VERSION ""

NS_ :

BS_:

BU_: AGSM BCM BSM CDCM DASM DCSM DCTM DIAG_TEST DTCM ECM ECM2 IPC ORC RFHM TBM TCM

BO_ 599 AIRBAG1: 8 ORC
 SG_ AirBagFailSts : 7|2@0+ (1,0) [0|3] "-" IPC,TBM
 SG_ PsngrBagChargeSts : 5|2@0+ (1,0) [0|2] "-" IPC
 SG_ SBR1RowCentralSeatBuckleFailSts : 0|2@0+ (1,0) [0|2] "" BSM,DASM,IPC,TBM
 SG_ SBR1RowCentralSeatConfigSts : 1|1@0+ (1,0) [0|1] "-" BSM,DASM,IPC,TBM
 SG_ SBR1RowCentralSeatPPDFailSts : 14|2@0+ (1,0) [0|2] "" BSM,DASM,IPC,TBM
 SG_ SBR1RowCentralSeatSts : 12|3@0+ (1,0) [0|6] "-" BSM,DASM,IPC,TBM
 SG_ SBR1RowDriverSeatConfigSts : 9|1@0+ (1,0) [0|1] "-" BSM,DASM,IPC,TBM
 SG_ SBR1RowDriverSeatFailSts : 8|2@0+ (1,0) [0|2] "" BSM,DASM,IPC,TBM
 SG_ SBR1RowDriverSeatSts : 22|2@0+ (1,0) [0|2] "-" BSM,DASM,DCTM,IPC,TBM,TCM
 SG_ SBR1RowPsngrSeatBuckleFailSts : 19|2@0+ (1,0) [0|2] "" BSM,DASM,IPC,TBM
 SG_ SBR1RowPsngrSeatConfigSts : 20|1@0+ (1,0) [0|1] "-" BSM,DASM,IPC,TBM
 SG_ SBR1RowPsngrSeatPPDFailSts : 17|2@0+ (1,0) [0|2] "" BSM,DASM,IPC,TBM
 SG_ SBR1RowPsngrSeatSts : 31|3@0+ (1,0) [0|6] "-" BSM,DASM,IPC,TBM
 SG_ SBR2RowCentralSeatConfigSts : 28|1@0+ (1,0) [0|1] "-" IPC,TBM
 SG_ SBR2RowCentralSeatSts : 25|2@0+ (1,0) [0|2] "-" IPC,TBM
 SG_ SBR2RowLeftSeatConfigSts : 39|1@0+ (1,0) [0|1] "-" IPC,TBM
 SG_ SBR2RowLeftSeatSts : 36|2@0+ (1,0) [0|2] "-" IPC,TBM
 SG_ SBR2RowRightSeatConfigSts : 34|1@0+ (1,0) [0|1] "-" IPC,TBM
 SG_ SBR2RowRightSeatSts : 47|2@0+ (1,0) [0|2] "-" IPC,TBM

BO_ 1447 AIRBAG2: 8 ORC
 SG_ CRC_A2 : 63|8@0+ (1,0) [0|255] "" BSM,ECM
 SG_ DrvSbltUnFltr : 7|3@0+ (1,0) [0|6] "" BSM,ECM
 SG_ MessageCounter_A2 : 51|4@0+ (1,0) [0|15] "" BSM,ECM

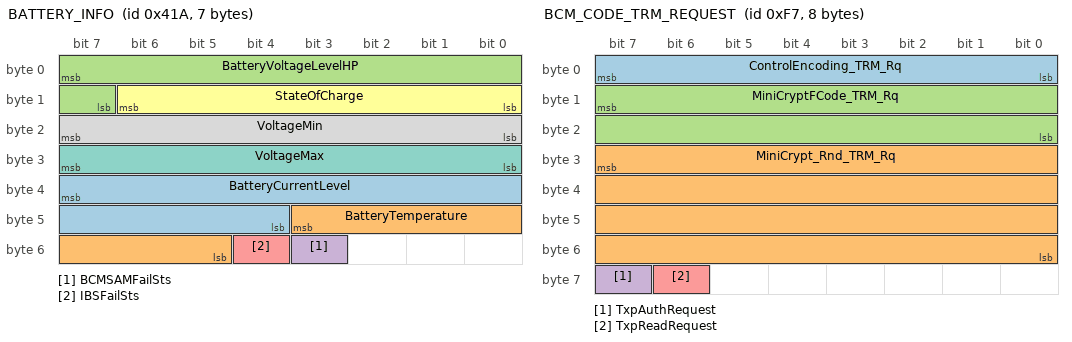
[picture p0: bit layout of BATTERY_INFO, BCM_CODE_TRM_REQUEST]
BO_ 1050 BATTERY_INFO: 7 BCM
 SG_ BatteryCurrentLevel : 39|12@0+ (0.1,-250) [-250|159.5] "A" ECM
 SG_ BatteryTemperature : 43|7@0+ (1,-30) [-30|97] "°C" BCM,ECM
 SG_ BatteryVoltageLevelHP : 7|9@0+ (0.025,4) [4|16.775] "Volt" DTCM,ECM,ORC,RFHM
 SG_ BCMSAMFailSts : 51|1@0+ (1,0) [0|1] "-" ECM
 SG_ IBSFailSts : 52|1@0+ (1,0) [0|1] "-" ECM
 SG_ StateOfCharge : 14|7@0+ (1,0) [0|127] "%" DCTM,ECM,TCM
 SG_ VoltageMax : 31|8@0+ (0.025,10.6) [10.6|16.975] "Volt" ECM
 SG_ VoltageMin : 23|8@0+ (0.025,10.6) [10.6|16.975] "Volt" ECM

BO_ 247 BCM_CODE_TRM_REQUEST: 8 BCM
 SG_ ControlEncoding_TRM_Rq : 7|8@0+ (1,0) [0|255] "-" RFHM
 SG_ MiniCrypt_Rnd_TRM_Rq : 31|32@0+ (1,0) [0|4294967295] "-" RFHM
 SG_ MiniCryptFCode_TRM_Rq : 15|16@0+ (1,0) [0|65535] "-" RFHM
 SG_ TxpAuthRequest : 63|1@0+ (1,0) [0|1] "-" RFHM
 SG_ TxpReadRequest : 62|1@0+ (1,0) [0|1] "-" RFHM

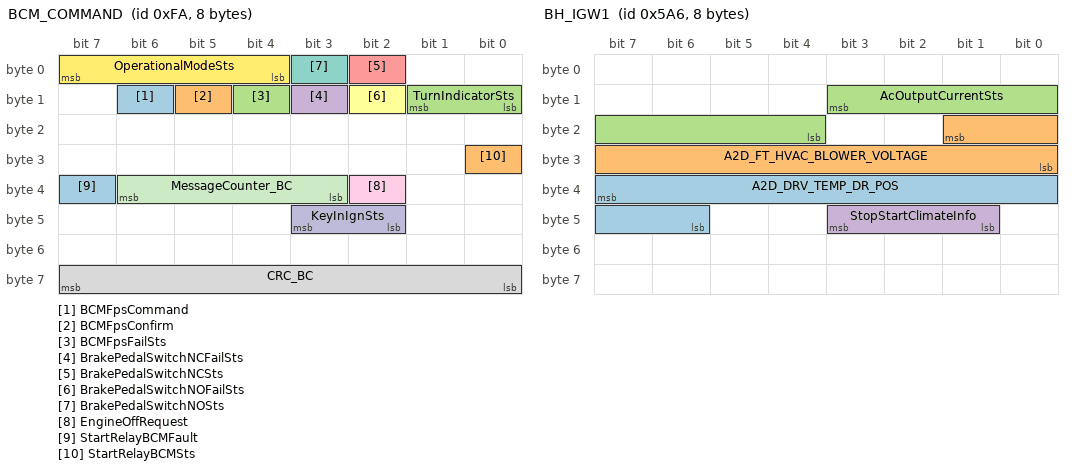
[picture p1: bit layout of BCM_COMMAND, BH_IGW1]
BO_ 250 BCM_COMMAND: 8 BCM
 SG_ BCMFpsCommand : 14|1@0+ (1,0) [0|1] "-" ECM
 SG_ BCMFpsConfirm : 13|1@0+ (1,0) [0|1] "-" ECM
 SG_ BCMFpsFailSts : 12|1@0+ (1,0) [0|1] "-" ECM
 SG_ BrakePedalSwitchNCFailSts : 11|1@0+ (1,0) [0|1] "-" DASM
 SG_ BrakePedalSwitchNCSts : 2|1@0+ (1,0) [0|1] "-" DASM
 SG_ BrakePedalSwitchNOFailSts : 10|1@0+ (1,0) [0|1] "-" DASM
 SG_ BrakePedalSwitchNOSts : 3|1@0+ (1,0) [0|1] "-" DASM
 SG_ CRC_BC : 63|8@0+ (1,0) [0|255] "" AGSM,DASM,DCSM,DCTM,DTCM,ECM,RFHM,TCM
 SG_ EngineOffRequest : 34|1@0+ (1,0) [0|1] "-" ECM
 SG_ KeyInIgnSts : 43|2@0+ (1,0) [0|2] "" RFHM
 SG_ MessageCounter_BC : 38|4@0+ (1,0) [0|15] "-" AGSM,DASM,DCSM,DCTM,DTCM,ECM,RFHM,TCM
 SG_ OperationalModeSts : 7|4@0+ (1,0) [0|15] "" AGSM,CDCM,DASM,DCSM,DCTM,DTCM,ECM,ECM2,IPC,RFHM,TCM
 SG_ StartRelayBCMFault : 39|1@0+ (1,0) [0|1] "" ECM
 SG_ StartRelayBCMSts : 24|1@0+ (1,0) [0|1] "" ECM
 SG_ TurnIndicatorSts : 9|2@0+ (1,0) [0|3] "-" DASM

BO_ 1994 BCM_IGNITION_ON_COUNTER: 2 BCM
 SG_ IgnitionOnCounter : 7|16@0+ (1,0) [0|65535] "-" AGSM,DASM,DCSM,DCTM,DTCM,ECM,IPC,RFHM,TCM

BO_ 245 BCM_MINICRYPT_ACK: 1 BCM
 SG_ MinicryptReceptionSts : 7|1@0+ (1,0) [0|1] "-" RFHM

BO_ 1446 BH_IGW1: 8 BCM
 SG_ A2D_DRV_TEMP_DR_POS : 39|10@0+ (0.0048828125,0) [0|4.9951171875] "Volt" ECM
 SG_ A2D_FT_HVAC_BLOWER_VOLTAGE : 17|10@0+ (0.0048828125,0) [0|4.9951171875] "Volt" ECM
 SG_ AcOutputCurrentSts : 11|8@0+ (0.008,0) [0|2.04] "A" ECM
 SG_ StopStartClimateInfo : 43|3@0+ (1,0) [0|5] "-" ECM

BO_ 748 BODY1: 8 BCM
 SG_ FrontWiperMoveSts : 21|1@0+ (1,0) [0|1] "" ECM
 SG_ RemStartActiveEPB : 20|1@0+ (1,0) [0|1] "" BSM

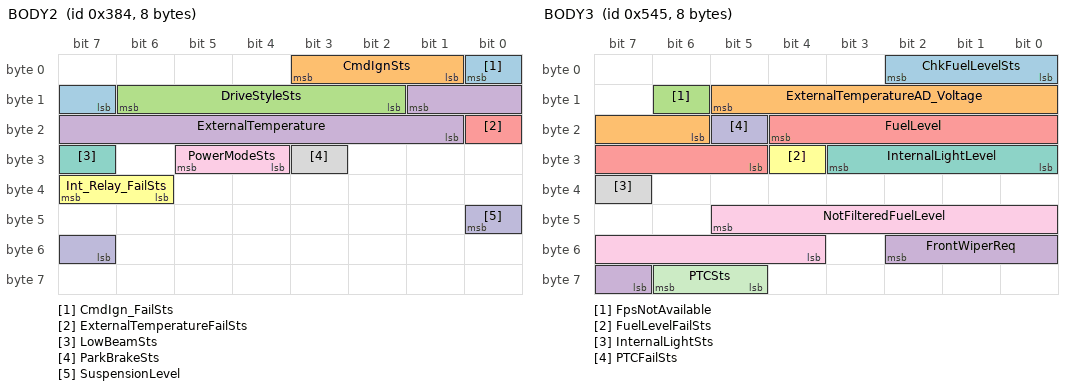
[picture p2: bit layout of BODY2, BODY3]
BO_ 900 BODY2: 8 BCM
 SG_ CmdIgn_FailSts : 0|2@0+ (1,0) [0|3] "" AGSM,CDCM,DASM,DCSM,DCTM,DTCM,ECM,ECM2,IPC,RFHM,TCM
 SG_ CmdIgnSts : 3|3@0+ (1,0) [0|7] "" AGSM,CDCM,DASM,DCSM,DCTM,DTCM,ECM,ECM2,IPC,RFHM,TCM
 SG_ DriveStyleSts : 14|5@0+ (1,0) [0|31] "-" CDCM,DASM,DCTM,DTCM,ECM,IPC,TCM
 SG_ ExternalTemperature : 9|9@0+ (0.5,-85) [-85|170] "°C" CDCM,DCTM,DTCM,ECM,RFHM,TCM
 SG_ ExternalTemperatureFailSts : 16|1@0+ (1,0) [0|1] "" CDCM,DCTM,DTCM,ECM,RFHM,TCM
 SG_ Int_Relay_FailSts : 39|2@0+ (1,0) [0|2] "" Vector__XXX
 SG_ LowBeamSts : 31|1@0+ (1,0) [0|1] "" RFHM
 SG_ ParkBrakeSts : 27|1@0+ (1,0) [0|1] "-" ECM,TCM
 SG_ PowerModeSts : 29|2@0+ (1,0) [0|3] "-" ECM,IPC,RFHM
 SG_ SuspensionLevel : 40|2@0+ (1,0) [0|1] "-" CDCM

BO_ 1349 BODY3: 8 BCM
 SG_ ChkFuelLevelSts : 2|3@0+ (1,0) [0|7] "-" ECM
 SG_ ExternalTemperatureAD_Voltage : 13|8@0+ (0.019607843,0) [0|4.9999992] "Volt" ECM
 SG_ FpsNotAvailable : 14|1@0+ (1,0) [0|1] "" IPC
 SG_ FrontWiperReq : 50|4@0+ (1,0) [0|3] "" BSM,CDCM
 SG_ FuelLevel : 20|8@0+ (1,0) [0|255] "%" ECM,IPC,ORC
 SG_ FuelLevelFailSts : 28|1@0+ (1,0) [0|1] "" ECM,IPC
 SG_ InternalLightLevel : 27|4@0+ (1,0) [0|15] "-" AGSM,DCSM,IPC,RFHM
 SG_ InternalLightSts : 39|1@0+ (1,0) [0|1] "-" AGSM,DCSM,IPC,ORC,RFHM,TBM
 SG_ NotFilteredFuelLevel : 45|10@0+ (2,0) [0|835.7] "Ohm" ECM
 SG_ PTCFailSts : 21|1@0+ (1,0) [0|1] "-" ECM
 SG_ PTCSts : 62|2@0+ (1,0) [0|3] "-" ECM

BO_ 1201 BODY4: 8 BCM
 SG_ BatteryStateOfFunction : 28|6@0+ (0.09375,6) [6|11.90625] "V" ECM
 SG_ BonnetSts : 4|1@0+ (1,0) [0|1] "" Vector__XXX
 SG_ CompressorACReqSts : 37|1@0+ (1,0) [0|1] "-" ECM
 SG_ DriverDoorFailSts : 3|1@0+ (1,0) [0|1] "-" Vector__XXX
 SG_ DriverDoorSts : 0|1@0+ (1,0) [0|1] "" BSM,DCTM,IPC,RFHM,TCM
 SG_ ExteriorRearReleaseSwitchSts : 33|1@0+ (1,0) [0|1] "" RFHM
 SG_ FHeatedWindowSts : 10|1@0+ (1,0) [0|1] "" ECM
 SG_ FOBSearchRequest : 2|2@0+ (1,0) [0|3] "" RFHM
 SG_ LHRDoorSts : 14|1@0+ (1,0) [0|1] "-" RFHM
 SG_ PsngrDoorSts : 15|1@0+ (1,0) [0|1] "-" RFHM
 SG_ Recalibration : 35|1@0+ (1,0) [0|1] "" BCM,ECM,IPC
 SG_ RemSt_InhibitSts : 19|6@0+ (1,0) [0|62] "" IPC
 SG_ RemStActvSts : 29|1@0+ (1,0) [0|1] "" DCTM,ECM,IPC,ORC,RFHM,TCM
 SG_ RHatchSts : 12|1@0+ (1,0) [0|1] "-" RFHM
 SG_ RHeatedWindowSts : 11|1@0+ (1,0) [0|1] "" ECM
 SG_ RHRDoorSts : 13|1@0+ (1,0) [0|1] "-" RFHM
 SG_ SpSt_Pad1 : 45|3@0+ (1,0) [0|7] "" ECM,TCM
 SG_ TheftAlarmStatus : 22|3@0+ (1,0) [0|6] "" RFHM

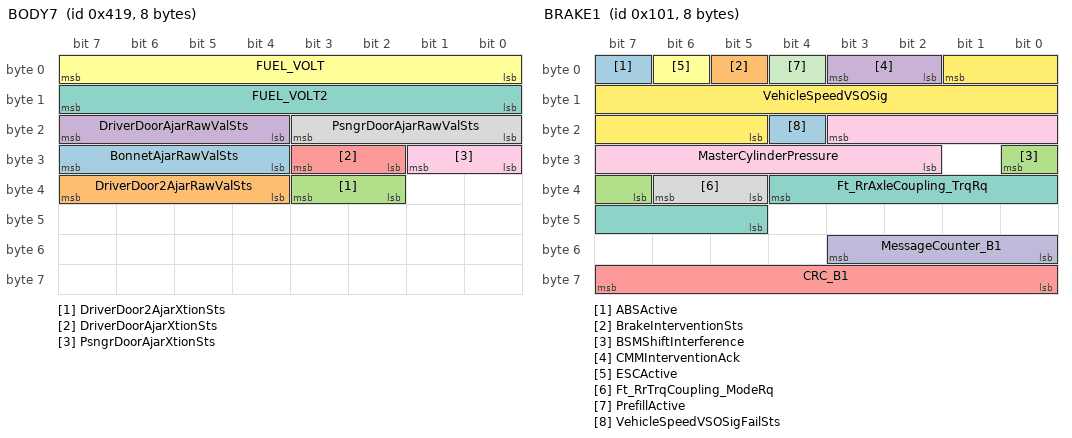
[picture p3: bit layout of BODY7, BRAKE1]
BO_ 1049 BODY7: 8 BCM
 SG_ BonnetAjarRawValSts : 31|4@0+ (1,0) [0|15] "" ECM
 SG_ DriverDoor2AjarRawValSts : 39|4@0+ (1,0) [0|14] "-" ECM
 SG_ DriverDoor2AjarXtionSts : 35|2@0+ (1,0) [0|1] "-" ECM
 SG_ DriverDoorAjarRawValSts : 23|4@0+ (1,0) [0|15] "" ECM
 SG_ DriverDoorAjarXtionSts : 27|2@0+ (1,0) [0|1] "-" ECM
 SG_ FUEL_VOLT : 7|8@0+ (0.019607843,0) [0|4.98] "Volt" ECM
 SG_ FUEL_VOLT2 : 15|8@0+ (0.019607843,0) [0|4.98] "Volt" Vector__XXX
 SG_ PsngrDoorAjarRawValSts : 19|4@0+ (1,0) [0|15] "" ECM
 SG_ PsngrDoorAjarXtionSts : 25|2@0+ (1,0) [0|1] "-" ECM

BO_ 497 BRAKE_TRANSM1: 8 BSM
 SG_ BrkBstrVac : 7|8@0+ (0.55,-119.7) [0|20] "kPa" ORC

BO_ 257 BRAKE1: 8 BSM
 SG_ ABSActive : 7|1@0+ (1,0) [0|1] "" CDCM,DASM,DCTM,DTCM,ECM,ORC,TCM
 SG_ BrakeInterventionSts : 5|1@0+ (1,0) [0|1] "" DASM,DCTM,DTCM,ECM,ORC,TCM
 SG_ BSMShiftInterference : 24|2@0+ (1,0) [0|2] "" DCTM,TCM
 SG_ CMMInterventionAck : 3|2@0+ (1,0) [0|3] "" DASM
 SG_ CRC_B1 : 63|8@0+ (1,0) [0|255] "" BCM,CDCM,DASM,DCTM,DTCM,ECM,RFHM,TCM
 SG_ ESCActive : 6|1@0+ (1,0) [0|1] "" CDCM,DASM,DCTM,DTCM,ECM,ORC,TCM
 SG_ Ft_RrAxleCoupling_TrqRq : 36|8@0+ (12,0) [0|3060] "Nm" CDCM,DTCM
 SG_ Ft_RrTrqCoupling_ModeRq : 38|2@0+ (1,0) [0|3] "" CDCM,DTCM
 SG_ MasterCylinderPressure : 19|10@0+ (0.25,0) [0|255.5] "bar" CDCM,DASM,DCTM,DTCM,ECM,ORC,TCM
 SG_ MessageCounter_B1 : 51|4@0+ (1,0) [0|15] "" BCM,CDCM,DASM,DCTM,DTCM,ECM,RFHM,TCM
 SG_ PrefillActive : 4|1@0+ (1,0) [0|1] "" DASM,ORC
 SG_ VehicleSpeedVSOSig : 1|13@0+ (0.0625,0) [0|511.875] "Km/h" BCM,DASM,DCTM,ECM,IPC,ORC,RFHM,TBM,TCM
 SG_ VehicleSpeedVSOSigFailSts : 20|1@0+ (1,0) [0|1] "" BCM,DASM,DCTM,ECM,IPC,ORC,RFHM,TBM,TCM

BO_ 506 BRAKE10: 8 BSM
 SG_ BrkPrss_One : 7|10@0+ (0.00488,0) [0|4.995] "V" ECM

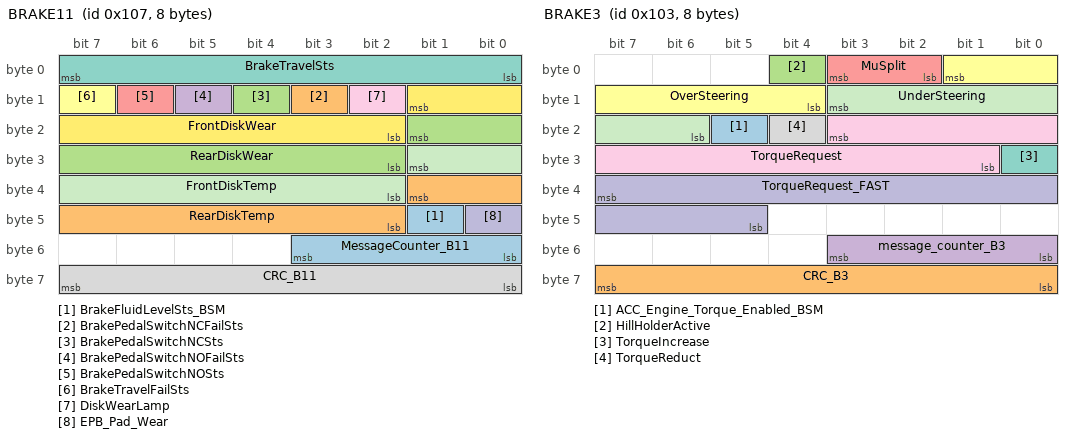
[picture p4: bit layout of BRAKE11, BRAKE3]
BO_ 263 BRAKE11: 8 BSM
 SG_ BrakeFluidLevelSts_BSM : 41|1@0+ (1,0) [0|1] "" BCM,IPC
 SG_ BrakePedalSwitchNCFailSts : 11|1@0+ (1,0) [0|1] "" BCM,CDCM,DASM,DCTM,DTCM,ECM,RFHM,TCM
 SG_ BrakePedalSwitchNCSts : 12|1@0+ (1,0) [0|1] "" BCM,CDCM,DASM,DCTM,DTCM,ECM,RFHM,TCM
 SG_ BrakePedalSwitchNOFailSts : 13|1@0+ (1,0) [0|1] "" BCM,CDCM,DASM,DCTM,DTCM,ECM,RFHM,TCM
 SG_ BrakePedalSwitchNOSts : 14|1@0+ (1,0) [0|1] "" BCM,CDCM,DASM,DCTM,DTCM,ECM,RFHM,TCM
 SG_ BrakeTravelFailSts : 15|1@0+ (1,0) [0|1] "" BCM,DCTM,ECM,TCM
 SG_ BrakeTravelSts : 7|8@0+ (0.4,0) [0|100] "%" BCM,DCTM,ECM,TCM
 SG_ CRC_B11 : 63|8@0+ (1,0) [0|255] "" BCM,CDCM,DASM,DCTM,DTCM,ECM,RFHM,TCM
 SG_ DiskWearLamp : 10|1@0+ (1,0) [0|1] "" IPC
 SG_ EPB_Pad_Wear : 40|1@0+ (1,0) [0|1] "" IPC
 SG_ FrontDiskTemp : 25|8@0+ (3.13,0) [0|800] "°C" BCM
 SG_ FrontDiskWear : 9|8@0+ (0.25,0) [0|63.75] "%" Vector__XXX
 SG_ MessageCounter_B11 : 51|4@0+ (1,0) [0|15] "" BCM,CDCM,DASM,DCTM,DTCM,ECM,RFHM,TCM
 SG_ RearDiskTemp : 33|8@0+ (3.13,0) [0|800] "°C" BCM
 SG_ RearDiskWear : 17|8@0+ (0.25,0) [0|63.75] "%" Vector__XXX

BO_ 259 BRAKE3: 8 BSM
 SG_ ACC_Engine_Torque_Enabled_BSM : 21|1@0+ (1,0) [0|1] "-" ECM
 SG_ CRC_B3 : 63|8@0+ (1,0) [0|255] "" CDCM,DASM,DCTM,ECM,TCM
 SG_ HillHolderActive : 4|1@0+ (1,0) [0|1] "" DCTM,ECM,ORC,TCM
 SG_ message_counter_B3 : 51|4@0+ (1,0) [0|15] "" CDCM,DASM,DCTM,ECM,TCM
 SG_ MuSplit : 3|2@0+ (1,0) [0|2] "" CDCM
 SG_ OverSteering : 1|6@0+ (2,0) [0|124] "%" Vector__XXX
 SG_ TorqueIncrease : 24|1@0+ (1,0) [0|1] "" DCTM,ECM,ORC,TCM
 SG_ TorqueReduct : 20|1@0+ (1,0) [0|1] "" DCTM,ECM,ORC,TCM
 SG_ TorqueRequest : 19|11@0+ (1,-500) [-500|1546] "" DCTM,ECM,ORC,TCM
 SG_ TorqueRequest_FAST : 39|11@0+ (1,-500) [-500|1546] "" ECM
 SG_ UnderSteering : 11|6@0+ (2,0) [0|124] "%" Vector__XXX

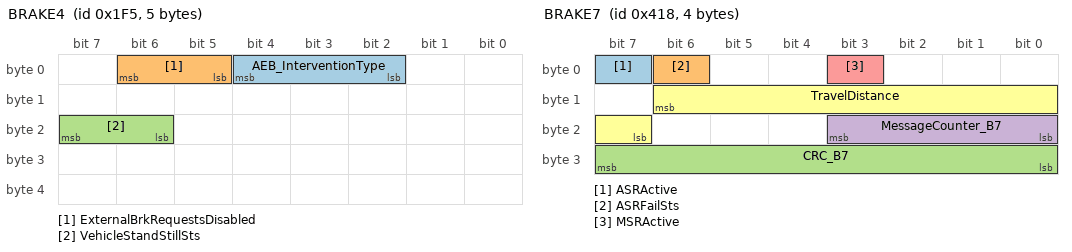
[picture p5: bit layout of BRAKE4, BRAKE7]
BO_ 501 BRAKE4: 5 BSM
 SG_ AEB_InterventionType : 4|3@0+ (1,0) [0|7] "" DASM,ORC
 SG_ ExternalBrkRequestsDisabled : 6|2@0+ (1,0) [0|2] "" DASM
 SG_ VehicleStandStillSts : 23|2@0+ (1,0) [0|2] "" CDCM,DASM,ECM

BO_ 498 BRAKE6: 8 BSM
 SG_ ACCFSafe : 7|8@0+ (1,0) [0|255] "" DASM
 SG_ Brk_Jrk_Resp : 13|1@0+ (1,0) [0|1] "-" DASM,ORC
 SG_ Brk_Thermdl : 12|1@0+ (1,0) [0|1] "" DASM

BO_ 1048 BRAKE7: 4 BSM
 SG_ ASRActive : 7|1@0+ (1,0) [0|1] "-" CDCM,DASM,DCTM,ECM,ORC,TCM
 SG_ ASRFailSts : 6|1@0+ (1,0) [0|1] "" CDCM
 SG_ CRC_B7 : 31|8@0+ (1,0) [0|255] "" CDCM,DASM,DCTM,ECM,TCM
 SG_ MessageCounter_B7 : 19|4@0+ (1,0) [0|15] "" CDCM,DASM,DCTM,ECM,TCM
 SG_ MSRActive : 3|1@0+ (1,0) [0|1] "-" DASM,DCTM,ECM,ORC,TCM
 SG_ TravelDistance : 14|8@0+ (1,0) [0|255] "m" BCM,ECM,IPC,ORC

BO_ 1199 BRAKE8: 8 BSM
 SG_ ABSFailSts : 7|1@0+ (1,0) [0|1] "-" CDCM,DCTM,DTCM,IPC,ORC,TCM
 SG_ ACCEngaged : 11|1@0+ (1,0) [0|1] "" ECM,TCM
 SG_ BSM_BLC_Active : 26|1@0+ (1,0) [0|1] "" BCM
 SG_ BSMSysSts : 47|2@0+ (1,0) [0|3] "" DASM,DCTM,ECM,TCM
 SG_ CMMIntervention : 6|1@0+ (1,0) [0|1] "-" ECM
 SG_ DSTFailSts : 5|1@0+ (1,0) [0|1] "-" BCM,IPC,ORC
 SG_ EBDFailSts : 4|1@0+ (1,0) [0|1] "-" IPC,ORC
 SG_ ERMActive : 33|1@0+ (1,0) [0|1] "" DASM,ORC
 SG_ ESCFailSts : 2|1@0+ (1,0) [0|1] "-" BCM,CDCM,DASM,DCTM,DTCM,IPC,ORC,TCM
 SG_ ESCIntervention : 3|1@0+ (1,0) [0|1] "-" DCTM,IPC,ORC,TCM
 SG_ Function2Sts : 10|1@0+ (1,0) [0|1] "-" CDCM,DASM,IPC
 SG_ FunctionFailSts : 15|1@0+ (1,0) [0|1] "-" IPC
 SG_ FunctionIntervention : 1|1@0+ (1,0) [0|1] "-" IPC,ORC
 SG_ FunctionSts : 0|1@0+ (1,0) [0|1] "-" DASM,DCTM,DTCM,IPC,ORC,TCM
 SG_ HillHolderFailSts : 14|1@0+ (1,0) [0|1] "-" IPC,ORC
 SG_ RollsModeAct : 12|1@0+ (1,0) [0|1] "" BCM,DASM,ECM
 SG_ TSCActive : 32|1@0+ (1,0) [0|1] "" DASM,ORC

BO_ 1453 BRAKE9: 8 BSM
 SG_ DsblFuelShutOff_ACC_BSM : 15|1@0+ (1,0) [0|1] "-" ECM

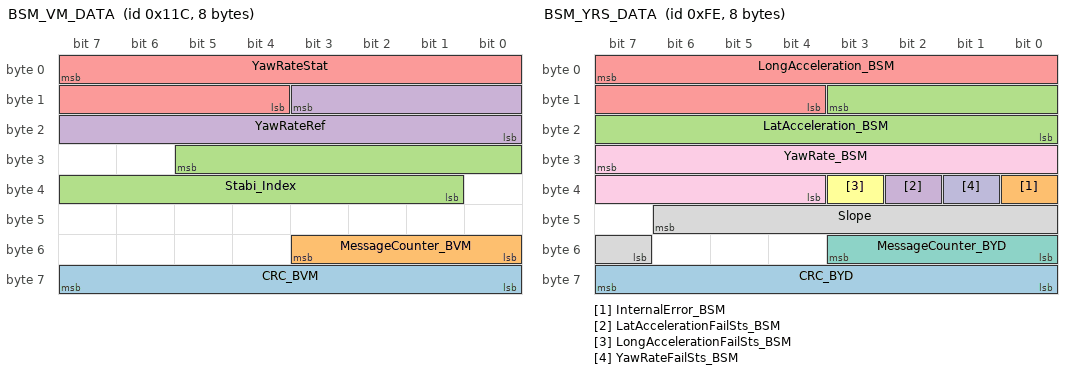
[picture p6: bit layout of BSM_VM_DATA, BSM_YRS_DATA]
BO_ 284 BSM_VM_DATA: 8 BSM
 SG_ CRC_BVM : 63|8@0+ (1,0) [0|255] "-" Vector__XXX
 SG_ MessageCounter_BVM : 51|4@0+ (1,0) [0|15] "-" Vector__XXX
 SG_ Stabi_Index : 29|13@0+ (0.08,-100) [-100|555.28] "%" Vector__XXX
 SG_ YawRateRef : 11|12@0+ (0.08,-93) [-93|234.52] "deg/s" Vector__XXX
 SG_ YawRateStat : 7|12@0+ (0.08,-93) [-93|234.52] "deg/s" Vector__XXX

BO_ 254 BSM_YRS_DATA: 8 BSM
 SG_ CRC_BYD : 63|8@0+ (1,0) [0|255] "-" BCM,DASM,DCTM,DTCM,ECM,TCM
 SG_ InternalError_BSM : 32|1@0+ (1,0) [0|1] "-" Vector__XXX
 SG_ LatAcceleration_BSM : 11|12@0+ (0.02,-40.96) [-40.96|40.92] "m/s^2" BCM,DCTM,DTCM,ECM,IPC,TCM
 SG_ LatAccelerationFailSts_BSM : 34|1@0+ (1,0) [0|1] "-" BCM,DCTM,DTCM,IPC,TCM
 SG_ LongAcceleration_BSM : 7|12@0+ (0.02,-40.96) [-40.96|40.92] "m/s^2" BCM,DASM,DCTM,ECM,IPC,TCM
 SG_ LongAccelerationFailSts_BSM : 35|1@0+ (1,0) [0|1] "-" BCM,DASM,DCTM,ECM,IPC,TCM
 SG_ MessageCounter_BYD : 51|4@0+ (1,0) [0|15] "-" BCM,DASM,DCTM,DTCM,ECM,TCM
 SG_ Slope : 46|8@0+ (1,-100) [-100|154] "%" BCM,DCTM,ECM,TCM
 SG_ YawRate_BSM : 31|12@0+ (0.08,-163.84) [-163.84|163.68] "deg/s" BCM,DASM,DTCM,ORC
 SG_ YawRateFailSts_BSM : 33|1@0+ (1,0) [0|1] "-" BCM,DASM,DTCM

BO_ 1451 C2_IGW1: 8 BCM
 SG_ TorqueOverlayIntActivation_SPM : 0|1@0+ (1,0) [0|1] "" DASM

BO_ 288 CDCM3: 6 CDCM
 SG_ CRC_EC : 31|8@0+ (1,0) [0|255] "" DTCM,ECM
 SG_ CutAdvice : 5|2@0+ (1,0) [0|3] "-" ECM
 SG_ MessageCounter_EC : 19|4@0+ (1,0) [0|15] "-" DTCM,ECM

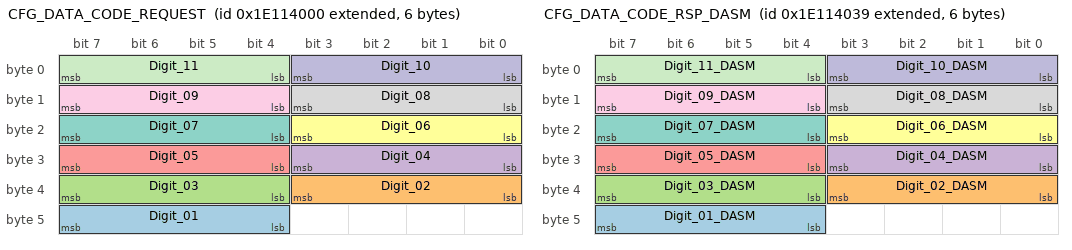
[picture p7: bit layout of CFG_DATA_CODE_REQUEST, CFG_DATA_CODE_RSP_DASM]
BO_ 2651930624 CFG_DATA_CODE_REQUEST: 6 BCM
 SG_ Digit_01 : 47|4@0+ (1,0) [0|15] "" AGSM,DASM,DCSM,DTCM,ECM,ECM2,IPC,RFHM,TCM
 SG_ Digit_02 : 35|4@0+ (1,0) [0|15] "" AGSM,DASM,DCSM,DTCM,ECM,ECM2,IPC,RFHM,TCM
 SG_ Digit_03 : 39|4@0+ (1,0) [0|15] "" AGSM,DASM,DCSM,DTCM,ECM,ECM2,IPC,RFHM,TCM
 SG_ Digit_04 : 27|4@0+ (1,0) [0|15] "" AGSM,DASM,DCSM,DTCM,ECM,ECM2,IPC,RFHM,TCM
 SG_ Digit_05 : 31|4@0+ (1,0) [0|15] "" AGSM,DASM,DCSM,DTCM,ECM,ECM2,IPC,RFHM,TCM
 SG_ Digit_06 : 19|4@0+ (1,0) [0|15] "" AGSM,DASM,DCSM,DTCM,ECM,ECM2,IPC,RFHM,TCM
 SG_ Digit_07 : 23|4@0+ (1,0) [0|15] "" AGSM,DASM,DCSM,DTCM,ECM,ECM2,IPC,RFHM,TCM
 SG_ Digit_08 : 11|4@0+ (1,0) [0|15] "" AGSM,DASM,DCSM,DTCM,ECM,ECM2,IPC,RFHM,TCM
 SG_ Digit_09 : 15|4@0+ (1,0) [0|15] "" AGSM,DASM,DCSM,DTCM,ECM,ECM2,IPC,RFHM,TCM
 SG_ Digit_10 : 3|4@0+ (1,0) [0|15] "" AGSM,DASM,DCSM,DTCM,ECM,ECM2,IPC,RFHM,TCM
 SG_ Digit_11 : 7|4@0+ (1,0) [0|15] "" AGSM,DASM,DCSM,DTCM,ECM,ECM2,IPC,RFHM,TCM

BO_ 2651930681 CFG_DATA_CODE_RSP_DASM: 6 DASM
 SG_ Digit_01_DASM : 47|4@0+ (1,0) [0|15] "-" BCM
 SG_ Digit_02_DASM : 35|4@0+ (1,0) [0|15] "-" BCM
 SG_ Digit_03_DASM : 39|4@0+ (1,0) [0|15] "-" BCM
 SG_ Digit_04_DASM : 27|4@0+ (1,0) [0|15] "-" BCM
 SG_ Digit_05_DASM : 31|4@0+ (1,0) [0|15] "-" BCM
 SG_ Digit_06_DASM : 19|4@0+ (1,0) [0|15] "-" BCM
 SG_ Digit_07_DASM : 23|4@0+ (1,0) [0|15] "-" BCM
 SG_ Digit_08_DASM : 11|4@0+ (1,0) [0|15] "-" BCM
 SG_ Digit_09_DASM : 15|4@0+ (1,0) [0|15] "-" BCM
 SG_ Digit_10_DASM : 3|4@0+ (1,0) [0|15] "-" BCM
 SG_ Digit_11_DASM : 7|4@0+ (1,0) [0|15] "-" BCM

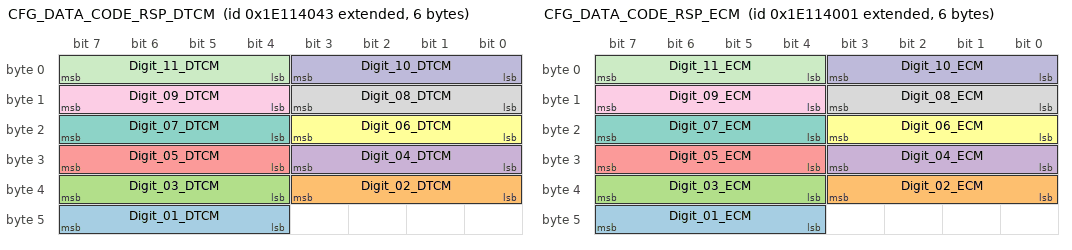
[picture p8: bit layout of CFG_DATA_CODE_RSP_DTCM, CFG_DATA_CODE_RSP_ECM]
BO_ 2651930691 CFG_DATA_CODE_RSP_DTCM: 6 DTCM
 SG_ Digit_01_DTCM : 47|4@0+ (1,0) [0|15] "-" BCM
 SG_ Digit_02_DTCM : 35|4@0+ (1,0) [0|15] "-" BCM
 SG_ Digit_03_DTCM : 39|4@0+ (1,0) [0|15] "-" BCM
 SG_ Digit_04_DTCM : 27|4@0+ (1,0) [0|15] "-" BCM
 SG_ Digit_05_DTCM : 31|4@0+ (1,0) [0|15] "-" BCM
 SG_ Digit_06_DTCM : 19|4@0+ (1,0) [0|15] "-" BCM
 SG_ Digit_07_DTCM : 23|4@0+ (1,0) [0|15] "-" BCM
 SG_ Digit_08_DTCM : 11|4@0+ (1,0) [0|15] "-" BCM
 SG_ Digit_09_DTCM : 15|4@0+ (1,0) [0|15] "-" BCM
 SG_ Digit_10_DTCM : 3|4@0+ (1,0) [0|15] "-" BCM
 SG_ Digit_11_DTCM : 7|4@0+ (1,0) [0|15] "-" BCM

BO_ 2651930625 CFG_DATA_CODE_RSP_ECM: 6 ECM
 SG_ Digit_01_ECM : 47|4@0+ (1,0) [0|15] "-" BCM
 SG_ Digit_02_ECM : 35|4@0+ (1,0) [0|15] "-" BCM
 SG_ Digit_03_ECM : 39|4@0+ (1,0) [0|15] "-" BCM
 SG_ Digit_04_ECM : 27|4@0+ (1,0) [0|15] "-" BCM
 SG_ Digit_05_ECM : 31|4@0+ (1,0) [0|15] "-" BCM
 SG_ Digit_06_ECM : 19|4@0+ (1,0) [0|15] "-" BCM
 SG_ Digit_07_ECM : 23|4@0+ (1,0) [0|15] "-" BCM
 SG_ Digit_08_ECM : 11|4@0+ (1,0) [0|15] "-" BCM
 SG_ Digit_09_ECM : 15|4@0+ (1,0) [0|15] "-" BCM
 SG_ Digit_10_ECM : 3|4@0+ (1,0) [0|15] "-" BCM
 SG_ Digit_11_ECM : 7|4@0+ (1,0) [0|15] "-" BCM

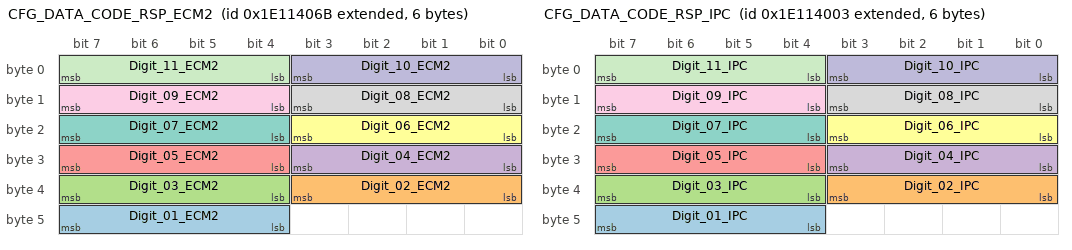
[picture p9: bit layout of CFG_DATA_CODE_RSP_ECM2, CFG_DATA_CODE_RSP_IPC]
BO_ 2651930731 CFG_DATA_CODE_RSP_ECM2: 6 ECM2
 SG_ Digit_01_ECM2 : 47|4@0+ (1,0) [0|15] "-" BCM
 SG_ Digit_02_ECM2 : 35|4@0+ (1,0) [0|15] "-" BCM
 SG_ Digit_03_ECM2 : 39|4@0+ (1,0) [0|15] "-" BCM
 SG_ Digit_04_ECM2 : 27|4@0+ (1,0) [0|15] "-" BCM
 SG_ Digit_05_ECM2 : 31|4@0+ (1,0) [0|15] "-" BCM
 SG_ Digit_06_ECM2 : 19|4@0+ (1,0) [0|15] "-" BCM
 SG_ Digit_07_ECM2 : 23|4@0+ (1,0) [0|15] "-" BCM
 SG_ Digit_08_ECM2 : 11|4@0+ (1,0) [0|15] "-" BCM
 SG_ Digit_09_ECM2 : 15|4@0+ (1,0) [0|15] "-" BCM
 SG_ Digit_10_ECM2 : 3|4@0+ (1,0) [0|15] "-" BCM
 SG_ Digit_11_ECM2 : 7|4@0+ (1,0) [0|15] "-" BCM

BO_ 2651930627 CFG_DATA_CODE_RSP_IPC: 6 IPC
 SG_ Digit_01_IPC : 47|4@0+ (1,0) [0|15] "-" BCM
 SG_ Digit_02_IPC : 35|4@0+ (1,0) [0|15] "-" BCM
 SG_ Digit_03_IPC : 39|4@0+ (1,0) [0|15] "-" BCM
 SG_ Digit_04_IPC : 27|4@0+ (1,0) [0|15] "-" BCM
 SG_ Digit_05_IPC : 31|4@0+ (1,0) [0|15] "-" BCM
 SG_ Digit_06_IPC : 19|4@0+ (1,0) [0|15] "-" BCM
 SG_ Digit_07_IPC : 23|4@0+ (1,0) [0|15] "-" BCM
 SG_ Digit_08_IPC : 11|4@0+ (1,0) [0|15] "-" BCM
 SG_ Digit_09_IPC : 15|4@0+ (1,0) [0|15] "-" BCM
 SG_ Digit_10_IPC : 3|4@0+ (1,0) [0|15] "-" BCM
 SG_ Digit_11_IPC : 7|4@0+ (1,0) [0|15] "-" BCM

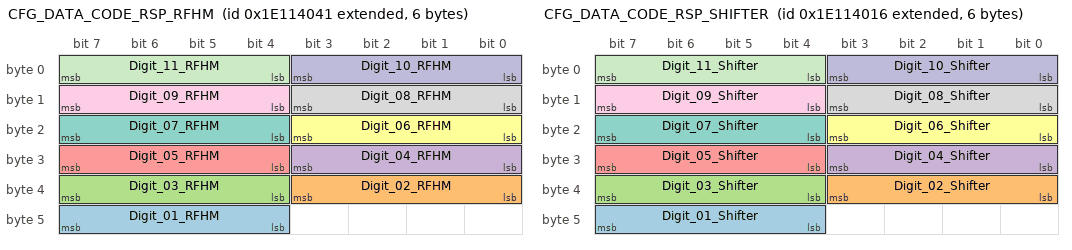
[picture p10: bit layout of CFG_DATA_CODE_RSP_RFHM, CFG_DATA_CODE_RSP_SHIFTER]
BO_ 2651930689 CFG_DATA_CODE_RSP_RFHM: 6 RFHM
 SG_ Digit_01_RFHM : 47|4@0+ (1,0) [0|15] "-" BCM
 SG_ Digit_02_RFHM : 35|4@0+ (1,0) [0|15] "-" BCM
 SG_ Digit_03_RFHM : 39|4@0+ (1,0) [0|15] "-" BCM
 SG_ Digit_04_RFHM : 27|4@0+ (1,0) [0|15] "-" BCM
 SG_ Digit_05_RFHM : 31|4@0+ (1,0) [0|15] "-" BCM
 SG_ Digit_06_RFHM : 19|4@0+ (1,0) [0|15] "-" BCM
 SG_ Digit_07_RFHM : 23|4@0+ (1,0) [0|15] "-" BCM
 SG_ Digit_08_RFHM : 11|4@0+ (1,0) [0|15] "-" BCM
 SG_ Digit_09_RFHM : 15|4@0+ (1,0) [0|15] "-" BCM
 SG_ Digit_10_RFHM : 3|4@0+ (1,0) [0|15] "-" BCM
 SG_ Digit_11_RFHM : 7|4@0+ (1,0) [0|15] "-" BCM

BO_ 2651930646 CFG_DATA_CODE_RSP_SHIFTER: 6 AGSM
 SG_ Digit_01_Shifter : 47|4@0+ (1,0) [0|15] "-" BCM
 SG_ Digit_02_Shifter : 35|4@0+ (1,0) [0|15] "-" BCM
 SG_ Digit_03_Shifter : 39|4@0+ (1,0) [0|15] "-" BCM
 SG_ Digit_04_Shifter : 27|4@0+ (1,0) [0|15] "-" BCM
 SG_ Digit_05_Shifter : 31|4@0+ (1,0) [0|15] "-" BCM
 SG_ Digit_06_Shifter : 19|4@0+ (1,0) [0|15] "-" BCM
 SG_ Digit_07_Shifter : 23|4@0+ (1,0) [0|15] "-" BCM
 SG_ Digit_08_Shifter : 11|4@0+ (1,0) [0|15] "-" BCM
 SG_ Digit_09_Shifter : 15|4@0+ (1,0) [0|15] "-" BCM
 SG_ Digit_10_Shifter : 3|4@0+ (1,0) [0|15] "-" BCM
 SG_ Digit_11_Shifter : 7|4@0+ (1,0) [0|15] "-" BCM

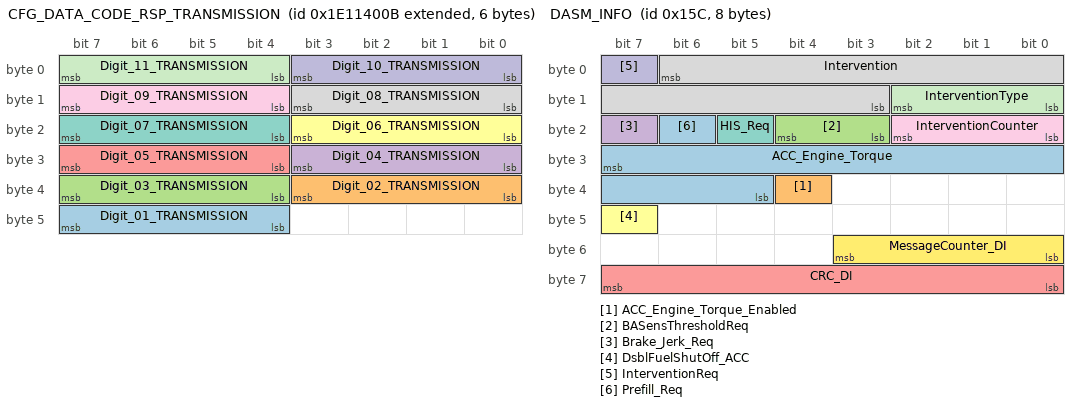
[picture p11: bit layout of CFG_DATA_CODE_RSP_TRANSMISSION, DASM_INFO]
BO_ 2651930635 CFG_DATA_CODE_RSP_TRANSMISSION: 6 TCM
 SG_ Digit_01_TRANSMISSION : 47|4@0+ (1,0) [0|15] "-" BCM
 SG_ Digit_02_TRANSMISSION : 35|4@0+ (1,0) [0|15] "-" BCM
 SG_ Digit_03_TRANSMISSION : 39|4@0+ (1,0) [0|15] "-" BCM
 SG_ Digit_04_TRANSMISSION : 27|4@0+ (1,0) [0|15] "-" BCM
 SG_ Digit_05_TRANSMISSION : 31|4@0+ (1,0) [0|15] "-" BCM
 SG_ Digit_06_TRANSMISSION : 19|4@0+ (1,0) [0|15] "-" BCM
 SG_ Digit_07_TRANSMISSION : 23|4@0+ (1,0) [0|15] "-" BCM
 SG_ Digit_08_TRANSMISSION : 11|4@0+ (1,0) [0|15] "-" BCM
 SG_ Digit_09_TRANSMISSION : 15|4@0+ (1,0) [0|15] "-" BCM
 SG_ Digit_10_TRANSMISSION : 3|4@0+ (1,0) [0|15] "-" BCM
 SG_ Digit_11_TRANSMISSION : 7|4@0+ (1,0) [0|15] "-" BCM

BO_ 601 CLUSTER1: 8 BCM
 SG_ ElectricSteeringLamp_FailSts : 47|2@0+ (1,0) [0|3] "-" BCM,ORC
 SG_ TotalOdometer : 23|20@0+ (1,0) [0|1048575] "km" AGSM,BCM,BSM,CDCM,DASM,DCSM,DCTM,DTCM,ECM,ORC,RFHM,TCM

BO_ 598 CLUSTER2: 8 IPC
 SG_ ABSLamp_FailSts : 7|2@0+ (1,0) [0|3] "-" BSM
 SG_ AirBagLamp_FailSts : 5|2@0+ (1,0) [0|3] "-" ORC
 SG_ DistanceUnit : 16|1@0+ (1,0) [0|1] "" DASM,ECM
 SG_ EBDLamp_FailSts : 3|2@0+ (1,0) [0|3] "-" BSM
 SG_ EPBAutoAppReqSts : 21|2@0+ (1,0) [0|3] "" BSM
 SG_ EPBLamp_FailSts : 9|2@0+ (1,0) [0|3] "" BSM
 SG_ EPBMaintenanceReqSts : 43|2@0+ (1,0) [0|3] "-" BSM
 SG_ ESCLamp_FailSts : 15|2@0+ (1,0) [0|3] "-" BSM
 SG_ FSFCWPlusActivationMode : 41|2@0+ (1,0) [0|1] "" DASM
 SG_ FSFCWPlusSetting : 46|3@0+ (1,0) [0|7] "" DASM
 SG_ HHDisablingCommandSts : 47|1@0+ (1,0) [0|1] "" Vector__XXX
 SG_ PassiveEntry : 35|1@0+ (1,0) [0|1] "" RFHM
 SG_ PowerModeSts_IPC : 37|2@0+ (1,0) [0|3] "" BCM
 SG_ PsngrBagRequestSts : 23|2@0+ (1,0) [0|3] "-" ORC
 SG_ RemoteDoorUnlock : 34|1@0+ (1,0) [0|1] "" RFHM
 SG_ SpeedLimitActivationIPC : 31|1@0+ (1,0) [0|1] "-" DASM,ECM
 SG_ VehicleSpeedSetIPC : 30|9@0+ (0.5,0) [0|255] "km/h" DASM,ECM

BO_ 348 DASM_INFO: 8 DASM
 SG_ ACC_Engine_Torque : 31|11@0+ (1,-500) [-500|1547] "Nm" BSM
 SG_ ACC_Engine_Torque_Enabled : 36|1@0+ (1,0) [0|1] "-" BSM
 SG_ BASensThresholdReq : 20|2@0+ (1,0) [0|3] "-" BSM
 SG_ Brake_Jerk_Req : 23|1@0+ (1,0) [0|1] "-" BSM
 SG_ CRC_DI : 63|8@0+ (1,0) [0|255] "" BSM
 SG_ DsblFuelShutOff_ACC : 47|1@0+ (1,0) [0|1] "-" BSM
 SG_ HIS_Req : 21|1@0+ (1,0) [0|1] "-" BSM,ORC
 SG_ Intervention : 6|12@0+ (0.01,-16) [-16|4.46] "m/s2" BSM,ORC
 SG_ InterventionCounter : 18|3@0+ (1,0) [0|7] "-" BSM
 SG_ InterventionReq : 7|1@0+ (1,0) [0|1] "-" BSM
 SG_ InterventionType : 10|3@0+ (1,0) [0|7] "-" BSM
 SG_ MessageCounter_DI : 51|4@0+ (1,0) [0|15] "" BSM
 SG_ Prefill_Req : 22|1@0+ (1,0) [0|1] "-" BSM,ORC

BO_ 2564554481 DIAGNOSTIC_REQ_FUNC_C1: 8 DIAG_TEST
 SG_ N_PDU : 7|64@0+ (1,0) [0|0] "" AGSM,BCM,DASM,DCSM,DTCM,ECM,ECM2,IPC,RFHM,TCM

BO_ 2564440305 DIAGNOSTIC_REQUEST_BCM: 8 DIAG_TEST
 SG_ N_PDU : 7|64@0+ (1,0) [0|0] "" BCM

BO_ 2564434673 DIAGNOSTIC_REQUEST_DASM: 8 DIAG_TEST
 SG_ N_PDU : 7|64@0+ (1,0) [0|0] "" DASM

BO_ 2564430577 DIAGNOSTIC_REQUEST_DTCM: 8 DIAG_TEST
 SG_ N_PDU : 7|64@0+ (1,0) [0|0] "" DTCM

BO_ 2564428017 DIAGNOSTIC_REQUEST_ECM: 8 DIAG_TEST
 SG_ N_PDU : 7|64@0+ (1,0) [0|0] "" ECM

BO_ 2564429809 DIAGNOSTIC_REQUEST_ECM2: 8 DIAG_TEST
 SG_ N_PDU : 7|64@0+ (1,0) [0|0] "" ECM2

BO_ 2564502513 DIAGNOSTIC_REQUEST_FUNC_OBD: 8 DIAG_TEST
 SG_ N_PDU : 7|64@0+ (1,0) [0|0] "" DCTM,ECM,TCM

BO_ 2564448497 DIAGNOSTIC_REQUEST_IPC: 8 DIAG_TEST
 SG_ N_PDU : 7|64@0+ (1,0) [0|0] "-" IPC

BO_ 2564474865 DIAGNOSTIC_REQUEST_RFHM: 8 DIAG_TEST
 SG_ N_PDU : 7|64@0+ (1,0) [0|0] "" RFHM

BO_ 2564431857 DIAGNOSTIC_REQUEST_SHIFTER: 8 DIAG_TEST
 SG_ N_PDU : 7|64@0+ (1,0) [0|0] "" AGSM,DCSM

BO_ 2564430065 DIAGNOSTIC_REQUEST_TRANSMISSION: 8 DIAG_TEST
 SG_ N_PDU : 7|64@0+ (1,0) [0|0] "" DCTM,TCM

BO_ 2564485440 DIAGNOSTIC_RESPONSE_BCM: 8 BCM
 SG_ N_PDU : 7|64@0+ (1,0) [0|0] "" DIAG_TEST

BO_ 2564485418 DIAGNOSTIC_RESPONSE_DASM: 8 DASM
 SG_ N_PDU : 7|64@0+ (1,0) [0|0] "" DIAG_TEST

BO_ 2564485402 DIAGNOSTIC_RESPONSE_DTCM: 8 DTCM
 SG_ N_PDU : 7|64@0+ (1,0) [0|0] "" DIAG_TEST

BO_ 2564485392 DIAGNOSTIC_RESPONSE_ECM: 8 ECM
 SG_ N_PDU : 7|64@0+ (1,0) [0|0] "" DIAG_TEST

BO_ 2564485399 DIAGNOSTIC_RESPONSE_ECM2: 8 ECM2
 SG_ N_PDU : 7|64@0+ (1,0) [0|0] "" DIAG_TEST

BO_ 2564485472 DIAGNOSTIC_RESPONSE_IPC: 8 IPC
 SG_ N_PDU : 7|64@0+ (1,0) [0|0] "-" DIAG_TEST

BO_ 2564485575 DIAGNOSTIC_RESPONSE_RFHM: 8 RFHM
 SG_ N_PDU : 7|64@0+ (1,0) [0|0] "" DIAG_TEST

BO_ 2564485407 DIAGNOSTIC_RESPONSE_SHIFTER: 8 AGSM
 SG_ N_PDU : 7|64@0+ (1,0) [0|0] "" DIAG_TEST

BO_ 2564485400 DIAGNOSTIC_RESPONSE_TRANSMISSION: 8 DCTM
 SG_ N_PDU : 7|64@0+ (1,0) [0|0] "" DIAG_TEST

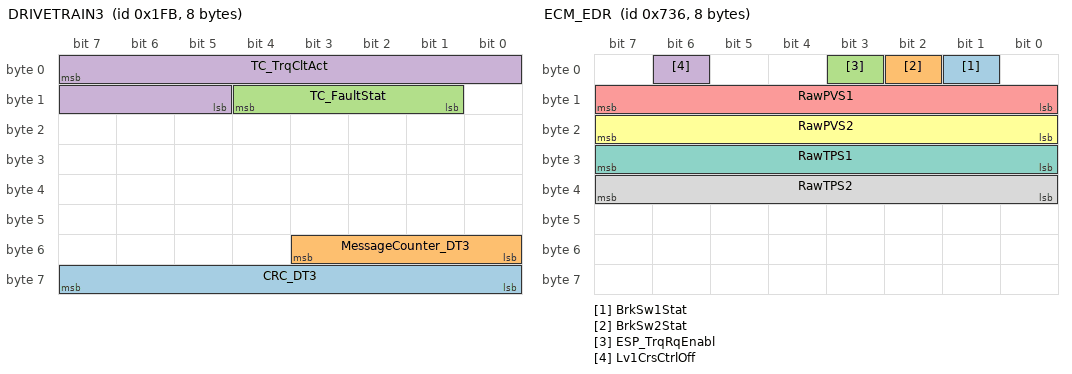
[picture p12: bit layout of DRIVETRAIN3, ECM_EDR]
BO_ 507 DRIVETRAIN3: 8 DTCM
 SG_ CRC_DT3 : 63|8@0+ (1,0) [0|0] "" BSM,CDCM
 SG_ MessageCounter_DT3 : 51|4@0+ (1,0) [0|15] "" BSM,CDCM
 SG_ TC_FaultStat : 12|4@0+ (1,0) [0|15] "Nm" BSM,CDCM,IPC,ORC
 SG_ TC_TrqCltAct : 7|11@0+ (1,0) [1|2047] "Nm" BSM,CDCM,ORC

BO_ 752 ECM_BCM: 4 ECM
 SG_ BatteryVoltageHP : 7|9@0+ (0.025,4) [4|16775] "Volt" BCM
 SG_ IBS_SOC_ECM : 14|7@0+ (1,0) [0|126] "%" BCM

BO_ 1846 ECM_EDR: 8 ECM
 SG_ BrkSw1Stat : 1|1@0+ (1,0) [0|1] "" ORC
 SG_ BrkSw2Stat : 2|1@0+ (1,0) [0|1] "" ORC
 SG_ ESP_TrqRqEnabl : 3|1@0+ (1,0) [0|1] "" ORC
 SG_ Lv1CrsCtrlOff : 6|1@0+ (1,0) [0|1] "" ORC
 SG_ RawPVS1 : 15|8@0+ (0.019607843,0) [0|4.98] "V" ORC
 SG_ RawPVS2 : 23|8@0+ (0.019607843,0) [0|4.98] "V" ORC
 SG_ RawTPS1 : 31|8@0+ (0.019607843,0) [0|4.98] "V" ORC
 SG_ RawTPS2 : 39|8@0+ (0.019607843,0) [0|4.98] "V" ORC

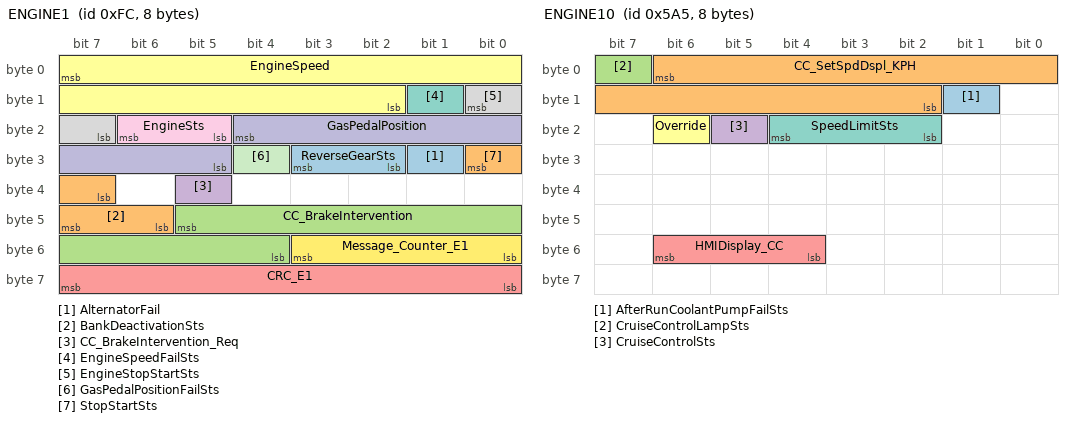
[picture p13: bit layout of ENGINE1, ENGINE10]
BO_ 252 ENGINE1: 8 ECM
 SG_ AlternatorFail : 25|1@0+ (1,0) [0|1] "-" BCM,IPC
 SG_ BankDeactivationSts : 47|2@0+ (1,0) [0|3] "-" CDCM
 SG_ CC_BrakeIntervention : 45|10@0+ (0.01,-10) [-10|0.22] "m/s^2" BSM
 SG_ CC_BrakeIntervention_Req : 37|1@0+ (1,0) [0|1] "" BSM
 SG_ CRC_E1 : 63|8@0+ (1,0) [0|255] "" AGSM,BCM,BSM,CDCM,DASM,DCSM,DCTM,DTCM,RFHM,TCM
 SG_ EngineSpeed : 7|14@0+ (1,0) [0|16382] "1/min" BCM,BSM,CDCM,DASM,DCTM,DTCM,IPC,ORC,TCM
 SG_ EngineSpeedFailSts : 9|1@0+ (1,0) [0|1] "" BCM,BSM,CDCM,DASM,DCTM,DTCM,IPC,ORC,TCM
 SG_ EngineStopStartSts : 8|2@0+ (1,0) [0|3] "-" AGSM,BCM,BSM,CDCM,DASM,DCSM,DTCM
 SG_ EngineSts : 22|2@0+ (1,0) [0|3] "-" AGSM,BCM,BSM,CDCM,DASM,DCSM,DCTM,DTCM,ECM2,IPC,ORC,RFHM,TCM
 SG_ GasPedalPosition : 20|8@0+ (0.392,0) [0|99.568] "%" BCM,BSM,CDCM,DASM,DCTM,DTCM,TCM
 SG_ GasPedalPositionFailSts : 28|1@0+ (1,0) [0|1] "-" BCM,BSM,CDCM,DASM,DCTM,DTCM,ORC,TCM
 SG_ Message_Counter_E1 : 51|4@0+ (1,0) [0|15] "" AGSM,BCM,BSM,CDCM,DASM,DCSM,DCTM,DTCM,RFHM,TCM
 SG_ ReverseGearSts : 27|2@0+ (1,0) [0|3] "-" BCM,BSM,CDCM,DASM,IPC,ORC,RFHM
 SG_ StopStartSts : 24|2@0+ (1,0) [0|3] "-" AGSM,BCM,BSM,DASM,DCSM,IPC

BO_ 1445 ENGINE10: 8 ECM
 SG_ AfterRunCoolantPumpFailSts : 9|1@0+ (1,0) [0|1] "-" IPC
 SG_ CC_SetSpdDspl_KPH : 6|13@0+ (0.0625,0) [0|511.875] "kph" IPC
 SG_ CruiseControlLampSts : 7|1@0+ (1,0) [0|1] "-" IPC,ORC
 SG_ CruiseControlSts : 21|1@0+ (1,0) [0|1] "-" DCTM,IPC,ORC,TCM
 SG_ HMIDisplay_CC : 54|3@0+ (1,0) [0|7] "-" IPC
 SG_ Override : 22|1@0+ (1,0) [0|1] "-" BSM,DASM,ORC,TCM
 SG_ SpeedLimitSts : 20|3@0+ (1,0) [0|7] "-" IPC,ORC

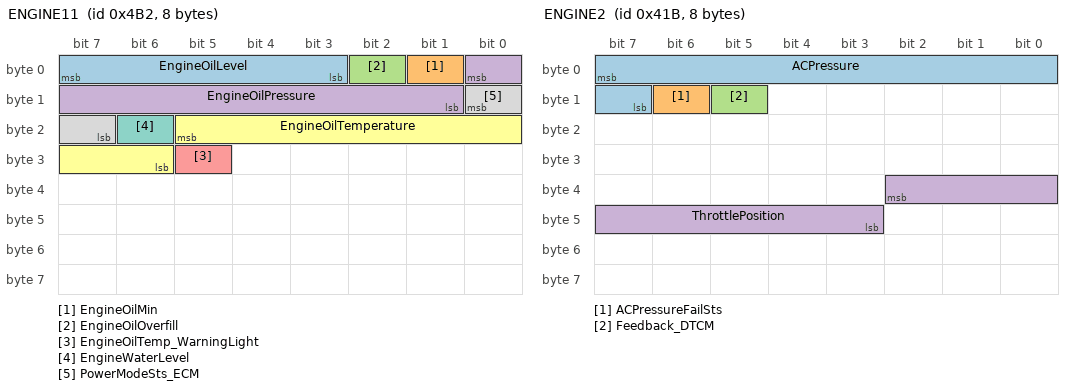
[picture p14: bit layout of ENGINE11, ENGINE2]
BO_ 1202 ENGINE11: 8 ECM
 SG_ EngineOilLevel : 7|5@0+ (1,0) [0|31] "-" BCM
 SG_ EngineOilMin : 1|1@0+ (1,0) [0|1] "-" Vector__XXX
 SG_ EngineOilOverfill : 2|1@0+ (1,0) [0|1] "-" Vector__XXX
 SG_ EngineOilPressure : 0|8@0+ (0.1,0) [0|25.4] "bar" Vector__XXX
 SG_ EngineOilTemp_WarningLight : 29|1@0+ (1,0) [0|1] "-" IPC
 SG_ EngineOilTemperature : 21|8@0+ (1,-40) [-40|215] "°C" IPC
 SG_ EngineWaterLevel : 22|1@0+ (1,0) [0|1] "-" IPC
 SG_ PowerModeSts_ECM : 8|2@0+ (1,0) [0|3] "-" BCM

BO_ 1051 ENGINE2: 8 ECM
 SG_ ACPressure : 7|9@0+ (0.1,0) [0|40] "bar" BCM
 SG_ ACPressureFailSts : 14|1@0+ (1,0) [0|1] "-" BCM
 SG_ Feedback_DTCM : 13|1@0+ (1,0) [0|1] "-" Vector__XXX
 SG_ ThrottlePosition : 34|8@0+ (0.392,0) [0|99.96] "%" ORC

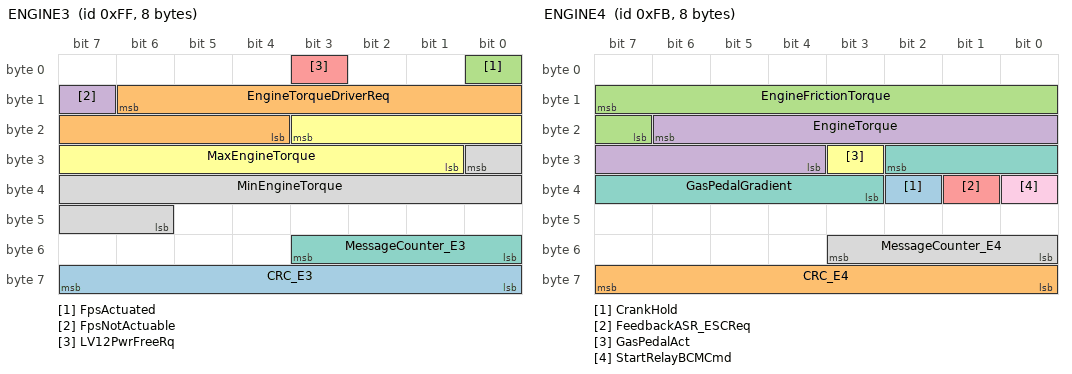
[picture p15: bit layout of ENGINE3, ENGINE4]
BO_ 255 ENGINE3: 8 ECM
 SG_ CRC_E3 : 63|8@0+ (1,0) [0|255] "" BCM,BSM,CDCM,DASM,DCTM,DTCM,TCM
 SG_ EngineTorqueDriverReq : 14|11@0+ (1,-500) [-500|1546] "Nm" BSM,CDCM,DASM,DCTM,DTCM,ORC,TCM
 SG_ FpsActuated : 0|1@0+ (1,0) [0|1] "" BCM,IPC
 SG_ FpsNotActuable : 15|1@0+ (1,0) [0|1] "-" BCM
 SG_ LV12PwrFreeRq : 3|1@0+ (1,0) [0|1] "" DCTM,TCM
 SG_ MaxEngineTorque : 19|11@0+ (1,-500) [-500|1546] "Nm" CDCM,DASM,DCTM,DTCM,TCM
 SG_ MessageCounter_E3 : 51|4@0+ (1,0) [0|15] "" BCM,BSM,CDCM,DASM,DCTM,DTCM,TCM
 SG_ MinEngineTorque : 24|11@0+ (1,-500) [-500|1546] "Nm" DASM,DCTM,TCM

BO_ 251 ENGINE4: 8 ECM
 SG_ CrankHold : 34|1@0+ (1,0) [0|1] "-" BCM,BSM
 SG_ CRC_E4 : 63|8@0+ (1,0) [0|255] "" BCM,BSM,CDCM,DCTM,DTCM,TCM
 SG_ EngineFrictionTorque : 15|9@0+ (1,0) [0|510] "Nm" BSM,CDCM,DASM
 SG_ EngineTorque : 22|11@0+ (1,-500) [-500|1546] "Nm" BSM,CDCM,DASM,DCTM,DTCM,ORC,TCM
 SG_ FeedbackASR_ESCReq : 33|1@0+ (1,0) [0|1] "-" BSM
 SG_ GasPedalAct : 27|1@0+ (1,0) [0|1] "-" BSM
 SG_ GasPedalGradient : 26|8@0+ (0.195,-25) [-25|24.53] "% /10ms" CDCM
 SG_ MessageCounter_E4 : 51|4@0+ (1,0) [0|15] "" BCM,BSM,CDCM,DCTM,DTCM,TCM
 SG_ StartRelayBCMCmd : 32|1@0+ (1,0) [0|1] "-" BCM

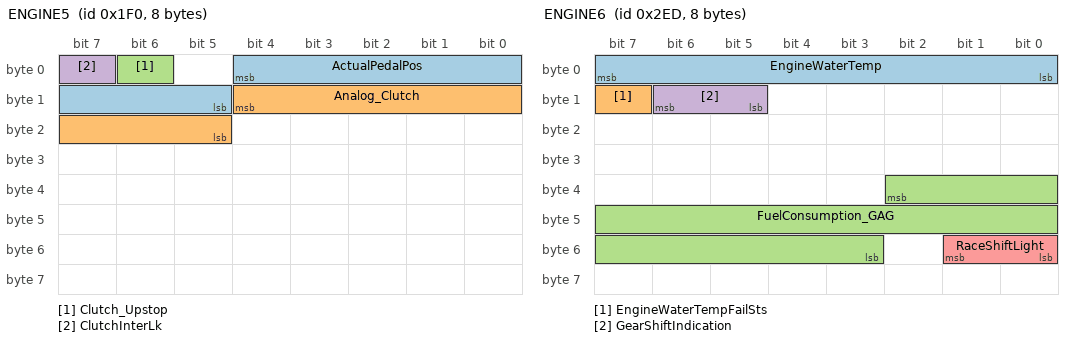
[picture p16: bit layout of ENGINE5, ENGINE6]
BO_ 496 ENGINE5: 8 ECM
 SG_ ActualPedalPos : 4|8@0+ (0.4,0) [0|100] "%" DASM,ORC
 SG_ Analog_Clutch : 12|8@0+ (0.4,0) [0|102] "%" BSM,CDCM
 SG_ Clutch_Upstop : 6|1@0+ (1,0) [0|1] "-" BSM,ORC
 SG_ ClutchInterLk : 7|1@0+ (1,0) [0|1] "-" BCM,BSM,ORC

BO_ 749 ENGINE6: 8 ECM
 SG_ EngineWaterTemp : 7|8@0+ (1,-40) [-40|215] "°C" BCM,DCTM,TCM
 SG_ EngineWaterTempFailSts : 15|1@0+ (1,0) [0|1] "-" BCM,DCTM,TCM
 SG_ FuelConsumption_GAG : 34|16@0+ (0.0022,0) [0|144.1748] "litres/hour" BCM,CDCM,IPC
 SG_ GearShiftIndication : 14|2@0+ (1,0) [0|3] "-" BCM,CDCM,IPC
 SG_ RaceShiftLight : 49|2@0+ (1,0) [0|3] "-" IPC

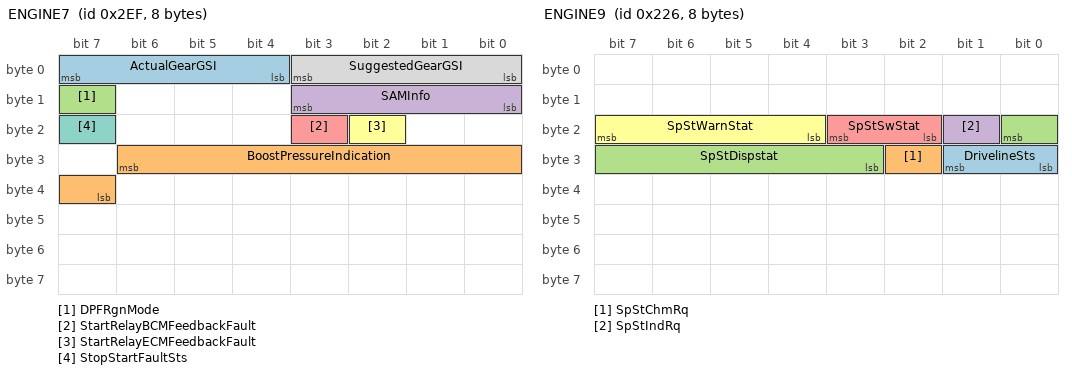
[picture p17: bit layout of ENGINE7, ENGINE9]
BO_ 751 ENGINE7: 8 ECM
 SG_ ActualGearGSI : 7|4@0+ (1,0) [0|15] "-" CDCM,DASM,IPC,ORC
 SG_ BoostPressureIndication : 30|8@0+ (15,0) [0|3825] "mbar" Vector__XXX
 SG_ DPFRgnMode : 15|1@0+ (1,0) [0|1] "-" DCTM,TCM
 SG_ SAMInfo : 11|4@0+ (1,0) [0|14] "-" BCM
 SG_ StartRelayBCMFeedbackFault : 19|1@0+ (1,0) [0|1] "-" BCM
 SG_ StartRelayECMFeedbackFault : 18|1@0+ (1,0) [0|1] "-" BCM,ORC
 SG_ StopStartFaultSts : 23|1@0+ (1,0) [0|1] "-" BCM
 SG_ SuggestedGearGSI : 3|4@0+ (1,0) [0|15] "-" CDCM,IPC

BO_ 550 ENGINE9: 8 ECM
 SG_ DrivelineSts : 25|2@0+ (1,0) [0|3] "-" IPC
 SG_ SpStChmRq : 26|1@0+ (1,0) [0|1] "-" IPC
 SG_ SpStDispstat : 16|6@0+ (1,0) [0|63] "-" BCM,IPC
 SG_ SpStIndRq : 17|1@0+ (1,0) [0|1] "-" Vector__XXX
 SG_ SpStSwStat : 19|2@0+ (1,0) [0|3] "-" BCM
 SG_ SpStWarnStat : 23|4@0+ (1,0) [0|15] "-" BCM,IPC

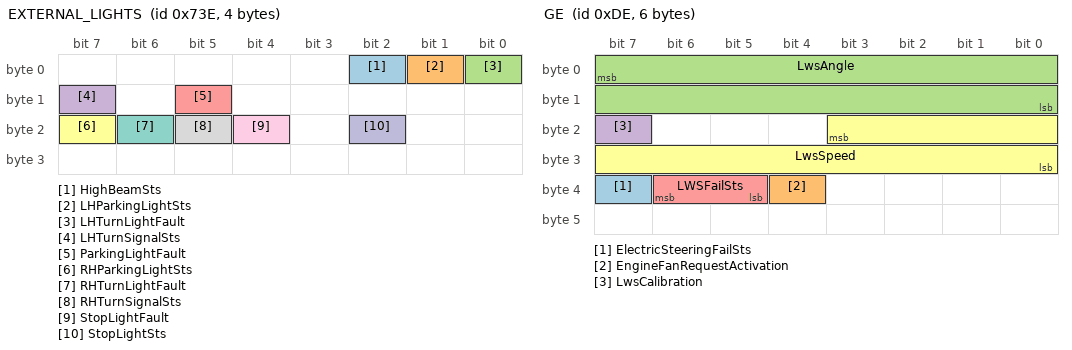
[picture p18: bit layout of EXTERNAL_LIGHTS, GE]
BO_ 1854 EXTERNAL_LIGHTS: 4 BCM
 SG_ HighBeamSts : 2|1@0+ (1,0) [0|1] "-" ORC
 SG_ LHParkingLightSts : 1|1@0+ (1,0) [0|1] "-" ORC
 SG_ LHTurnLightFault : 0|1@0+ (1,0) [0|1] "-" ORC
 SG_ LHTurnSignalSts : 15|1@0+ (1,0) [0|1] "-" ORC
 SG_ ParkingLightFault : 13|1@0+ (1,0) [0|1] "-" ORC
 SG_ RHParkingLightSts : 23|1@0+ (1,0) [0|1] "-" ORC
 SG_ RHTurnLightFault : 22|1@0+ (1,0) [0|1] "-" ORC
 SG_ RHTurnSignalSts : 21|1@0+ (1,0) [0|1] "-" ORC
 SG_ StopLightFault : 20|1@0+ (1,0) [0|1] "-" DASM,ORC
 SG_ StopLightSts : 18|1@0+ (1,0) [0|1] "-" BSM,ORC

BO_ 222 GE: 6 BCM
 SG_ ElectricSteeringFailSts : 39|1@0+ (1,0) [0|1] "" IPC
 SG_ EngineFanRequestActivation : 36|1@0+ (1,0) [0|1] "" ECM
 SG_ LwsAngle : 7|16@0+ (0.1,-720) [-720|720] "°" DASM,DCTM,DTCM,ECM,TCM
 SG_ LwsCalibration : 23|1@0+ (1,0) [0|1] "-" DTCM
 SG_ LWSFailSts : 38|2@0+ (1,0) [0|3] "-" DASM,DCTM,DTCM,TCM
 SG_ LwsSpeed : 19|12@0+ (1,-2000) [-2000|2094] "°/s" DASM,DTCM,ECM

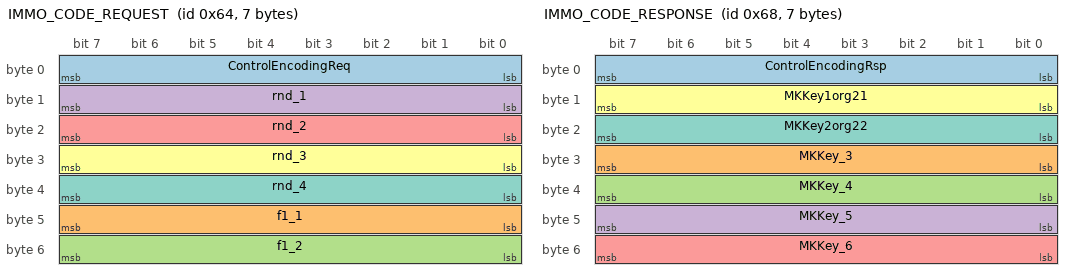
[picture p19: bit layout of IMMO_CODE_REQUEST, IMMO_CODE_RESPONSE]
BO_ 100 IMMO_CODE_REQUEST: 7 ECM
 SG_ ControlEncodingReq : 7|8@0+ (1,0) [0|255] "-" BCM
 SG_ f1_1 : 47|8@0+ (1,0) [0|255] "-" BCM
 SG_ f1_2 : 55|8@0+ (1,0) [0|255] "-" BCM
 SG_ rnd_1 : 15|8@0+ (1,0) [0|255] "-" BCM
 SG_ rnd_2 : 23|8@0+ (1,0) [0|255] "-" BCM
 SG_ rnd_3 : 31|8@0+ (1,0) [0|255] "-" BCM
 SG_ rnd_4 : 39|8@0+ (1,0) [0|255] "-" BCM

BO_ 104 IMMO_CODE_RESPONSE: 7 BCM
 SG_ ControlEncodingRsp : 7|8@0+ (1,0) [0|255] "-" ECM
 SG_ MKKey_3 : 31|8@0+ (1,0) [0|255] "-" ECM
 SG_ MKKey_4 : 39|8@0+ (1,0) [0|255] "-" ECM
 SG_ MKKey_5 : 47|8@0+ (1,0) [0|255] "-" ECM
 SG_ MKKey_6 : 55|8@0+ (1,0) [0|255] "-" ECM
 SG_ MKKey1org21 : 15|8@0+ (1,0) [0|255] "-" ECM
 SG_ MKKey2org22 : 23|8@0+ (1,0) [0|255] "-" ECM

BO_TX_BU_ 2651930646 : AGSM,DCSM;
BO_TX_BU_ 601 : BCM,IPC;
BO_TX_BU_ 2564485407 : AGSM,DCSM;
BO_TX_BU_ 2564485400 : DCTM,TCM;

CM_ "Project_952_ProjectStandard_C-CAN1 [07340_Alfa]";
CM_ SG_ 599 AirBagFailSts "This signal is used to require the activation/deactivation of airbag warning light";
CM_ SG_ 599 PsngrBagChargeSts "This signal is used to communicate the status of Front Passenger Protection Pyrotechnical charges";
CM_ SG_ 599 SBR1RowCentralSeatBuckleFailSts "First row central seatbelt buckle switch fail status";
CM_ SG_ 599 SBR1RowCentralSeatConfigSts "Signal used to show if the first row central seatbelt is under check";
CM_ SG_ 599 SBR1RowCentralSeatPPDFailSts "PPD fail status of first row central seat";
CM_ SG_ 599 SBR1RowCentralSeatSts "First row central seat status";
CM_ SG_ 599 SBR1RowDriverSeatConfigSts "Signal used to show if the first row driver seatbelt is under check";
CM_ SG_ 599 SBR1RowDriverSeatFailSts "First row driver seatbelt switch fail status";
CM_ SG_ 599 SBR1RowDriverSeatSts "First row driver seatbelt switch status";
CM_ SG_ 599 SBR1RowPsngrSeatBuckleFailSts "First row passenger seatbelt buckle switch fail status";
CM_ SG_ 599 SBR1RowPsngrSeatConfigSts "Signal used to show if the first row passenger seatbelt is under check";
CM_ SG_ 599 SBR1RowPsngrSeatPPDFailSts "PPD fail status of first row passenger seat";
CM_ SG_ 599 SBR1RowPsngrSeatSts "First row passenger seat status";
CM_ SG_ 599 SBR2RowCentralSeatConfigSts "Signal used to show if the second row central seatbelt is under check";
CM_ SG_ 599 SBR2RowCentralSeatSts "Second row central seatbelt switch status";
CM_ SG_ 599 SBR2RowLeftSeatConfigSts "Signal used to show if the second row central seatbelt is under check";
CM_ SG_ 599 SBR2RowLeftSeatSts "Second row left seatbelt switch status";
CM_ SG_ 599 SBR2RowRightSeatConfigSts "Signal used to show if the second row central seatbelt is under check";
CM_ SG_ 599 SBR2RowRightSeatSts "Second row right seatbelt switch status";
CM_ SG_ 1447 CRC_A2 "CRC according to SAE J1850 standard that has to be calculated at each frame transmission";
CM_ SG_ 1447 DrvSbltUnFltr "Driver seatbelt fault status - unfiltered";
CM_ SG_ 1447 MessageCounter_A2 "This signal is a counter used for safety checks strategies. This counter is incremented of 1 (one) unit at each frame transmission";
CM_ SG_ 1050 BatteryCurrentLevel "This signal indicates the battery current.";
CM_ SG_ 1050 BatteryTemperature "This signal indicates the battery temperature.";
CM_ SG_ 1050 BatteryVoltageLevelHP "This signal indicates the battery voltage.";
CM_ SG_ 1050 BCMSAMFailSts "This signal indicates a fault present in BCM related to the SAM strategy.";
CM_ SG_ 1050 IBSFailSts "This signal indicates a fault present in the IBS sensor.";
CM_ SG_ 1050 StateOfCharge "This signal indicates the battery state of charge.";
CM_ SG_ 1050 VoltageMax "This signal indicates the maximum regulation voltage permitted by BCM in the SAM strategy.";
CM_ SG_ 1050 VoltageMin "This signal indicates the minimum regulation voltage permitted by BCM in the SAM strategy.";
CM_ SG_ 247 TxpAuthRequest "This signal is used to request a transponder authentication";
CM_ SG_ 247 TxpReadRequest "This signal is used to request a transponder reading";
CM_ SG_ 250 BCMFpsCommand "The signal is used to command the FPS strategy actuation";
CM_ SG_ 250 BCMFpsConfirm "The signal is used to confirm the FPS strategy command";
CM_ SG_ 250 BCMFpsFailSts "This signal is used to give information of a fault present on the FPS sensing device.";
CM_ SG_ 250 BrakePedalSwitchNCFailSts "Brake pedal switch CAN signals cannot be used by receiver";
CM_ SG_ 250 BrakePedalSwitchNCSts "It is the Redundant Brake Switch (Normally Closed) position status, acquired by BCM and transmitted on CAN.";
CM_ SG_ 250 BrakePedalSwitchNOFailSts "Brake pedal switch CAN signals cannot be used by receiver";
CM_ SG_ 250 BrakePedalSwitchNOSts "It is the Brake Light Switch (Normally Open) position status, acquired by BCM and transmitted on CAN.";
CM_ SG_ 250 EngineOffRequest "The signal is used to require an  engine shut off";
CM_ SG_ 250 KeyInIgnSts "Key in ignition status";
CM_ SG_ 250 MessageCounter_BC "This signal is a counter used for safety checks strategies. This counter is incremented of 1 (one) unit at each frame transmission.";
CM_ SG_ 250 StartRelayBCMFault "BCM starter relay fault detected";
CM_ SG_ 250 StartRelayBCMSts "BCM starter relay status; [1] = ON";
CM_ SG_ 250 TurnIndicatorSts "The signal is used to indicate the turn indicator position.";
CM_ SG_ 245 MinicryptReceptionSts "This signal is used to give an acknowledge on specific message reception.";
CM_ SG_ 1446 A2D_DRV_TEMP_DR_POS "Transmit raw A/D driver temp door position to ECM, the information is used to make OBD model more robust";
CM_ SG_ 1446 A2D_FT_HVAC_BLOWER_VOLTAGE "Transmit raw A/D blower voltage to ECM, the information is used to make OBD model more robust";
CM_ SG_ 1446 AcOutputCurrentSts "It is the ECVD electrovalve current";
CM_ SG_ 1446 StopStartClimateInfo "HVAC conditions effecting stop start enable";
CM_ SG_ 748 FrontWiperMoveSts "This signal indicates the position of the front wiper (contact cam open or close)";
CM_ SG_ 748 RemStartActiveEPB "This signal is used for EPB activation request for remote start functionality";
CM_ SG_ 900 DriveStyleSts "This signal gives indications about drive style status required.";
CM_ SG_ 900 Int_Relay_FailSts "Used to indicate an anomaly on the INT.Relay device";
CM_ SG_ 900 SuspensionLevel "This signal gives indications about Suspension status required";
CM_ SG_ 1349 ChkFuelLevelSts "Used to give information about the diagnostic of CILC.";
CM_ SG_ 1349 ExternalTemperatureAD_Voltage "Indicates the raw voltage of the ambient temp sensor";
CM_ SG_ 1349 FuelLevel "Used to give information about the percentage of the fuel level present in the tank.";
CM_ SG_ 1349 FuelLevelFailSts "Used to give information about the fail status of the FuelLevel signal.";
CM_ SG_ 1349 InternalLightLevel "Used to give information about the backlight dimming level selected.";
CM_ SG_ 1349 InternalLightSts "Used to give information about backlight mode selected (Day or Night).";
CM_ SG_ 1349 NotFilteredFuelLevel "Used to give information about the not filtered fuell level value in ohm.";
CM_ SG_ 1201 BatteryStateOfFunction "This signal indicates the lowest battery voltage value at the next automatic restart";
CM_ SG_ 1201 BonnetSts "Used to give information about the bonnet status";
CM_ SG_ 1201 CompressorACReqSts "This signal is sent from BCM to ECM to inform of Compressor AC activation request";
CM_ SG_ 1201 DriverDoorFailSts "Signal used to inform other systems about an electric fault on driver ajar switch.";
CM_ SG_ 1201 DriverDoorSts "This signal indicates the driver door status";
CM_ SG_ 1201 ExteriorRearReleaseSwitchSts "Used to give rear access button press info to the body controller to allow releasing the rear access point";
CM_ SG_ 1201 FHeatedWindowSts "The signal indicates the effective activation of heated front window.";
CM_ SG_ 1201 FOBSearchRequest "Signal used to request the FOB searching.";
CM_ SG_ 1201 PsngrDoorSts "This signal indicates the passenger door status";
CM_ SG_ 1201 RemSt_InhibitSts "Remote start inhibit";
CM_ SG_ 1201 RemStActvSts "Type of start being requested";
CM_ SG_ 1201 RHeatedWindowSts "The signal indicates the effective activation of heated rear window.";
CM_ SG_ 1201 SpSt_Pad1 "Stop Start Button Press 1";
CM_ SG_ 1201 TheftAlarmStatus "VTA status";
CM_ SG_ 1049 BonnetAjarRawValSts "The signal gives info on Bonnet ajar input to engine controller to use for stop-start and do diagnosis in the engine controller.";
CM_ SG_ 1049 DriverDoor2AjarRawValSts "Driver door status value";
CM_ SG_ 1049 DriverDoor2AjarXtionSts "Driver door status change";
CM_ SG_ 1049 DriverDoorAjarRawValSts "The signal gives info on Driver Door ajar input to engine controller to use for stop-start and do diagnosis in the engine controller.";
CM_ SG_ 1049 DriverDoorAjarXtionSts "Driver door status change";
CM_ SG_ 1049 FUEL_VOLT "Used to give information about the not filtered fuell level value in volt.";
CM_ SG_ 1049 FUEL_VOLT2 "Sub Side Fuel level sensor A/D Voltage (saddle/Dual tank)";
CM_ SG_ 1049 PsngrDoorAjarRawValSts "The signal gives info on psngr Door ajar input to engine controller to use for stop-start and do diagnosis in the engine controller.";
CM_ SG_ 1049 PsngrDoorAjarXtionSts "Passenger door status change";
CM_ SG_ 257 ABSActive "This signal is set to Active when the ABS functionality is active.";
CM_ SG_ 257 BrakeInterventionSts "This signal is ?active? when the brake intervention is due to ESC, ASR, ACC systems and ?not active? when the brake intervention is due to the driver.";
CM_ SG_ 257 BSMShiftInterference "With this signal the BSMcan ask to Automatic/Robotic gearbox to prohibits the gear change during ASR/ESC manoeuvre.This signal is only available on ESC variant";
CM_ SG_ 257 CMMInterventionAck "It indicates if the brake system has fullfilled the Autonomous Emergency Braking request.";
CM_ SG_ 257 CRC_B1 "CRC according to SAE J1850 standard that has to be calculated from bit 63 to bit 8 at each frame transmission.";
CM_ SG_ 257 ESCActive "This signal is set to Active when the brake intervention by ESC is active.";
CM_ SG_ 257 Ft_RrAxleCoupling_TrqRq "Desired Torque for Center Diff";
CM_ SG_ 257 Ft_RrTrqCoupling_ModeRq "ESP Requested Front Differential State";
CM_ SG_ 257 MasterCylinderPressure "This signal indicates the unfiltered sensor signal of the Master Cylinder Pressure. This signal is only available on ESC variant";
CM_ SG_ 257 MessageCounter_B1 "This signal is a counter used for safety checks strategies. This counter is incremented of 1 (one) unit at each frame transmission.";
CM_ SG_ 257 PrefillActive "This signal indicates the prefill function status.";
CM_ SG_ 257 VehicleSpeedVSOSig "It is the average vehicle speed calculated.";
CM_ SG_ 257 VehicleSpeedVSOSigFailSts "It is the average vehicle speed fail status.";
CM_ SG_ 506 BrkPrss_One "Brake Pressure One (P1) / Raw Unfiltered Primary Pressure";
CM_ SG_ 263 BrakeFluidLevelSts_BSM "This signal indicates when the brake fluid level is low or normal";
CM_ SG_ 263 BrakeTravelFailSts "This signal indicate the Fail Status of brake pedal travel information";
CM_ SG_ 263 BrakeTravelSts "This signal indicate the brake pedal travel .";
CM_ SG_ 263 CRC_B11 "CRC according to SAE J1850 standard that has to be calculated from bit 63 to bit 8 at each frame transmission.";
CM_ SG_ 263 DiskWearLamp "The signal indicates the Brake Disk Wear Lamp request";
CM_ SG_ 263 EPB_Pad_Wear "This signal indicate the status of EPB Pad Wear";
CM_ SG_ 263 FrontDiskTemp "The signal indicates the Front disk temperature";
CM_ SG_ 263 FrontDiskWear "This signal indicates when the brake wear percentage relative to the initial  disck weight";
CM_ SG_ 263 MessageCounter_B11 "This signal is a counter used for safety checks strategies. This counter is incremented of 1 (one) unit at each frame transmission.";
CM_ SG_ 263 RearDiskTemp "The signal indicates the Rear disk temperature";
CM_ SG_ 263 RearDiskWear "This signal indicates when the brake wear percentage relative to the initial  disck weight";
CM_ SG_ 259 ACC_Engine_Torque_Enabled_BSM "An enable bit that Torque commands should be followed";
CM_ SG_ 259 TorqueRequest_FAST "This signal indicate the FAST engine torque request, used at high µ when the traction control intervention is short";
CM_ SG_ 501 AEB_InterventionType "DAS Req Active";
CM_ SG_ 501 VehicleStandStillSts "This signal indicates if the car is in stand still condition";
CM_ SG_ 498 Brk_Thermdl "This signal indicate when the estimated brake temperature is over a predefined threshold.";
CM_ SG_ 1048 TravelDistance "This signal indicates the travel distance value.";
CM_ SG_ 1199 ACCEngaged "ACC is engaged";
CM_ SG_ 1199 BSMSysSts "This signal is used by BSM to indicate its mode";
CM_ SG_ 1199 ERMActive "This signal is set to \"active\" when Electronic Roll Mitigation functionality is acting.";
CM_ SG_ 1199 RollsModeAct "This signal indicates when the brake system module is in the Rolls Test mode.";
CM_ SG_ 1199 TSCActive "This signal is set to \"active\" when Trailer Sway Control functionality is acting";
CM_ SG_ 1453 DsblFuelShutOff_ACC_BSM "Used to deactivate the ECM fuel cut off (functional GW from DASM, sended by BSM).";
CM_ SG_ 284 CRC_BVM "CRC according to SAE J1850 standard that has to be calculated from bit 63 to bit 8 at each frame transmission";
CM_ SG_ 284 MessageCounter_BVM "This signal is a counter used for safety checks strategies. This counter is incremented of 1 (one) unit at each frame transmission.";
CM_ SG_ 284 Stabi_Index "Vehicle Stability Index";
CM_ SG_ 284 YawRateRef "reference yaw rate";
CM_ SG_ 284 YawRateStat "stationary yaw rate";
CM_ SG_ 254 CRC_BYD "CRC according to SAE J1850 standard that has to be calculated from bit 63 to bit 8 at each frame transmission.";
CM_ SG_ 254 InternalError_BSM "This signal indicates if an internal error has been processed";
CM_ SG_ 254 LatAcceleration_BSM "This signal indicates the Lateral Acceleration Value";
CM_ SG_ 254 LatAccelerationFailSts_BSM "This signal indicates the status of Lateral Acceleration Signal";
CM_ SG_ 254 LongAcceleration_BSM "This signal indicates the Longitudinal Acceleration Value";
CM_ SG_ 254 LongAccelerationFailSts_BSM "This signal indicates the status of Longitudinal acceleration signal";
CM_ SG_ 254 MessageCounter_BYD "This signal is a counter used for safety checks strategies. This counter is incremented of 1 (one) unit at each frame transmission.";
CM_ SG_ 254 Slope "Slope value detected by BSM";
CM_ SG_ 254 YawRate_BSM "This signal indicates the Yaw Rate Value";
CM_ SG_ 254 YawRateFailSts_BSM "This signal indicates the Status of Yaw Rate Signal";
CM_ SG_ 1451 TorqueOverlayIntActivation_SPM "This signal is sent by the SPM with the aim of activate the torque overlay interface with the Electric Power Steering Module.";
CM_ SG_ 288 CRC_EC "CRC according to SAE J1850 standard that has to be calculated from bit 63 to bit 8 at each frame transmission";
CM_ SG_ 288 CutAdvice "This signal describes the consensus of the CDCM algorithm to cut the fuel injection in half engine";
CM_ SG_ 288 MessageCounter_EC "This signal is a counter used for safety checks strategies. This counter is incremented of 1 (one) unit at each frame transmission.";
CM_ SG_ 601 TotalOdometer "Used to give information about the total odometer value in km.";
CM_ SG_ 598 ABSLamp_FailSts "This signal communicates the status of the related lamp.";
CM_ SG_ 598 AirBagLamp_FailSts "This signal is used to inform about the airbag warning light status";
CM_ SG_ 598 DistanceUnit "Used to give information about the distance unit selected.";
CM_ SG_ 598 EBDLamp_FailSts "This signal communicates the status of the related lamp.";
CM_ SG_ 598 EPBAutoAppReqSts "This signal communicates the status of the activation of the functionality AutoApply of the EPB";
CM_ SG_ 598 EPBLamp_FailSts "This signal communicates the status of the related lamp.";
CM_ SG_ 598 EPBMaintenanceReqSts "Request of Activation Maintenance Mode";
CM_ SG_ 598 ESCLamp_FailSts "This signal communicates the status of the related lamp.";
CM_ SG_ 598 FSFCWPlusActivationMode "This signal is used to give information about the FSFCW Activation Mode setting";
CM_ SG_ 598 FSFCWPlusSetting "This signal is used to give information about the FSFCW setting";
CM_ SG_ 598 HHDisablingCommandSts "This signal requires the disabling of Hill Holder functionality.";
CM_ SG_ 598 PassiveEntry "This signal is used to give information about the Passive Entry selected.";
CM_ SG_ 598 PsngrBagRequestSts "This signal is used by IPC to send the request of the customer to change the current status of Front Passenger Protection";
CM_ SG_ 598 RemoteDoorUnlock "This signal is used to give information about the Remote Door Unlock selected.";
CM_ SG_ 348 ACC_Engine_Torque "Engine Torque Request by DASM for ACC events";
CM_ SG_ 348 ACC_Engine_Torque_Enabled "An enable bit that Torque commands should be followed";
CM_ SG_ 348 BASensThresholdReq "Request to brake system for performing TA function.";
CM_ SG_ 348 Brake_Jerk_Req "Request from DASM to perform Jerk Warning";
CM_ SG_ 348 CRC_DI "CRC according to SAE J1850 standard that has to be calculated from bit 63 to bit 8 at each frame transmission.";
CM_ SG_ 348 DsblFuelShutOff_ACC "Used to deactivate the ECM fuel cut off";
CM_ SG_ 348 HIS_Req "Used to command Stop during Stop and Go ACC and FSFCW+";
CM_ SG_ 348 Intervention "Request to set target acceleration/deceleration for any feature";
CM_ SG_ 348 InterventionCounter "This signal is a counter used for safety checks strategies. This counter is incremented of 1 (one) unit at each frame transmission.";
CM_ SG_ 348 InterventionReq "Acceleration request made by DASM";
CM_ SG_ 348 InterventionType "Type of intervention";
CM_ SG_ 348 MessageCounter_DI "This signal is a counter used for safety checks strategies. This counter is incremented of 1 (one) unit at each frame transmission.";
CM_ SG_ 348 Prefill_Req "Prefill command of Brake System by DASM";
CM_ SG_ 2564554481 N_PDU "This signal is used for diagnostic purposes";
CM_ SG_ 2564440305 N_PDU "This signal is used for diagnostic purposes";
CM_ SG_ 2564434673 N_PDU "This signal is used for diagnostic purposes";
CM_ SG_ 2564430577 N_PDU "This signal is used for diagnostic purposes";
CM_ SG_ 2564428017 N_PDU "This signal is used for diagnostic purposes";
CM_ SG_ 2564429809 N_PDU "This signal is used for diagnostic purposes";
CM_ SG_ 2564502513 N_PDU "This signal is used for diagnostic purposes";
CM_ SG_ 2564448497 N_PDU "-";
CM_ SG_ 2564474865 N_PDU "This signal is used for diagnostic purposes";
CM_ SG_ 2564431857 N_PDU "This signal is used for diagnostic purposes.";
CM_ SG_ 2564430065 N_PDU "This signal is used for diagnostic purposes";
CM_ SG_ 2564485440 N_PDU "This signal is used for diagnostic purposes";
CM_ SG_ 2564485418 N_PDU "This signal is used for diagnostic purposes";
CM_ SG_ 2564485402 N_PDU "This signal is used for diagnostic purposes";
CM_ SG_ 2564485392 N_PDU "This signal is used for diagnostic purposes";
CM_ SG_ 2564485399 N_PDU "This signal is used for diagnostic purposes";
CM_ SG_ 2564485472 N_PDU "-";
CM_ SG_ 2564485575 N_PDU "This signal is used for diagnostic purposes";
CM_ SG_ 2564485407 N_PDU "This is a signal used for diagnostic purposes.";
CM_ SG_ 2564485400 N_PDU "This signal is used for diagnostic purposes";
CM_ SG_ 752 BatteryVoltageHP "This signal indicates the battery voltage.";
CM_ SG_ 752 IBS_SOC_ECM "This signal indicates the SOC from IBS.";
CM_ SG_ 1846 BrkSw1Stat "EDR ONLY - Brake switch1 status, off = [0]";
CM_ SG_ 1846 BrkSw2Stat "EDR ONLY - Brake switch2 status, off = [0]";
CM_ SG_ 1846 ESP_TrqRqEnabl "EDR ONLY - ESP torque requests are allowed = [1]";
CM_ SG_ 1846 Lv1CrsCtrlOff "EDR ONLY - Level is requested cruise off";
CM_ SG_ 1846 RawPVS1 "EDR ONLY - Raw pedal value sensor #1";
CM_ SG_ 1846 RawPVS2 "EDR ONLY - Raw pedal value sensor #2";
CM_ SG_ 1846 RawTPS1 "EDR ONLY - Raw throttle position sensor #1";
CM_ SG_ 1846 RawTPS2 "EDR ONLY - Raw throttle position sensor #2";
CM_ SG_ 252 AlternatorFail "Indicates if the alternator is in fail condition";
CM_ SG_ 252 BankDeactivationSts "Engine Bank Deactivation Status";
CM_ SG_ 252 CC_BrakeIntervention "This Signal indicated the deceleration target required by ECM for CC and SL function";
CM_ SG_ 252 CC_BrakeIntervention_Req "This Signal indicated the request for Brake Interventio  by ECM for CC and SL function";
CM_ SG_ 252 EngineSpeed "It gives inforrmation on C-CAN network about  engine speed";
CM_ SG_ 252 EngineSpeedFailSts "Used to indicate if a Fail is present for the engine speed";
CM_ SG_ 252 ReverseGearSts "Used to give information about Reverse Gear status";
CM_ SG_ 1445 AfterRunCoolantPumpFailSts "The signal indicates a fault on AfterRunCoolant Pump";
CM_ SG_ 1445 CC_SetSpdDspl_KPH "Cruise Control Vehicle Set Speed in Kilometer Per Hour";
CM_ SG_ 1445 CruiseControlLampSts "It is the cruise control light command";
CM_ SG_ 1445 CruiseControlSts "It gives information  on C-CAN network about the actual status of cruise control function.";
CM_ SG_ 1445 HMIDisplay_CC "HMI Code for CC functionality";
CM_ SG_ 1445 SpeedLimitSts "It represents on C-CAN the actual status of speed limiter control function.";
CM_ SG_ 1202 EngineOilLevel "Engine Oil Level";
CM_ SG_ 1202 EngineOilMin "Oil Minimum indicator";
CM_ SG_ 1202 EngineOilOverfill "Oil Overfill indicator";
CM_ SG_ 1202 EngineOilPressure "Engine Oil Pressure";
CM_ SG_ 1202 EngineOilTemp_WarningLight "Engine Oil Temperature Warning Light";
CM_ SG_ 1202 EngineOilTemperature "Engine Oil Temperature";
CM_ SG_ 1202 EngineWaterLevel "Engine Water Level warning";
CM_ SG_ 1202 PowerModeSts_ECM "Logistic Mode Status";
CM_ SG_ 1051 ACPressure "It indicates air conditioning pressure read from the AC linear pressure sensor.";
CM_ SG_ 1051 ACPressureFailSts "This signal indicates if the ACpressure sensor is in fail.";
CM_ SG_ 1051 Feedback_DTCM "It is set to Not Valid, when the plausibility conditions about DTCM torque request are not fulfilled";
CM_ SG_ 1051 ThrottlePosition "GASOLINE APPLICATION ONLY This signal represents throttle position evaluated on the basis of throttle position sensor.";
CM_ SG_ 251 CrankHold "Used by ECM to command an action to the BCM cranking relay during cranking phase";
CM_ SG_ 251 FeedbackASR_ESCReq "It is set to Not Valid, when the plausibility conditions about ASR / ESC torque request are not fulfilled . Nevertheless, it shall not be set to Not Valid, due to ValidData bits Not Valid transmitted from BSM.";
CM_ SG_ 251 StartRelayBCMCmd "Used by ECM to command an action to the BCM cranking relay.";
CM_ SG_ 496 ActualPedalPos "Actual pedal position.";
CM_ SG_ 496 Analog_Clutch "Analog Clutch Pedal Signal";
CM_ SG_ 496 Clutch_Upstop "Partial Travel Clutch Switch";
CM_ SG_ 496 ClutchInterLk "Full Travel Clutch Switch";
CM_ SG_ 749 FuelConsumption_GAG "It represents istantaneous consumption information sent on network";
CM_ SG_ 749 GearShiftIndication "It gives indication of gear shifting";
CM_ SG_ 749 RaceShiftLight "This signal is use to indicate the Shift light urgency to IPC.";
CM_ SG_ 751 ActualGearGSI "It gives indication of Actual gear";
CM_ SG_ 751 BoostPressureIndication "1) This signal represents the boost pressure indication measured by boost pressure sensor";
CM_ SG_ 751 SuggestedGearGSI "It gives indication of Suggested gear";
CM_ SG_ 550 DrivelineSts "Gives the status of the driveline, based on clutch and/or neutral sensors";
CM_ SG_ 550 SpStChmRq "Stop start chime request";
CM_ SG_ 550 SpStDispstat "Stop start display status";
CM_ SG_ 550 SpStIndRq "Stop start indicator request";
CM_ SG_ 550 SpStSwStat "Stop start switch status";
CM_ SG_ 550 SpStWarnStat "Stop start warning status";
CM_ SG_ 1854 StopLightSts "Request of Stop Lights activation";
CM_ SG_ 222 ElectricSteeringFailSts "It indicates if system EPS has an internal fault.";
CM_ SG_ 222 EngineFanRequestActivation "This signal is used to activate the cooling fun by the electric power steering.";
CM_ SG_ 222 LwsAngle "This signal indicates the steering angle value, counterclockwise positive.";
CM_ SG_ 222 LwsCalibration "This signal indicates if the sensor has been calibrated and therefore the steering angle value is exported over Can.";
CM_ SG_ 222 LWSFailSts "This signal indicates steering angle export function failure status.";
CM_ SG_ 222 LwsSpeed "This signal indicates the steering speed value, counterclockwise positive.";
CM_ SG_ 100 ControlEncodingReq "This signal is used for IMMO communication";
CM_ SG_ 100 f1_1 "This signal is used for IMMO communication";
CM_ SG_ 100 f1_2 "This signal is used for IMMO communication";
CM_ SG_ 100 rnd_1 "This signal is used for IMMO communication";
CM_ SG_ 100 rnd_2 "This signal is used for IMMO communication";
CM_ SG_ 100 rnd_3 "This signal is used for IMMO communication";
CM_ SG_ 100 rnd_4 "This signal is used for IMMO communication";
CM_ SG_ 104 ControlEncodingRsp "This signal is used for IMMO communication";
CM_ SG_ 104 MKKey_3 "This signal is used for IMMO communication";
CM_ SG_ 104 MKKey_4 "This signal is used for IMMO communication";
CM_ SG_ 104 MKKey_5 "This signal is used for IMMO communication";
CM_ SG_ 104 MKKey_6 "This signal is used for IMMO communication";
CM_ SG_ 104 MKKey1org21 "This signal is used for IMMO communication";
CM_ SG_ 104 MKKey2org22 "This signal is used for IMMO communication";

BA_DEF_ SG_ "Accuracy" STRING ;
BA_DEF_ SG_ "Event trans." ENUM "Yes","No";
BA_DEF_ SG_ "GenSigStartValue" INT 0 2147483647;
BA_DEF_ SG_ "GenSigInactiveValue" INT 0 2147483647;
BA_DEF_ SG_ "GenSigSendType" ENUM "NotUsed","OnWrite","OnWriteWithRepetition","OnChange","OnChangeWithRepetition","IfActive","IfActiveWithRepetition","NoSigSendType";
BA_DEF_ BO_ "DiagRequest" ENUM "No","Yes";
BA_DEF_ BO_ "Period [ms]" INT 0 65535;
BA_DEF_ BO_ "Type" ENUM "P","C","PE","COC","PE_Cntrl","E","E_Cntrl","OC","S","BAF","DC","EM","MM","-";
BA_DEF_ BO_ "DiagResponse" ENUM "No","Yes";
BA_DEF_ BO_ "NmMessage" ENUM "No","Yes";
BA_DEF_ BO_ "GenMsgSendType" ENUM "Cyclic","NotUsed","NotUsed","NotUsed","NotUsed","NotUsed","NotUsed","NotUsed","NoMsgSendType";
BA_DEF_ BO_ "GenMsgTimeoutTime" INT 0 10000;
BA_DEF_ BO_ "GenMsgNrOfRepetition" INT 0 255;
BA_DEF_ BO_ "GenMsgILSupport" ENUM "No","Yes";
BA_DEF_ BO_ "GenMsgStartDelayTime" INT 0 65535;
BA_DEF_ BO_ "GenMsgCycleTimeFast" INT 0 65535;
BA_DEF_ BO_ "GenMsgCycleTime" INT 0 65535;
BA_DEF_ BO_ "GenMsgDelayTime" INT 0 65535;
BA_DEF_ BO_ "DiagState" ENUM "No","Yes";
BA_DEF_ BU_ "NodeLayerModules" STRING ;
BA_DEF_ BU_ "Description" STRING ;
BA_DEF_ BU_ "NmStationAddress" HEX 0 255;
BA_DEF_ BU_ "NmNode" ENUM "No","Yes";
BA_DEF_ BU_ "ILUsed" ENUM "No","Yes";
BA_DEF_ BU_ "NmNodeType" ENUM "kMaster","kSlave15","kSlave30","none";
BA_DEF_ BU_ "NwmNodeType" ENUM "kMaster","kSlave15","kSlave30","none";
BA_DEF_ BU_ "TpOwnSystemEcuNumber" HEX 0 255;
BA_DEF_ "Manufacturer" STRING ;
BA_DEF_ "NmType" STRING ;
BA_DEF_ "BusType" STRING ;
BA_DEF_ "Baudrate" INT 0 1000000;
BA_DEF_ "DBName" STRING ;
BA_DEF_ "Version" HEX 0 255;
BA_DEF_ "VersionWeek" INT 0 53;
BA_DEF_ "VersionYear" INT 0 99;
BA_DEF_DEF_ "Accuracy" "";
BA_DEF_DEF_ "Event trans." "No";
BA_DEF_DEF_ "GenSigStartValue" 0;
BA_DEF_DEF_ "GenSigInactiveValue" 0;
BA_DEF_DEF_ "GenSigSendType" "NoSigSendType";
BA_DEF_DEF_ "DiagRequest" "No";
BA_DEF_DEF_ "Period [ms]" 0;
BA_DEF_DEF_ "Type" "-";
BA_DEF_DEF_ "DiagResponse" "No";
BA_DEF_DEF_ "NmMessage" "No";
BA_DEF_DEF_ "GenMsgSendType" "NoMsgSendType";
BA_DEF_DEF_ "GenMsgTimeoutTime" 0;
BA_DEF_DEF_ "GenMsgNrOfRepetition" 0;
BA_DEF_DEF_ "GenMsgILSupport" "No";
BA_DEF_DEF_ "GenMsgStartDelayTime" 0;
BA_DEF_DEF_ "GenMsgCycleTimeFast" 0;
BA_DEF_DEF_ "GenMsgCycleTime" 0;
BA_DEF_DEF_ "GenMsgDelayTime" 0;
BA_DEF_DEF_ "DiagState" "No";
BA_DEF_DEF_ "NodeLayerModules" "Osek_TP.dll";
BA_DEF_DEF_ "Description" "";
BA_DEF_DEF_ "NmStationAddress" 0;
BA_DEF_DEF_ "NmNode" "Yes";
BA_DEF_DEF_ "ILUsed" "Yes";
BA_DEF_DEF_ "NmNodeType" "none";
BA_DEF_DEF_ "NwmNodeType" "none";
BA_DEF_DEF_ "TpOwnSystemEcuNumber" 0;
BA_DEF_DEF_ "Manufacturer" "Fiat";
BA_DEF_DEF_ "NmType" "";
BA_DEF_DEF_ "BusType" "CAN";
BA_DEF_DEF_ "Baudrate" 500000;
BA_DEF_DEF_ "DBName" "CAN";
BA_DEF_DEF_ "Version" 160;
BA_DEF_DEF_ "VersionWeek" 28;
BA_DEF_DEF_ "VersionYear" 15;
BA_ "NmType" "Fiat_Class_C";
BA_ "DBName" "CAN-C1";
BA_ "Description" BU_ AGSM "Automatic Gearbox Shifter Module";
BA_ "NmStationAddress" BU_ AGSM 22;
BA_ "TpOwnSystemEcuNumber" BU_ AGSM 31;
BA_ "Description" BU_ BCM "Body Control Module";
BA_ "NmNodeType" BU_ BCM 0;
BA_ "NwmNodeType" BU_ BCM 0;
BA_ "TpOwnSystemEcuNumber" BU_ BCM 64;
BA_ "Description" BU_ BSM "Braking System Module";
BA_ "NmStationAddress" BU_ BSM 6;
BA_ "NmNodeType" BU_ BSM 2;
BA_ "NwmNodeType" BU_ BSM 2;
BA_ "TpOwnSystemEcuNumber" BU_ BSM 40;
BA_ "Description" BU_ CDCM "Chassis Domain Control Module";
BA_ "NmStationAddress" BU_ CDCM 102;
BA_ "TpOwnSystemEcuNumber" BU_ CDCM 32;
BA_ "Description" BU_ DASM "Driver Assistant System Module";
BA_ "NmStationAddress" BU_ DASM 57;
BA_ "TpOwnSystemEcuNumber" BU_ DASM 42;
BA_ "Description" BU_ DCSM "Dual Clutch Shifter Module";
BA_ "NmStationAddress" BU_ DCSM 22;
BA_ "TpOwnSystemEcuNumber" BU_ DCSM 31;
BA_ "Description" BU_ DCTM "Dual Clutch Transmission Module";
BA_ "NmStationAddress" BU_ DCTM 11;
BA_ "TpOwnSystemEcuNumber" BU_ DCTM 24;
BA_ "Description" BU_ DIAG_TEST "Diagnostic Tester";
BA_ "Description" BU_ DTCM "Drive Train Control Module";
BA_ "NmStationAddress" BU_ DTCM 67;
BA_ "TpOwnSystemEcuNumber" BU_ DTCM 26;
BA_ "Description" BU_ ECM "Engine Control Module";
BA_ "NmStationAddress" BU_ ECM 1;
BA_ "TpOwnSystemEcuNumber" BU_ ECM 16;
BA_ "Description" BU_ ECM2 "Engine Control Module Slave";
BA_ "NmStationAddress" BU_ ECM2 107;
BA_ "TpOwnSystemEcuNumber" BU_ ECM2 23;
BA_ "Description" BU_ IPC "Instrument Panel Cluster";
BA_ "NmStationAddress" BU_ IPC 3;
BA_ "NmNodeType" BU_ IPC 2;
BA_ "NwmNodeType" BU_ IPC 2;
BA_ "TpOwnSystemEcuNumber" BU_ IPC 96;
BA_ "Description" BU_ ORC "Occupant Restraint Control";
BA_ "NmStationAddress" BU_ ORC 26;
BA_ "TpOwnSystemEcuNumber" BU_ ORC 192;
BA_ "Description" BU_ RFHM "Radio Frequency Hub Module";
BA_ "NmStationAddress" BU_ RFHM 65;
BA_ "NmNodeType" BU_ RFHM 2;
BA_ "NwmNodeType" BU_ RFHM 2;
BA_ "TpOwnSystemEcuNumber" BU_ RFHM 199;
BA_ "Description" BU_ TBM "Telematic Box Module";
BA_ "NmStationAddress" BU_ TBM 35;
BA_ "TpOwnSystemEcuNumber" BU_ TBM 198;
BA_ "Description" BU_ TCM "Transmission Control Module";
BA_ "NmStationAddress" BU_ TCM 11;
BA_ "NmNodeType" BU_ TCM 2;
BA_ "NwmNodeType" BU_ TCM 2;
BA_ "TpOwnSystemEcuNumber" BU_ TCM 24;
BA_ "Period [ms]" BO_ 599 100;
BA_ "Type" BO_ 599 3;
BA_ "GenMsgSendType" BO_ 599 0;
BA_ "GenMsgNrOfRepetition" BO_ 599 2;
BA_ "GenMsgILSupport" BO_ 599 1;
BA_ "GenMsgStartDelayTime" BO_ 599 50;
BA_ "GenMsgCycleTimeFast" BO_ 599 20;
BA_ "GenMsgCycleTime" BO_ 599 100;
BA_ "GenMsgDelayTime" BO_ 599 10;
BA_ "Period [ms]" BO_ 1447 1000;
BA_ "Type" BO_ 1447 3;
BA_ "GenMsgSendType" BO_ 1447 0;
BA_ "GenMsgTimeoutTime" BO_ 1447 2500;
BA_ "GenMsgILSupport" BO_ 1447 1;
BA_ "GenMsgStartDelayTime" BO_ 1447 500;
BA_ "GenMsgCycleTime" BO_ 1447 1000;
BA_ "GenMsgDelayTime" BO_ 1447 50;
BA_ "Period [ms]" BO_ 1050 100;
BA_ "Type" BO_ 1050 1;
BA_ "GenMsgSendType" BO_ 1050 0;
BA_ "GenMsgILSupport" BO_ 1050 1;
BA_ "GenMsgStartDelayTime" BO_ 1050 90;
BA_ "GenMsgCycleTime" BO_ 1050 100;
BA_ "Type" BO_ 247 8;
BA_ "GenMsgTimeoutTime" BO_ 247 2500;
BA_ "GenMsgILSupport" BO_ 247 1;
BA_ "GenMsgDelayTime" BO_ 247 10;
BA_ "Period [ms]" BO_ 250 10;
BA_ "Type" BO_ 250 1;
BA_ "GenMsgSendType" BO_ 250 0;
BA_ "GenMsgILSupport" BO_ 250 1;
BA_ "GenMsgStartDelayTime" BO_ 250 5;
BA_ "GenMsgCycleTime" BO_ 250 10;
BA_ "Period [ms]" BO_ 1994 1000;
BA_ "Type" BO_ 1994 1;
BA_ "GenMsgSendType" BO_ 1994 0;
BA_ "GenMsgTimeoutTime" BO_ 1994 2500;
BA_ "GenMsgILSupport" BO_ 1994 1;
BA_ "GenMsgCycleTime" BO_ 1994 1000;
BA_ "Type" BO_ 245 8;
BA_ "GenMsgTimeoutTime" BO_ 245 2500;
BA_ "GenMsgILSupport" BO_ 245 1;
BA_ "GenMsgDelayTime" BO_ 245 10;
BA_ "Period [ms]" BO_ 1446 1000;
BA_ "Type" BO_ 1446 3;
BA_ "GenMsgSendType" BO_ 1446 0;
BA_ "GenMsgTimeoutTime" BO_ 1446 2500;
BA_ "GenMsgILSupport" BO_ 1446 1;
BA_ "GenMsgStartDelayTime" BO_ 1446 500;
BA_ "GenMsgCycleTime" BO_ 1446 1000;
BA_ "GenMsgDelayTime" BO_ 1446 50;
BA_ "Period [ms]" BO_ 748 50;
BA_ "Type" BO_ 748 1;
BA_ "GenMsgSendType" BO_ 748 0;
BA_ "GenMsgILSupport" BO_ 748 1;
BA_ "GenMsgStartDelayTime" BO_ 748 25;
BA_ "GenMsgCycleTime" BO_ 748 50;
BA_ "Period [ms]" BO_ 900 250;
BA_ "Type" BO_ 900 3;
BA_ "GenMsgSendType" BO_ 900 0;
BA_ "GenMsgILSupport" BO_ 900 1;
BA_ "GenMsgStartDelayTime" BO_ 900 60;
BA_ "GenMsgCycleTime" BO_ 900 250;
BA_ "GenMsgDelayTime" BO_ 900 20;
BA_ "Period [ms]" BO_ 1349 250;
BA_ "Type" BO_ 1349 1;
BA_ "GenMsgSendType" BO_ 1349 0;
BA_ "GenMsgILSupport" BO_ 1349 1;
BA_ "GenMsgStartDelayTime" BO_ 1349 190;
BA_ "GenMsgCycleTime" BO_ 1349 250;
BA_ "Period [ms]" BO_ 1201 500;
BA_ "Type" BO_ 1201 3;
BA_ "GenMsgSendType" BO_ 1201 0;
BA_ "GenMsgILSupport" BO_ 1201 1;
BA_ "GenMsgStartDelayTime" BO_ 1201 250;
BA_ "GenMsgCycleTime" BO_ 1201 500;
BA_ "GenMsgDelayTime" BO_ 1201 20;
BA_ "Period [ms]" BO_ 1049 100;
BA_ "Type" BO_ 1049 1;
BA_ "GenMsgSendType" BO_ 1049 0;
BA_ "GenMsgTimeoutTime" BO_ 1049 2500;
BA_ "GenMsgILSupport" BO_ 1049 1;
BA_ "GenMsgStartDelayTime" BO_ 1049 60;
BA_ "GenMsgCycleTime" BO_ 1049 100;
BA_ "Period [ms]" BO_ 497 20;
BA_ "Type" BO_ 497 1;
BA_ "GenMsgSendType" BO_ 497 0;
BA_ "GenMsgILSupport" BO_ 497 1;
BA_ "GenMsgStartDelayTime" BO_ 497 5;
BA_ "GenMsgCycleTime" BO_ 497 20;
BA_ "Period [ms]" BO_ 257 10;
BA_ "Type" BO_ 257 1;
BA_ "GenMsgSendType" BO_ 257 0;
BA_ "GenMsgILSupport" BO_ 257 1;
BA_ "GenMsgStartDelayTime" BO_ 257 5;
BA_ "GenMsgCycleTime" BO_ 257 10;
BA_ "Period [ms]" BO_ 506 20;
BA_ "Type" BO_ 506 1;
BA_ "GenMsgSendType" BO_ 506 0;
BA_ "GenMsgILSupport" BO_ 506 1;
BA_ "GenMsgCycleTime" BO_ 506 20;
BA_ "Period [ms]" BO_ 263 10;
BA_ "Type" BO_ 263 1;
BA_ "GenMsgSendType" BO_ 263 0;
BA_ "GenMsgILSupport" BO_ 263 1;
BA_ "GenMsgStartDelayTime" BO_ 263 5;
BA_ "GenMsgCycleTime" BO_ 263 10;
BA_ "Period [ms]" BO_ 259 10;
BA_ "Type" BO_ 259 1;
BA_ "GenMsgSendType" BO_ 259 0;
BA_ "GenMsgILSupport" BO_ 259 1;
BA_ "GenMsgStartDelayTime" BO_ 259 5;
BA_ "GenMsgCycleTime" BO_ 259 10;
BA_ "Period [ms]" BO_ 501 20;
BA_ "Type" BO_ 501 1;
BA_ "GenMsgSendType" BO_ 501 0;
BA_ "GenMsgILSupport" BO_ 501 1;
BA_ "GenMsgStartDelayTime" BO_ 501 15;
BA_ "GenMsgCycleTime" BO_ 501 20;
BA_ "Period [ms]" BO_ 498 20;
BA_ "Type" BO_ 498 1;
BA_ "GenMsgSendType" BO_ 498 0;
BA_ "GenMsgILSupport" BO_ 498 1;
BA_ "GenMsgStartDelayTime" BO_ 498 10;
BA_ "GenMsgCycleTime" BO_ 498 20;
BA_ "Period [ms]" BO_ 1048 100;
BA_ "Type" BO_ 1048 3;
BA_ "GenMsgSendType" BO_ 1048 0;
BA_ "GenMsgILSupport" BO_ 1048 1;
BA_ "GenMsgStartDelayTime" BO_ 1048 50;
BA_ "GenMsgCycleTime" BO_ 1048 100;
BA_ "GenMsgDelayTime" BO_ 1048 20;
BA_ "Period [ms]" BO_ 1199 500;
BA_ "Type" BO_ 1199 3;
BA_ "GenMsgSendType" BO_ 1199 0;
BA_ "GenMsgNrOfRepetition" BO_ 1199 2;
BA_ "GenMsgILSupport" BO_ 1199 1;
BA_ "GenMsgStartDelayTime" BO_ 1199 250;
BA_ "GenMsgCycleTimeFast" BO_ 1199 10;
BA_ "GenMsgCycleTime" BO_ 1199 500;
BA_ "GenMsgDelayTime" BO_ 1199 10;
BA_ "Period [ms]" BO_ 1453 1000;
BA_ "Type" BO_ 1453 3;
BA_ "GenMsgSendType" BO_ 1453 0;
BA_ "GenMsgTimeoutTime" BO_ 1453 2500;
BA_ "GenMsgILSupport" BO_ 1453 1;
BA_ "GenMsgStartDelayTime" BO_ 1453 500;
BA_ "GenMsgCycleTime" BO_ 1453 1000;
BA_ "GenMsgDelayTime" BO_ 1453 20;
BA_ "Period [ms]" BO_ 284 10;
BA_ "Type" BO_ 284 1;
BA_ "GenMsgSendType" BO_ 284 0;
BA_ "GenMsgTimeoutTime" BO_ 284 2500;
BA_ "GenMsgILSupport" BO_ 284 1;
BA_ "GenMsgStartDelayTime" BO_ 284 10;
BA_ "GenMsgCycleTime" BO_ 284 10;
BA_ "Period [ms]" BO_ 254 10;
BA_ "Type" BO_ 254 1;
BA_ "GenMsgSendType" BO_ 254 0;
BA_ "GenMsgTimeoutTime" BO_ 254 2500;
BA_ "GenMsgILSupport" BO_ 254 1;
BA_ "GenMsgCycleTime" BO_ 254 10;
BA_ "Period [ms]" BO_ 1451 1000;
BA_ "Type" BO_ 1451 3;
BA_ "GenMsgSendType" BO_ 1451 0;
BA_ "GenMsgILSupport" BO_ 1451 1;
BA_ "GenMsgStartDelayTime" BO_ 1451 500;
BA_ "GenMsgCycleTime" BO_ 1451 1000;
BA_ "GenMsgDelayTime" BO_ 1451 20;
BA_ "Period [ms]" BO_ 288 10;
BA_ "Type" BO_ 288 1;
BA_ "GenMsgSendType" BO_ 288 0;
BA_ "GenMsgILSupport" BO_ 288 1;
BA_ "GenMsgCycleTime" BO_ 288 10;
BA_ "Type" BO_ 2651930624 8;
BA_ "GenMsgTimeoutTime" BO_ 2651930624 2500;
BA_ "GenMsgILSupport" BO_ 2651930624 1;
BA_ "GenMsgDelayTime" BO_ 2651930624 10;
BA_ "Type" BO_ 2651930681 11;
BA_ "GenMsgTimeoutTime" BO_ 2651930681 2500;
BA_ "GenMsgILSupport" BO_ 2651930681 1;
BA_ "Type" BO_ 2651930691 11;
BA_ "GenMsgTimeoutTime" BO_ 2651930691 2500;
BA_ "GenMsgILSupport" BO_ 2651930691 1;
BA_ "Type" BO_ 2651930625 11;
BA_ "GenMsgTimeoutTime" BO_ 2651930625 2500;
BA_ "GenMsgILSupport" BO_ 2651930625 1;
BA_ "Type" BO_ 2651930731 11;
BA_ "GenMsgTimeoutTime" BO_ 2651930731 2500;
BA_ "GenMsgILSupport" BO_ 2651930731 1;
BA_ "Type" BO_ 2651930627 11;
BA_ "GenMsgILSupport" BO_ 2651930627 1;
BA_ "Type" BO_ 2651930689 11;
BA_ "GenMsgTimeoutTime" BO_ 2651930689 2500;
BA_ "GenMsgILSupport" BO_ 2651930689 1;
BA_ "Type" BO_ 2651930646 11;
BA_ "GenMsgILSupport" BO_ 2651930646 1;
BA_ "Type" BO_ 2651930635 11;
BA_ "GenMsgTimeoutTime" BO_ 2651930635 2500;
BA_ "GenMsgILSupport" BO_ 2651930635 1;
BA_ "Period [ms]" BO_ 601 100;
BA_ "Type" BO_ 601 3;
BA_ "GenMsgSendType" BO_ 601 0;
BA_ "GenMsgNrOfRepetition" BO_ 601 3;
BA_ "GenMsgILSupport" BO_ 601 1;
BA_ "GenMsgStartDelayTime" BO_ 601 80;
BA_ "GenMsgCycleTimeFast" BO_ 601 20;
BA_ "GenMsgCycleTime" BO_ 601 100;
BA_ "GenMsgDelayTime" BO_ 601 20;
BA_ "Period [ms]" BO_ 598 100;
BA_ "Type" BO_ 598 3;
BA_ "GenMsgSendType" BO_ 598 0;
BA_ "GenMsgILSupport" BO_ 598 1;
BA_ "GenMsgStartDelayTime" BO_ 598 20;
BA_ "GenMsgCycleTime" BO_ 598 100;
BA_ "GenMsgDelayTime" BO_ 598 20;
BA_ "Period [ms]" BO_ 348 100;
BA_ "Type" BO_ 348 10;
BA_ "GenMsgSendType" BO_ 348 0;
BA_ "GenMsgTimeoutTime" BO_ 348 2500;
BA_ "GenMsgNrOfRepetition" BO_ 348 2;
BA_ "GenMsgILSupport" BO_ 348 1;
BA_ "GenMsgStartDelayTime" BO_ 348 10;
BA_ "GenMsgCycleTimeFast" BO_ 348 20;
BA_ "GenMsgCycleTime" BO_ 348 100;
BA_ "GenMsgDelayTime" BO_ 348 20;
BA_ "Type" BO_ 2564554481 8;
BA_ "GenMsgTimeoutTime" BO_ 2564554481 2500;
BA_ "DiagState" BO_ 2564554481 1;
BA_ "DiagRequest" BO_ 2564440305 1;
BA_ "Type" BO_ 2564440305 8;
BA_ "DiagRequest" BO_ 2564434673 1;
BA_ "Type" BO_ 2564434673 8;
BA_ "GenMsgTimeoutTime" BO_ 2564434673 2500;
BA_ "DiagRequest" BO_ 2564430577 1;
BA_ "Type" BO_ 2564430577 8;
BA_ "GenMsgTimeoutTime" BO_ 2564430577 2500;
BA_ "DiagRequest" BO_ 2564428017 1;
BA_ "Type" BO_ 2564428017 8;
BA_ "DiagRequest" BO_ 2564429809 1;
BA_ "Type" BO_ 2564429809 8;
BA_ "Type" BO_ 2564502513 8;
BA_ "DiagState" BO_ 2564502513 1;
BA_ "DiagRequest" BO_ 2564448497 1;
BA_ "Type" BO_ 2564448497 8;
BA_ "DiagRequest" BO_ 2564474865 1;
BA_ "Type" BO_ 2564474865 8;
BA_ "DiagRequest" BO_ 2564431857 1;
BA_ "Type" BO_ 2564431857 8;
BA_ "DiagRequest" BO_ 2564430065 1;
BA_ "Type" BO_ 2564430065 8;
BA_ "Type" BO_ 2564485440 8;
BA_ "DiagResponse" BO_ 2564485440 1;
BA_ "Type" BO_ 2564485418 8;
BA_ "DiagResponse" BO_ 2564485418 1;
BA_ "Type" BO_ 2564485402 8;
BA_ "DiagResponse" BO_ 2564485402 1;
BA_ "Type" BO_ 2564485392 8;
BA_ "DiagResponse" BO_ 2564485392 1;
BA_ "Type" BO_ 2564485399 8;
BA_ "DiagResponse" BO_ 2564485399 1;
BA_ "Type" BO_ 2564485472 8;
BA_ "DiagResponse" BO_ 2564485472 1;
BA_ "Type" BO_ 2564485575 8;
BA_ "DiagResponse" BO_ 2564485575 1;
BA_ "Type" BO_ 2564485407 8;
BA_ "DiagResponse" BO_ 2564485407 1;
BA_ "Type" BO_ 2564485400 8;
BA_ "DiagResponse" BO_ 2564485400 1;
BA_ "Period [ms]" BO_ 507 20;
BA_ "Type" BO_ 507 1;
BA_ "GenMsgSendType" BO_ 507 0;
BA_ "GenMsgILSupport" BO_ 507 1;
BA_ "GenMsgStartDelayTime" BO_ 507 10;
BA_ "GenMsgCycleTime" BO_ 507 20;
BA_ "Period [ms]" BO_ 752 100;
BA_ "Type" BO_ 752 1;
BA_ "GenMsgSendType" BO_ 752 0;
BA_ "GenMsgTimeoutTime" BO_ 752 2500;
BA_ "GenMsgILSupport" BO_ 752 1;
BA_ "GenMsgCycleTime" BO_ 752 100;
BA_ "Period [ms]" BO_ 1846 100;
BA_ "Type" BO_ 1846 1;
BA_ "GenMsgSendType" BO_ 1846 0;
BA_ "GenMsgTimeoutTime" BO_ 1846 2500;
BA_ "GenMsgILSupport" BO_ 1846 1;
BA_ "GenMsgStartDelayTime" BO_ 1846 90;
BA_ "GenMsgCycleTime" BO_ 1846 100;
BA_ "Period [ms]" BO_ 252 10;
BA_ "Type" BO_ 252 1;
BA_ "GenMsgSendType" BO_ 252 0;
BA_ "GenMsgILSupport" BO_ 252 1;
BA_ "GenMsgStartDelayTime" BO_ 252 4;
BA_ "GenMsgCycleTime" BO_ 252 10;
BA_ "Period [ms]" BO_ 1445 1000;
BA_ "Type" BO_ 1445 3;
BA_ "GenMsgSendType" BO_ 1445 0;
BA_ "GenMsgILSupport" BO_ 1445 1;
BA_ "GenMsgStartDelayTime" BO_ 1445 500;
BA_ "GenMsgCycleTime" BO_ 1445 1000;
BA_ "GenMsgDelayTime" BO_ 1445 20;
BA_ "Period [ms]" BO_ 1202 500;
BA_ "Type" BO_ 1202 3;
BA_ "GenMsgSendType" BO_ 1202 0;
BA_ "GenMsgILSupport" BO_ 1202 1;
BA_ "GenMsgStartDelayTime" BO_ 1202 250;
BA_ "GenMsgCycleTime" BO_ 1202 500;
BA_ "GenMsgDelayTime" BO_ 1202 20;
BA_ "Period [ms]" BO_ 1051 100;
BA_ "Type" BO_ 1051 1;
BA_ "GenMsgSendType" BO_ 1051 0;
BA_ "GenMsgILSupport" BO_ 1051 1;
BA_ "GenMsgStartDelayTime" BO_ 1051 84;
BA_ "GenMsgCycleTime" BO_ 1051 100;
BA_ "Period [ms]" BO_ 255 10;
BA_ "Type" BO_ 255 1;
BA_ "GenMsgSendType" BO_ 255 0;
BA_ "GenMsgILSupport" BO_ 255 1;
BA_ "GenMsgStartDelayTime" BO_ 255 6;
BA_ "GenMsgCycleTime" BO_ 255 10;
BA_ "Period [ms]" BO_ 251 10;
BA_ "Type" BO_ 251 1;
BA_ "GenMsgSendType" BO_ 251 0;
BA_ "GenMsgILSupport" BO_ 251 1;
BA_ "GenMsgStartDelayTime" BO_ 251 2;
BA_ "GenMsgCycleTime" BO_ 251 10;
BA_ "Period [ms]" BO_ 496 20;
BA_ "Type" BO_ 496 1;
BA_ "GenMsgSendType" BO_ 496 0;
BA_ "GenMsgTimeoutTime" BO_ 496 2500;
BA_ "GenMsgILSupport" BO_ 496 1;
BA_ "GenMsgCycleTime" BO_ 496 20;
BA_ "Period [ms]" BO_ 749 50;
BA_ "Type" BO_ 749 1;
BA_ "GenMsgSendType" BO_ 749 0;
BA_ "GenMsgILSupport" BO_ 749 1;
BA_ "GenMsgStartDelayTime" BO_ 749 8;
BA_ "GenMsgCycleTime" BO_ 749 50;
BA_ "Period [ms]" BO_ 751 50;
BA_ "Type" BO_ 751 1;
BA_ "GenMsgSendType" BO_ 751 0;
BA_ "GenMsgILSupport" BO_ 751 1;
BA_ "GenMsgStartDelayTime" BO_ 751 42;
BA_ "GenMsgCycleTime" BO_ 751 50;
BA_ "Period [ms]" BO_ 550 1000;
BA_ "Type" BO_ 550 3;
BA_ "GenMsgSendType" BO_ 550 0;
BA_ "GenMsgILSupport" BO_ 550 1;
BA_ "GenMsgStartDelayTime" BO_ 550 300;
BA_ "GenMsgCycleTime" BO_ 550 1000;
BA_ "GenMsgDelayTime" BO_ 550 20;
BA_ "Period [ms]" BO_ 1854 250;
BA_ "Type" BO_ 1854 3;
BA_ "GenMsgSendType" BO_ 1854 0;
BA_ "GenMsgILSupport" BO_ 1854 1;
BA_ "GenMsgStartDelayTime" BO_ 1854 220;
BA_ "GenMsgCycleTime" BO_ 1854 250;
BA_ "GenMsgDelayTime" BO_ 1854 20;
BA_ "Type" BO_ 222 11;
BA_ "GenMsgTimeoutTime" BO_ 222 2500;
BA_ "GenMsgILSupport" BO_ 222 1;
BA_ "Type" BO_ 100 8;
BA_ "GenMsgILSupport" BO_ 100 1;
BA_ "GenMsgDelayTime" BO_ 100 10;
BA_ "Type" BO_ 104 11;
BA_ "GenMsgILSupport" BO_ 104 1;
BA_ "GenMsgDelayTime" BO_ 104 10;
BA_ "GenSigStartValue" SG_ 599 AirBagFailSts 2;
BA_ "Event trans." SG_ 599 PsngrBagChargeSts 0;
BA_ "GenSigStartValue" SG_ 599 PsngrBagChargeSts 3;
BA_ "GenSigSendType" SG_ 599 PsngrBagChargeSts 4;
BA_ "Event trans." SG_ 599 SBR1RowCentralSeatBuckleFailSts 0;
BA_ "GenSigStartValue" SG_ 599 SBR1RowCentralSeatBuckleFailSts 3;
BA_ "GenSigSendType" SG_ 599 SBR1RowCentralSeatBuckleFailSts 4;
BA_ "Event trans." SG_ 599 SBR1RowCentralSeatPPDFailSts 0;
BA_ "GenSigStartValue" SG_ 599 SBR1RowCentralSeatPPDFailSts 3;
BA_ "GenSigSendType" SG_ 599 SBR1RowCentralSeatPPDFailSts 4;
BA_ "Event trans." SG_ 599 SBR1RowCentralSeatSts 0;
BA_ "GenSigStartValue" SG_ 599 SBR1RowCentralSeatSts 7;
BA_ "GenSigSendType" SG_ 599 SBR1RowCentralSeatSts 4;
BA_ "Event trans." SG_ 599 SBR1RowDriverSeatFailSts 0;
BA_ "GenSigStartValue" SG_ 599 SBR1RowDriverSeatFailSts 3;
BA_ "GenSigSendType" SG_ 599 SBR1RowDriverSeatFailSts 4;
BA_ "Event trans." SG_ 599 SBR1RowDriverSeatSts 0;
BA_ "GenSigStartValue" SG_ 599 SBR1RowDriverSeatSts 3;
BA_ "GenSigSendType" SG_ 599 SBR1RowDriverSeatSts 4;
BA_ "Event trans." SG_ 599 SBR1RowPsngrSeatBuckleFailSts 0;
BA_ "GenSigStartValue" SG_ 599 SBR1RowPsngrSeatBuckleFailSts 3;
BA_ "GenSigSendType" SG_ 599 SBR1RowPsngrSeatBuckleFailSts 4;
BA_ "Event trans." SG_ 599 SBR1RowPsngrSeatPPDFailSts 0;
BA_ "GenSigStartValue" SG_ 599 SBR1RowPsngrSeatPPDFailSts 3;
BA_ "GenSigSendType" SG_ 599 SBR1RowPsngrSeatPPDFailSts 4;
BA_ "Event trans." SG_ 599 SBR1RowPsngrSeatSts 0;
BA_ "GenSigStartValue" SG_ 599 SBR1RowPsngrSeatSts 7;
BA_ "GenSigSendType" SG_ 599 SBR1RowPsngrSeatSts 4;
BA_ "Event trans." SG_ 599 SBR2RowCentralSeatSts 0;
BA_ "GenSigStartValue" SG_ 599 SBR2RowCentralSeatSts 3;
BA_ "GenSigSendType" SG_ 599 SBR2RowCentralSeatSts 4;
BA_ "Event trans." SG_ 599 SBR2RowLeftSeatSts 0;
BA_ "GenSigStartValue" SG_ 599 SBR2RowLeftSeatSts 3;
BA_ "GenSigSendType" SG_ 599 SBR2RowLeftSeatSts 4;
BA_ "Event trans." SG_ 599 SBR2RowRightSeatSts 0;
BA_ "GenSigStartValue" SG_ 599 SBR2RowRightSeatSts 3;
BA_ "GenSigSendType" SG_ 599 SBR2RowRightSeatSts 4;
BA_ "Event trans." SG_ 1447 DrvSbltUnFltr 0;
BA_ "GenSigSendType" SG_ 1447 DrvSbltUnFltr 3;
BA_ "Accuracy" SG_ 1050 BatteryCurrentLevel "+/-1%";
BA_ "Accuracy" SG_ 1050 BatteryTemperature "6";
BA_ "Accuracy" SG_ 1050 BatteryVoltageLevelHP "+/-1%";
BA_ "GenSigStartValue" SG_ 1050 BatteryVoltageLevelHP 4;
BA_ "Accuracy" SG_ 1050 BCMSAMFailSts "-";
BA_ "Accuracy" SG_ 1050 IBSFailSts "-";
BA_ "Accuracy" SG_ 1050 StateOfCharge "1%";
BA_ "GenSigStartValue" SG_ 1050 StateOfCharge 100;
BA_ "Accuracy" SG_ 1050 VoltageMax "0,025";
BA_ "Accuracy" SG_ 1050 VoltageMin "0,025";
BA_ "Accuracy" SG_ 247 ControlEncoding_TRM_Rq "-";
BA_ "Event trans." SG_ 247 ControlEncoding_TRM_Rq 0;
BA_ "GenSigSendType" SG_ 247 ControlEncoding_TRM_Rq 1;
BA_ "GenSigStartValue" SG_ 247 TxpAuthRequest 1;
BA_ "GenSigStartValue" SG_ 247 TxpReadRequest 1;
BA_ "Accuracy" SG_ 250 BCMFpsCommand "-";
BA_ "Accuracy" SG_ 250 BCMFpsConfirm "-";
BA_ "GenSigStartValue" SG_ 250 BCMFpsConfirm 1;
BA_ "Accuracy" SG_ 250 BCMFpsFailSts "-";
BA_ "Accuracy" SG_ 250 BrakePedalSwitchNCFailSts "-";
BA_ "Accuracy" SG_ 250 BrakePedalSwitchNCSts "-";
BA_ "Accuracy" SG_ 250 BrakePedalSwitchNOFailSts "-";
BA_ "Accuracy" SG_ 250 BrakePedalSwitchNOSts "-";
BA_ "Accuracy" SG_ 250 EngineOffRequest "-";
BA_ "Accuracy" SG_ 250 MessageCounter_BC "-";
BA_ "Accuracy" SG_ 250 TurnIndicatorSts "-";
BA_ "Accuracy" SG_ 1994 IgnitionOnCounter "-";
BA_ "Accuracy" SG_ 245 MinicryptReceptionSts "-";
BA_ "Event trans." SG_ 245 MinicryptReceptionSts 0;
BA_ "GenSigSendType" SG_ 245 MinicryptReceptionSts 1;
BA_ "Event trans." SG_ 1446 A2D_DRV_TEMP_DR_POS 0;
BA_ "GenSigStartValue" SG_ 1446 A2D_DRV_TEMP_DR_POS 819;
BA_ "GenSigSendType" SG_ 1446 A2D_DRV_TEMP_DR_POS 3;
BA_ "Event trans." SG_ 1446 A2D_FT_HVAC_BLOWER_VOLTAGE 0;
BA_ "GenSigStartValue" SG_ 1446 A2D_FT_HVAC_BLOWER_VOLTAGE 479;
BA_ "GenSigSendType" SG_ 1446 A2D_FT_HVAC_BLOWER_VOLTAGE 3;
BA_ "Event trans." SG_ 1446 AcOutputCurrentSts 0;
BA_ "GenSigSendType" SG_ 1446 AcOutputCurrentSts 3;
BA_ "Event trans." SG_ 1446 StopStartClimateInfo 0;
BA_ "GenSigSendType" SG_ 1446 StopStartClimateInfo 3;
BA_ "Event trans." SG_ 900 CmdIgn_FailSts 0;
BA_ "GenSigSendType" SG_ 900 CmdIgn_FailSts 3;
BA_ "Event trans." SG_ 900 CmdIgnSts 0;
BA_ "GenSigSendType" SG_ 900 CmdIgnSts 3;
BA_ "Event trans." SG_ 900 DriveStyleSts 0;
BA_ "GenSigSendType" SG_ 900 DriveStyleSts 3;
BA_ "Event trans." SG_ 900 ParkBrakeSts 0;
BA_ "GenSigSendType" SG_ 900 ParkBrakeSts 3;
BA_ "Event trans." SG_ 900 SuspensionLevel 0;
BA_ "GenSigSendType" SG_ 900 SuspensionLevel 3;
BA_ "GenSigStartValue" SG_ 1349 InternalLightLevel 5;
BA_ "GenSigStartValue" SG_ 1349 NotFilteredFuelLevel 255;
BA_ "GenSigStartValue" SG_ 1201 BatteryStateOfFunction 63;
BA_ "Event trans." SG_ 1201 CompressorACReqSts 0;
BA_ "GenSigSendType" SG_ 1201 CompressorACReqSts 3;
BA_ "Event trans." SG_ 1201 DriverDoorFailSts 0;
BA_ "GenSigSendType" SG_ 1201 DriverDoorFailSts 3;
BA_ "Event trans." SG_ 1201 DriverDoorSts 0;
BA_ "GenSigSendType" SG_ 1201 DriverDoorSts 3;
BA_ "Event trans." SG_ 1201 ExteriorRearReleaseSwitchSts 0;
BA_ "GenSigSendType" SG_ 1201 ExteriorRearReleaseSwitchSts 3;
BA_ "Event trans." SG_ 1201 FOBSearchRequest 0;
BA_ "GenSigSendType" SG_ 1201 FOBSearchRequest 3;
BA_ "Event trans." SG_ 1201 RemStActvSts 0;
BA_ "GenSigSendType" SG_ 1201 RemStActvSts 3;
BA_ "Event trans." SG_ 1201 SpSt_Pad1 0;
BA_ "GenSigSendType" SG_ 1201 SpSt_Pad1 3;
BA_ "GenSigStartValue" SG_ 1049 DriverDoorAjarXtionSts 1;
BA_ "GenSigStartValue" SG_ 1049 FUEL_VOLT 255;
BA_ "GenSigStartValue" SG_ 1049 FUEL_VOLT2 255;
BA_ "GenSigStartValue" SG_ 1049 PsngrDoorAjarXtionSts 1;
BA_ "GenSigStartValue" SG_ 497 BrkBstrVac 255;
BA_ "GenSigStartValue" SG_ 257 Ft_RrAxleCoupling_TrqRq 254;
BA_ "GenSigStartValue" SG_ 257 MasterCylinderPressure 1023;
BA_ "Event trans." SG_ 263 BrakeTravelSts 0;
BA_ "GenSigStartValue" SG_ 259 MuSplit 3;
BA_ "GenSigStartValue" SG_ 259 OverSteering 63;
BA_ "GenSigStartValue" SG_ 259 TorqueRequest 2047;
BA_ "GenSigStartValue" SG_ 259 TorqueRequest_FAST 2047;
BA_ "GenSigStartValue" SG_ 259 UnderSteering 63;
BA_ "GenSigStartValue" SG_ 501 VehicleStandStillSts 1;
BA_ "Event trans." SG_ 1048 ASRActive 0;
BA_ "GenSigSendType" SG_ 1048 ASRActive 3;
BA_ "Event trans." SG_ 1048 MSRActive 0;
BA_ "GenSigSendType" SG_ 1048 MSRActive 3;
BA_ "Event trans." SG_ 1199 ABSFailSts 0;
BA_ "GenSigSendType" SG_ 1199 ABSFailSts 4;
BA_ "Event trans." SG_ 1199 ACCEngaged 0;
BA_ "GenSigSendType" SG_ 1199 ACCEngaged 4;
BA_ "Event trans." SG_ 1199 BSM_BLC_Active 0;
BA_ "GenSigSendType" SG_ 1199 BSM_BLC_Active 4;
BA_ "Event trans." SG_ 1199 BSMSysSts 0;
BA_ "GenSigSendType" SG_ 1199 BSMSysSts 4;
BA_ "Event trans." SG_ 1199 CMMIntervention 0;
BA_ "GenSigSendType" SG_ 1199 CMMIntervention 4;
BA_ "Event trans." SG_ 1199 DSTFailSts 0;
BA_ "GenSigSendType" SG_ 1199 DSTFailSts 4;
BA_ "Event trans." SG_ 1199 EBDFailSts 0;
BA_ "GenSigSendType" SG_ 1199 EBDFailSts 4;
BA_ "Event trans." SG_ 1199 ERMActive 0;
BA_ "GenSigSendType" SG_ 1199 ERMActive 4;
BA_ "Event trans." SG_ 1199 ESCFailSts 0;
BA_ "GenSigSendType" SG_ 1199 ESCFailSts 4;
BA_ "Event trans." SG_ 1199 ESCIntervention 0;
BA_ "GenSigSendType" SG_ 1199 ESCIntervention 4;
BA_ "Event trans." SG_ 1199 Function2Sts 0;
BA_ "GenSigSendType" SG_ 1199 Function2Sts 4;
BA_ "Event trans." SG_ 1199 FunctionFailSts 0;
BA_ "GenSigSendType" SG_ 1199 FunctionFailSts 4;
BA_ "Event trans." SG_ 1199 FunctionIntervention 0;
BA_ "GenSigSendType" SG_ 1199 FunctionIntervention 4;
BA_ "Event trans." SG_ 1199 FunctionSts 0;
BA_ "GenSigSendType" SG_ 1199 FunctionSts 4;
BA_ "Event trans." SG_ 1199 HillHolderFailSts 0;
BA_ "GenSigSendType" SG_ 1199 HillHolderFailSts 4;
BA_ "Event trans." SG_ 1199 RollsModeAct 0;
BA_ "GenSigSendType" SG_ 1199 RollsModeAct 4;
BA_ "Event trans." SG_ 1199 TSCActive 0;
BA_ "GenSigSendType" SG_ 1199 TSCActive 4;
BA_ "Accuracy" SG_ 1453 DsblFuelShutOff_ACC_BSM "-";
BA_ "Event trans." SG_ 1453 DsblFuelShutOff_ACC_BSM 0;
BA_ "GenSigSendType" SG_ 1453 DsblFuelShutOff_ACC_BSM 3;
BA_ "Accuracy" SG_ 254 CRC_BYD "1";
BA_ "Accuracy" SG_ 254 InternalError_BSM "-";
BA_ "Accuracy" SG_ 254 LatAcceleration_BSM "0,02";
BA_ "Accuracy" SG_ 254 LatAccelerationFailSts_BSM "-";
BA_ "Accuracy" SG_ 254 LongAcceleration_BSM "0,02";
BA_ "Accuracy" SG_ 254 LongAccelerationFailSts_BSM "-";
BA_ "Accuracy" SG_ 254 MessageCounter_BYD "1";
BA_ "Accuracy" SG_ 254 YawRate_BSM "0,08";
BA_ "Accuracy" SG_ 254 YawRateFailSts_BSM "-";
BA_ "Event trans." SG_ 1451 TorqueOverlayIntActivation_SPM 0;
BA_ "GenSigSendType" SG_ 1451 TorqueOverlayIntActivation_SPM 3;
BA_ "Accuracy" SG_ 288 CutAdvice "-";
BA_ "Accuracy" SG_ 288 MessageCounter_EC "-";
BA_ "Event trans." SG_ 2651930624 Digit_01 0;
BA_ "GenSigSendType" SG_ 2651930624 Digit_01 1;
BA_ "Accuracy" SG_ 2651930681 Digit_01_DASM "-";
BA_ "Event trans." SG_ 2651930681 Digit_01_DASM 0;
BA_ "GenSigSendType" SG_ 2651930681 Digit_01_DASM 1;
BA_ "Accuracy" SG_ 2651930681 Digit_02_DASM "-";
BA_ "Accuracy" SG_ 2651930681 Digit_03_DASM "-";
BA_ "Accuracy" SG_ 2651930681 Digit_04_DASM "-";
BA_ "Accuracy" SG_ 2651930681 Digit_05_DASM "-";
BA_ "Accuracy" SG_ 2651930681 Digit_06_DASM "-";
BA_ "Accuracy" SG_ 2651930681 Digit_07_DASM "-";
BA_ "Accuracy" SG_ 2651930681 Digit_08_DASM "-";
BA_ "Accuracy" SG_ 2651930681 Digit_09_DASM "-";
BA_ "Accuracy" SG_ 2651930681 Digit_10_DASM "-";
BA_ "Accuracy" SG_ 2651930681 Digit_11_DASM "-";
BA_ "Accuracy" SG_ 2651930691 Digit_01_DTCM "-";
BA_ "Event trans." SG_ 2651930691 Digit_01_DTCM 0;
BA_ "GenSigSendType" SG_ 2651930691 Digit_01_DTCM 1;
BA_ "Accuracy" SG_ 2651930691 Digit_02_DTCM "-";
BA_ "Accuracy" SG_ 2651930691 Digit_03_DTCM "-";
BA_ "Accuracy" SG_ 2651930691 Digit_04_DTCM "-";
BA_ "Accuracy" SG_ 2651930691 Digit_05_DTCM "-";
BA_ "Accuracy" SG_ 2651930691 Digit_06_DTCM "-";
BA_ "Accuracy" SG_ 2651930691 Digit_07_DTCM "-";
BA_ "Accuracy" SG_ 2651930691 Digit_08_DTCM "-";
BA_ "Accuracy" SG_ 2651930691 Digit_09_DTCM "-";
BA_ "Accuracy" SG_ 2651930691 Digit_10_DTCM "-";
BA_ "Accuracy" SG_ 2651930691 Digit_11_DTCM "-";
BA_ "Accuracy" SG_ 2651930625 Digit_01_ECM "-";
BA_ "Event trans." SG_ 2651930625 Digit_01_ECM 0;
BA_ "GenSigSendType" SG_ 2651930625 Digit_01_ECM 1;
BA_ "Accuracy" SG_ 2651930625 Digit_02_ECM "-";
BA_ "Accuracy" SG_ 2651930625 Digit_03_ECM "-";
BA_ "Accuracy" SG_ 2651930625 Digit_04_ECM "-";
BA_ "Accuracy" SG_ 2651930625 Digit_05_ECM "-";
BA_ "Accuracy" SG_ 2651930625 Digit_06_ECM "-";
BA_ "Accuracy" SG_ 2651930625 Digit_07_ECM "-";
BA_ "Accuracy" SG_ 2651930625 Digit_08_ECM "-";
BA_ "Accuracy" SG_ 2651930625 Digit_09_ECM "-";
BA_ "Accuracy" SG_ 2651930625 Digit_10_ECM "-";
BA_ "Accuracy" SG_ 2651930625 Digit_11_ECM "-";
BA_ "Accuracy" SG_ 2651930731 Digit_01_ECM2 "-";
BA_ "Event trans." SG_ 2651930731 Digit_01_ECM2 0;
BA_ "GenSigSendType" SG_ 2651930731 Digit_01_ECM2 1;
BA_ "Accuracy" SG_ 2651930731 Digit_02_ECM2 "-";
BA_ "Accuracy" SG_ 2651930731 Digit_03_ECM2 "-";
BA_ "Accuracy" SG_ 2651930731 Digit_04_ECM2 "-";
BA_ "Accuracy" SG_ 2651930731 Digit_05_ECM2 "-";
BA_ "Accuracy" SG_ 2651930731 Digit_06_ECM2 "-";
BA_ "Accuracy" SG_ 2651930731 Digit_07_ECM2 "-";
BA_ "Accuracy" SG_ 2651930731 Digit_08_ECM2 "-";
BA_ "Accuracy" SG_ 2651930731 Digit_09_ECM2 "-";
BA_ "Accuracy" SG_ 2651930731 Digit_10_ECM2 "-";
BA_ "Accuracy" SG_ 2651930731 Digit_11_ECM2 "-";
BA_ "Accuracy" SG_ 2651930627 Digit_01_IPC "-";
BA_ "Event trans." SG_ 2651930627 Digit_01_IPC 0;
BA_ "GenSigSendType" SG_ 2651930627 Digit_01_IPC 1;
BA_ "Accuracy" SG_ 2651930627 Digit_02_IPC "-";
BA_ "Accuracy" SG_ 2651930627 Digit_03_IPC "-";
BA_ "Accuracy" SG_ 2651930627 Digit_04_IPC "-";
BA_ "Accuracy" SG_ 2651930627 Digit_05_IPC "-";
BA_ "Accuracy" SG_ 2651930627 Digit_06_IPC "-";
BA_ "Accuracy" SG_ 2651930627 Digit_07_IPC "-";
BA_ "Accuracy" SG_ 2651930627 Digit_08_IPC "-";
BA_ "Accuracy" SG_ 2651930627 Digit_09_IPC "-";
BA_ "Accuracy" SG_ 2651930627 Digit_10_IPC "-";
BA_ "Accuracy" SG_ 2651930627 Digit_11_IPC "-";
BA_ "Accuracy" SG_ 2651930689 Digit_01_RFHM "-";
BA_ "Event trans." SG_ 2651930689 Digit_01_RFHM 0;
BA_ "GenSigSendType" SG_ 2651930689 Digit_01_RFHM 1;
BA_ "Accuracy" SG_ 2651930689 Digit_02_RFHM "-";
BA_ "Accuracy" SG_ 2651930689 Digit_03_RFHM "-";
BA_ "Accuracy" SG_ 2651930689 Digit_04_RFHM "-";
BA_ "Accuracy" SG_ 2651930689 Digit_05_RFHM "-";
BA_ "Accuracy" SG_ 2651930689 Digit_06_RFHM "-";
BA_ "Accuracy" SG_ 2651930689 Digit_07_RFHM "-";
BA_ "Accuracy" SG_ 2651930689 Digit_08_RFHM "-";
BA_ "Accuracy" SG_ 2651930689 Digit_09_RFHM "-";
BA_ "Accuracy" SG_ 2651930689 Digit_10_RFHM "-";
BA_ "Accuracy" SG_ 2651930689 Digit_11_RFHM "-";
BA_ "Accuracy" SG_ 2651930646 Digit_01_Shifter "-";
BA_ "Event trans." SG_ 2651930646 Digit_01_Shifter 0;
BA_ "GenSigSendType" SG_ 2651930646 Digit_01_Shifter 1;
BA_ "Accuracy" SG_ 2651930646 Digit_02_Shifter "-";
BA_ "Accuracy" SG_ 2651930646 Digit_03_Shifter "-";
BA_ "Accuracy" SG_ 2651930646 Digit_04_Shifter "-";
BA_ "Accuracy" SG_ 2651930646 Digit_05_Shifter "-";
BA_ "Accuracy" SG_ 2651930646 Digit_06_Shifter "-";
BA_ "Accuracy" SG_ 2651930646 Digit_07_Shifter "-";
BA_ "Accuracy" SG_ 2651930646 Digit_08_Shifter "-";
BA_ "Accuracy" SG_ 2651930646 Digit_09_Shifter "-";
BA_ "Accuracy" SG_ 2651930646 Digit_10_Shifter "-";
BA_ "Accuracy" SG_ 2651930646 Digit_11_Shifter "-";
BA_ "Accuracy" SG_ 2651930635 Digit_01_TRANSMISSION "-";
BA_ "Event trans." SG_ 2651930635 Digit_01_TRANSMISSION 0;
BA_ "GenSigSendType" SG_ 2651930635 Digit_01_TRANSMISSION 1;
BA_ "Accuracy" SG_ 2651930635 Digit_02_TRANSMISSION "-";
BA_ "Accuracy" SG_ 2651930635 Digit_03_TRANSMISSION "-";
BA_ "Accuracy" SG_ 2651930635 Digit_04_TRANSMISSION "-";
BA_ "Accuracy" SG_ 2651930635 Digit_05_TRANSMISSION "-";
BA_ "Accuracy" SG_ 2651930635 Digit_06_TRANSMISSION "-";
BA_ "Accuracy" SG_ 2651930635 Digit_07_TRANSMISSION "-";
BA_ "Accuracy" SG_ 2651930635 Digit_08_TRANSMISSION "-";
BA_ "Accuracy" SG_ 2651930635 Digit_09_TRANSMISSION "-";
BA_ "Accuracy" SG_ 2651930635 Digit_10_TRANSMISSION "-";
BA_ "Accuracy" SG_ 2651930635 Digit_11_TRANSMISSION "-";
BA_ "GenSigStartValue" SG_ 598 FSFCWPlusActivationMode 1;
BA_ "GenSigStartValue" SG_ 598 FSFCWPlusSetting 3;
BA_ "Event trans." SG_ 598 PowerModeSts_IPC 0;
BA_ "GenSigSendType" SG_ 598 PowerModeSts_IPC 3;
BA_ "Event trans." SG_ 598 PsngrBagRequestSts 0;
BA_ "GenSigSendType" SG_ 598 PsngrBagRequestSts 3;
BA_ "GenSigStartValue" SG_ 598 RemoteDoorUnlock 1;
BA_ "Event trans." SG_ 598 SpeedLimitActivationIPC 0;
BA_ "GenSigSendType" SG_ 598 SpeedLimitActivationIPC 3;
BA_ "Event trans." SG_ 598 VehicleSpeedSetIPC 0;
BA_ "GenSigStartValue" SG_ 598 VehicleSpeedSetIPC 511;
BA_ "GenSigSendType" SG_ 598 VehicleSpeedSetIPC 3;
BA_ "Accuracy" SG_ 348 ACC_Engine_Torque "-";
BA_ "Accuracy" SG_ 348 ACC_Engine_Torque_Enabled "-";
BA_ "Event trans." SG_ 348 ACC_Engine_Torque_Enabled 0;
BA_ "GenSigSendType" SG_ 348 ACC_Engine_Torque_Enabled 5;
BA_ "Accuracy" SG_ 348 BASensThresholdReq "-";
BA_ "Event trans." SG_ 348 BASensThresholdReq 0;
BA_ "GenSigSendType" SG_ 348 BASensThresholdReq 4;
BA_ "Accuracy" SG_ 348 Brake_Jerk_Req "-";
BA_ "Event trans." SG_ 348 Brake_Jerk_Req 0;
BA_ "GenSigSendType" SG_ 348 Brake_Jerk_Req 4;
BA_ "Accuracy" SG_ 348 DsblFuelShutOff_ACC "-";
BA_ "Event trans." SG_ 348 DsblFuelShutOff_ACC 0;
BA_ "GenSigSendType" SG_ 348 DsblFuelShutOff_ACC 4;
BA_ "Accuracy" SG_ 348 HIS_Req "-";
BA_ "Event trans." SG_ 348 HIS_Req 0;
BA_ "GenSigSendType" SG_ 348 HIS_Req 4;
BA_ "Accuracy" SG_ 348 Intervention "-";
BA_ "GenSigStartValue" SG_ 348 Intervention 2047;
BA_ "Accuracy" SG_ 348 InterventionCounter "-";
BA_ "Accuracy" SG_ 348 InterventionReq "-";
BA_ "Event trans." SG_ 348 InterventionReq 0;
BA_ "GenSigSendType" SG_ 348 InterventionReq 5;
BA_ "Accuracy" SG_ 348 InterventionType "-";
BA_ "Accuracy" SG_ 348 Prefill_Req "-";
BA_ "Event trans." SG_ 348 Prefill_Req 0;
BA_ "GenSigSendType" SG_ 348 Prefill_Req 4;
BA_ "Accuracy" SG_ 2564448497 N_PDU "-";
BA_ "Accuracy" SG_ 2564485472 N_PDU "-";
BA_ "GenSigStartValue" SG_ 507 TC_FaultStat 15;
BA_ "GenSigStartValue" SG_ 507 TC_TrqCltAct 2047;
BA_ "GenSigStartValue" SG_ 752 IBS_SOC_ECM 127;
BA_ "GenSigStartValue" SG_ 1846 RawPVS1 255;
BA_ "GenSigStartValue" SG_ 1846 RawPVS2 255;
BA_ "GenSigStartValue" SG_ 1846 RawTPS1 255;
BA_ "GenSigStartValue" SG_ 1846 RawTPS2 255;
BA_ "GenSigStartValue" SG_ 252 AlternatorFail 1;
BA_ "GenSigStartValue" SG_ 252 EngineStopStartSts 1;
BA_ "GenSigStartValue" SG_ 252 EngineSts 3;
BA_ "Accuracy" SG_ 1445 AfterRunCoolantPumpFailSts "-";
BA_ "Event trans." SG_ 1445 AfterRunCoolantPumpFailSts 0;
BA_ "GenSigSendType" SG_ 1445 AfterRunCoolantPumpFailSts 3;
BA_ "Accuracy" SG_ 1445 CC_SetSpdDspl_KPH "-";
BA_ "Event trans." SG_ 1445 CC_SetSpdDspl_KPH 0;
BA_ "GenSigSendType" SG_ 1445 CC_SetSpdDspl_KPH 3;
BA_ "Accuracy" SG_ 1445 CruiseControlLampSts "-";
BA_ "Event trans." SG_ 1445 CruiseControlLampSts 0;
BA_ "GenSigSendType" SG_ 1445 CruiseControlLampSts 3;
BA_ "Accuracy" SG_ 1445 CruiseControlSts "-";
BA_ "Event trans." SG_ 1445 CruiseControlSts 0;
BA_ "GenSigSendType" SG_ 1445 CruiseControlSts 3;
BA_ "Accuracy" SG_ 1445 HMIDisplay_CC "-";
BA_ "Event trans." SG_ 1445 HMIDisplay_CC 0;
BA_ "GenSigStartValue" SG_ 1445 HMIDisplay_CC 4;
BA_ "GenSigSendType" SG_ 1445 HMIDisplay_CC 3;
BA_ "Accuracy" SG_ 1445 Override "-";
BA_ "Event trans." SG_ 1445 Override 0;
BA_ "GenSigSendType" SG_ 1445 Override 3;
BA_ "Accuracy" SG_ 1445 SpeedLimitSts "-";
BA_ "Event trans." SG_ 1445 SpeedLimitSts 0;
BA_ "GenSigStartValue" SG_ 1445 SpeedLimitSts 2;
BA_ "GenSigSendType" SG_ 1445 SpeedLimitSts 3;
BA_ "Accuracy" SG_ 1202 EngineOilLevel "-";
BA_ "Accuracy" SG_ 1202 EngineOilMin "-";
BA_ "Event trans." SG_ 1202 EngineOilMin 0;
BA_ "GenSigSendType" SG_ 1202 EngineOilMin 3;
BA_ "Accuracy" SG_ 1202 EngineOilOverfill "-";
BA_ "Event trans." SG_ 1202 EngineOilOverfill 0;
BA_ "GenSigSendType" SG_ 1202 EngineOilOverfill 3;
BA_ "Accuracy" SG_ 1202 EngineOilPressure "-";
BA_ "Accuracy" SG_ 1202 EngineOilTemp_WarningLight "-";
BA_ "Event trans." SG_ 1202 EngineOilTemp_WarningLight 0;
BA_ "GenSigSendType" SG_ 1202 EngineOilTemp_WarningLight 3;
BA_ "Accuracy" SG_ 1202 EngineOilTemperature "-";
BA_ "Accuracy" SG_ 1202 EngineWaterLevel "-";
BA_ "Event trans." SG_ 1202 EngineWaterLevel 0;
BA_ "GenSigSendType" SG_ 1202 EngineWaterLevel 3;
BA_ "Accuracy" SG_ 1202 PowerModeSts_ECM "-";
BA_ "Event trans." SG_ 1202 PowerModeSts_ECM 0;
BA_ "GenSigSendType" SG_ 1202 PowerModeSts_ECM 3;
BA_ "GenSigStartValue" SG_ 1051 ACPressure 511;
BA_ "Accuracy" SG_ 1051 ThrottlePosition "+/- 0,392";
BA_ "GenSigStartValue" SG_ 251 EngineTorque 2047;
BA_ "Accuracy" SG_ 496 ActualPedalPos "-";
BA_ "GenSigStartValue" SG_ 496 ActualPedalPos 1;
BA_ "Accuracy" SG_ 496 Analog_Clutch "-";
BA_ "Accuracy" SG_ 496 Clutch_Upstop "-";
BA_ "Accuracy" SG_ 496 ClutchInterLk "-";
BA_ "GenSigStartValue" SG_ 751 SAMInfo 15;
BA_ "Accuracy" SG_ 550 DrivelineSts "-";
BA_ "Event trans." SG_ 550 DrivelineSts 0;
BA_ "GenSigSendType" SG_ 550 DrivelineSts 3;
BA_ "Accuracy" SG_ 550 SpStChmRq "-";
BA_ "Event trans." SG_ 550 SpStChmRq 0;
BA_ "GenSigSendType" SG_ 550 SpStChmRq 3;
BA_ "Accuracy" SG_ 550 SpStDispstat "-";
BA_ "Event trans." SG_ 550 SpStDispstat 0;
BA_ "GenSigSendType" SG_ 550 SpStDispstat 3;
BA_ "Accuracy" SG_ 550 SpStIndRq "-";
BA_ "Event trans." SG_ 550 SpStIndRq 0;
BA_ "GenSigSendType" SG_ 550 SpStIndRq 3;
BA_ "Accuracy" SG_ 550 SpStSwStat "-";
BA_ "Event trans." SG_ 550 SpStSwStat 0;
BA_ "GenSigSendType" SG_ 550 SpStSwStat 3;
BA_ "Event trans." SG_ 550 SpStWarnStat 0;
BA_ "GenSigSendType" SG_ 550 SpStWarnStat 3;
BA_ "Accuracy" SG_ 1854 HighBeamSts "-";
BA_ "Event trans." SG_ 1854 HighBeamSts 0;
BA_ "GenSigSendType" SG_ 1854 HighBeamSts 3;
BA_ "Accuracy" SG_ 1854 LHParkingLightSts "-";
BA_ "Event trans." SG_ 1854 LHParkingLightSts 0;
BA_ "GenSigSendType" SG_ 1854 LHParkingLightSts 3;
BA_ "Accuracy" SG_ 1854 LHTurnLightFault "-";
BA_ "Accuracy" SG_ 1854 LHTurnSignalSts "-";
BA_ "Event trans." SG_ 1854 LHTurnSignalSts 0;
BA_ "GenSigSendType" SG_ 1854 LHTurnSignalSts 3;
BA_ "Accuracy" SG_ 1854 ParkingLightFault "-";
BA_ "Accuracy" SG_ 1854 RHParkingLightSts "-";
BA_ "Event trans." SG_ 1854 RHParkingLightSts 0;
BA_ "GenSigSendType" SG_ 1854 RHParkingLightSts 3;
BA_ "Accuracy" SG_ 1854 RHTurnLightFault "-";
BA_ "Accuracy" SG_ 1854 RHTurnSignalSts "-";
BA_ "Event trans." SG_ 1854 RHTurnSignalSts 0;
BA_ "GenSigSendType" SG_ 1854 RHTurnSignalSts 3;
BA_ "Accuracy" SG_ 1854 StopLightFault "-";
BA_ "Accuracy" SG_ 1854 StopLightSts "-";
BA_ "Event trans." SG_ 1854 StopLightSts 0;
BA_ "GenSigSendType" SG_ 1854 StopLightSts 3;
BA_ "Accuracy" SG_ 222 ElectricSteeringFailSts "-";
BA_ "Accuracy" SG_ 222 LwsAngle "+/- 2.8°";
BA_ "Accuracy" SG_ 222 LwsCalibration "-";
BA_ "Accuracy" SG_ 222 LWSFailSts "-";
BA_ "Accuracy" SG_ 222 LwsSpeed "15 °/s";
BA_ "Accuracy" SG_ 100 ControlEncodingReq "-";
BA_ "Event trans." SG_ 100 ControlEncodingReq 0;
BA_ "GenSigSendType" SG_ 100 ControlEncodingReq 1;
BA_ "Accuracy" SG_ 100 f1_1 "-";
BA_ "Accuracy" SG_ 100 f1_2 "-";
BA_ "Accuracy" SG_ 100 rnd_1 "-";
BA_ "Accuracy" SG_ 100 rnd_2 "-";
BA_ "Accuracy" SG_ 100 rnd_3 "-";
BA_ "Accuracy" SG_ 100 rnd_4 "-";
BA_ "Accuracy" SG_ 104 ControlEncodingRsp "-";
BA_ "Event trans." SG_ 104 ControlEncodingRsp 0;
BA_ "GenSigSendType" SG_ 104 ControlEncodingRsp 1;
BA_ "Accuracy" SG_ 104 MKKey_3 "-";
BA_ "Accuracy" SG_ 104 MKKey_4 "-";
BA_ "Accuracy" SG_ 104 MKKey_5 "-";
BA_ "Accuracy" SG_ 104 MKKey_6 "-";
BA_ "Accuracy" SG_ 104 MKKey1org21 "-";
BA_ "Accuracy" SG_ 104 MKKey2org22 "-";
VAL_ 599 AirBagFailSts 0 "Fail_Not_Present_Lamp_Off" 1 "Fail_Not_Present_Lamp_Flashing" 2 "Fail_Present_Lamp_On" 3 "Not_Used";
VAL_ 599 PsngrBagChargeSts 0 "Active" 1 "Not_Active" 2 "Not_Present" 3 "SNA";
VAL_ 599 SBR1RowCentralSeatBuckleFailSts 0 "Fail_Not_Present" 1 "Fail_Present" 3 "SNA";
VAL_ 599 SBR1RowCentralSeatConfigSts 0 "Seat_Not_Checked" 1 "Seat_Checked";
VAL_ 599 SBR1RowCentralSeatPPDFailSts 0 "Fail_Not_Present" 1 "Fail_Present" 3 "SNA";
VAL_ 599 SBR1RowCentralSeatSts 0 "Seat_Belt_Fasten" 1 "Seat_Belt_Not_Fasten" 2 "Seat_Safe" 3 "Seat_Not_Safe" 7 "SNA";
VAL_ 599 SBR1RowDriverSeatConfigSts 0 "Seat_Not_Checked" 1 "Seat_Checked";
VAL_ 599 SBR1RowDriverSeatFailSts 0 "Fail_Not_Present" 1 "Fail_Present" 3 "SNA";
VAL_ 599 SBR1RowDriverSeatSts 0 "Seat_Belt_Fasten" 1 "Seat_Belt_Not_Fasten" 3 "SNA";
VAL_ 599 SBR1RowPsngrSeatBuckleFailSts 0 "Fail_Not_Present" 1 "Fail_Present" 3 "SNA";
VAL_ 599 SBR1RowPsngrSeatConfigSts 0 "Seat_Not_Checked" 1 "Seat_Checked";
VAL_ 599 SBR1RowPsngrSeatPPDFailSts 0 "Fail_Not_Present" 1 "Fail_Present" 3 "SNA";
VAL_ 599 SBR1RowPsngrSeatSts 0 "Seat_Belt_Fasten" 1 "Seat_Belt_Not_Fasten" 2 "Seat_Safe" 3 "Seat_Not_Safe" 7 "SNA";
VAL_ 599 SBR2RowCentralSeatConfigSts 0 "Seat_Not_Checked" 1 "Seat_Checked";
VAL_ 599 SBR2RowCentralSeatSts 0 "Seat_Belt_Fasten" 1 "Seat_Belt_Not_Fasten" 3 "SNA";
VAL_ 599 SBR2RowLeftSeatConfigSts 0 "Seat_Not_Checked" 1 "Seat_Checked";
VAL_ 599 SBR2RowLeftSeatSts 0 "Seat_Belt_Fasten" 1 "Seat_Belt_Not_Fasten" 3 "SNA";
VAL_ 599 SBR2RowRightSeatConfigSts 0 "Seat_Not_Checked" 1 "Seat_Checked";
VAL_ 599 SBR2RowRightSeatSts 0 "Seat_Belt_Fasten" 1 "Seat_Belt_Not_Fasten" 3 "SNA";
VAL_ 1447 DrvSbltUnFltr 0 "Seat belt fastened/Buckled" 1 "Seatbelt not fastened/Unbuckled" 2 "Seatbelt shorted low/LOW " 3 "Seatbelt shorted high/HIGH " 7 "Signal not available/SNA";
VAL_ 1050 BCMSAMFailSts 0 "Fail_not_present" 1 "Fail_present";
VAL_ 1050 IBSFailSts 0 "Fail_not_present" 1 "Fail_present";
VAL_ 247 TxpAuthRequest 0 "Transponder_Authentication_Request" 1 "Not_Active";
VAL_ 247 TxpReadRequest 0 "Transponder_Reading_Request" 1 "Not_Active";
VAL_ 250 BCMFpsCommand 0 "Do_Not_Actuate" 1 "Actuate";
VAL_ 250 BCMFpsConfirm 0 "Actuate" 1 "Do_Not_Actuate";
VAL_ 250 BCMFpsFailSts 0 "Fail_not_Present" 1 "Fail_Present";
VAL_ 250 BrakePedalSwitchNCFailSts 0 "Fail_Not_Present" 1 "Fail_Present";
VAL_ 250 BrakePedalSwitchNCSts 0 "Not_Active" 1 "Active";
VAL_ 250 BrakePedalSwitchNOFailSts 0 "Fail_Not_Present" 1 "Fail_Present";
VAL_ 250 BrakePedalSwitchNOSts 0 "Not_Active" 1 "Active";
VAL_ 250 EngineOffRequest 0 "Not_Active" 1 "Active";
VAL_ 250 KeyInIgnSts 0 "KEY_DEF" 1 "KEY_NOT_IN_IGN" 2 "KEY_IN_IGN" 3 "SNA";
VAL_ 250 OperationalModeSts 0 "Initialization" 1 "Ignition_Off_WithoutKey" 2 "Ignition_Off" 3 "Ignition_Acc" 4 "Ignition_On" 5 "Ignition_Pre_Start" 6 "Ignition_Start" 7 "Ignition_Cranking" 8 "Ignition_On_EngOn" 9 "Ignition_Pre_Acc" 10 "Ignition_Pre_Off" 11 "Automatic_Cranking" 12 "Automatic_Stop" 13 "Key_Authenticated" 14 "Not_Used" 15 "SNA";
VAL_ 250 StartRelayBCMFault 0 "Not_Present" 1 "Present";
VAL_ 250 StartRelayBCMSts 0 "OFF" 1 "ON";
VAL_ 250 TurnIndicatorSts 0 "Center" 1 "Right" 2 "Left" 3 "SNA";
VAL_ 245 MinicryptReceptionSts 0 "Not_Received" 1 "Received";
VAL_ 1446 A2D_DRV_TEMP_DR_POS 1023 "SNA";
VAL_ 1446 A2D_FT_HVAC_BLOWER_VOLTAGE 1023 "SNA";
VAL_ 1446 AcOutputCurrentSts 255 "SNA";
VAL_ 1446 StopStartClimateInfo 0 "SPST_ON" 1 "CABIN_HI" 2 "CABIN_LO" 3 "MAX_AC" 4 "FT_DEFROST" 5 "EBL" 7 "SNA";
VAL_ 748 FrontWiperMoveSts 0 "Stop" 1 "Moving";
VAL_ 748 RemStartActiveEPB 0 "No_request" 1 "Request";
VAL_ 900 CmdIgn_FailSts 0 "Fail_Not_Present" 1 "Fail_Present" 3 "SNA";
VAL_ 900 CmdIgnSts 0 "Initialization" 1 "IGN_LK" 3 "ACC" 4 "RUN" 5 "START" 7 "SNA";
VAL_ 900 DriveStyleSts 0 "Normal" 1 "City" 2 "Sport_Fun" 3 "Winter_Race" 4 "Eco" 5 "TracPlus" 6 "Trekking" 7 "Auto" 8 "Snow" 9 "Sand" 10 "Mud" 11 "Rock" 12 "Race" 31 "SNA";
VAL_ 900 ExternalTemperature 511 "SNA";
VAL_ 900 ExternalTemperatureFailSts 0 "Fail_not_present" 1 "Fail_present";
VAL_ 900 Int_Relay_FailSts 0 "Fail_Not_Present" 1 "Fail_Present" 3 "SNA";
VAL_ 900 LowBeamSts 0 "OFF" 1 "ON";
VAL_ 900 ParkBrakeSts 0 "OFF" 1 "ON";
VAL_ 900 PowerModeSts 0 "Standard_Power" 1 "Logistic_Mode_ON" 2 "Logistic_Mode_PR" 3 "LogisticModeON_and_EngineON";
VAL_ 900 SuspensionLevel 0 "Level_0" 1 "Level_1" 2 "Level_2" 3 "SNA";
VAL_ 1349 ChkFuelLevelSts 0 "Fault_Not_Present" 1 "Chk_Code_1" 2 "Chk_Code_2" 3 "Chk_Code_3" 4 "Chk_Code_4" 5 "Not_Used" 6 "Not_Used" 7 "Not_Used";
VAL_ 1349 ExternalTemperatureAD_Voltage 255 "SNA";
VAL_ 1349 FpsNotAvailable 0 "FPS_Available" 1 "FPS_Not_Available";
VAL_ 1349 FrontWiperReq 0 "OFF" 1 "INT" 2 "LOW" 3 "HIGH";
VAL_ 1349 FuelLevel 255 "SNA";
VAL_ 1349 FuelLevelFailSts 0 "Fail_Not_Present" 1 "Fail_Present";
VAL_ 1349 InternalLightLevel 0 "Level_1" 1 "Level_2" 2 "Level_3" 3 "Level_4" 4 "Level_5" 5 "Level_6" 6 "Level_7" 7 "Level_8" 8 "Level_9" 9 "Level_10" 10 "Level_11" 11 "Level_12" 12 "Level_13" 13 "Level_14" 14 "Level_15" 15 "Level_16";
VAL_ 1349 InternalLightSts 0 "Not_Active" 1 "Active";
VAL_ 1349 NotFilteredFuelLevel 255 "SNA";
VAL_ 1349 PTCFailSts 0 "Fail_Not_Present" 1 "Fail_Present";
VAL_ 1349 PTCSts 0 "zero_per_cent" 1 "thirtythree_per_cent" 2 "sixtysix_per_cent" 3 "onehundred_per_cent";
VAL_ 1201 BonnetSts 0 "Closed" 1 "Open";
VAL_ 1201 CompressorACReqSts 0 "Not_Active" 1 "Active";
VAL_ 1201 DriverDoorFailSts 0 "Fail_Not_Present" 1 "Fail_Present";
VAL_ 1201 DriverDoorSts 0 "Closed" 1 "Open";
VAL_ 1201 ExteriorRearReleaseSwitchSts 0 "Not_Pressed" 1 "Pressed";
VAL_ 1201 FHeatedWindowSts 0 "OFF" 1 "ON";
VAL_ 1201 FOBSearchRequest 0 "NO_ACTION" 1 "REQUEST_SEARCH" 2 "RESULT_RECEIVED" 3 "RESERVED";
VAL_ 1201 LHRDoorSts 0 "Closed" 1 "Open";
VAL_ 1201 PsngrDoorSts 0 "Closed" 1 "Open";
VAL_ 1201 Recalibration 0 "False" 1 "True";
VAL_ 1201 RemSt_InhibitSts 0 "INHIBIT_DEFAUILT" 1 "TIME_OUT_RUN" 2 "TIME_OUT_CUST_MODE" 3 "KEY_IN_RUN" 4 "DRV_DOOR_AJAR" 5 "PASS_DOOR_AJAR" 6 "LR_DOOR_AJAR" 7 "RR_DOOR_AJAR" 8 "START_COUNTER" 9 "FAIL_COUNTER" 10 "LOW_RPM_SHUTDOWN" 11 "KEY_IN_IGN" 12 "BRAKE_PRESSED" 13 "HAZARD_LAMP_ON" 14 "NOT_IN_PARK" 15 "VEH_SPEED_HIGH" 16 "HOOD_AJAR" 17 "TRUNK_LIFTGATE" 18 "VTA_ALARM" 19 "PANIC_MODE" 20 "BATT_VOLT_HIGH" 21 "BATT_VOLT_LOW" 22 "POWER_LOSS" 23 "MIL_ON" 24 "OIL_PRESSURE_LOW" 25 "COOLANT_TEMP_HIGH" 26 "RPM_HIGH" 27 "CRANK_NO_START" 28 "REMOTE_OFF_RQ" 29 "RS_DISABLED_PREV" 30 "NOT_CONFIGURED" 31 "NO_HOOD_SWITCH" 32 "NO_AUTO_TRANS" 33 "NOT_ENABLED" 34 "INVALID_SKIM_KEY" 35 "IGN_SNA" 36 "IGN_NOT_LOCK" 37 "GLOW_PLUG_TIMEOUT" 38 "LOW_FUEL" 39 "ETC_LAMP_ON" 40 "LOGISTIC_MODE" 41 "COLD_START_LAMP_FLASH" 62 "EPB_NO_RESP" 63 "SNA";
VAL_ 1201 RemStActvSts 0 "Remote Start Not Active" 1 "Remote Start Active";
VAL_ 1201 RHatchSts 0 "Closed" 1 "Open";
VAL_ 1201 RHeatedWindowSts 0 "OFF" 1 "ON";
VAL_ 1201 RHRDoorSts 0 "Closed" 1 "Open";
VAL_ 1201 SpSt_Pad1 0 "Button Unpressed" 1 "Button Pressed" 2 "Short to Ground" 3 "Short to Power" 4 "Indeterminate" 7 "SNA";
VAL_ 1201 TheftAlarmStatus 0 "VTA_DISARM" 1 "VTA_PREARM" 2 "VTA_ARM" 3 "VTA_LGT" 4 "VTA_LGT_HORN" 5 "VTA_TAMP" 6 "VTA_ITM_Alarm" 7 "SNA";
VAL_ 1049 DriverDoor2AjarRawValSts 0 "Default" 1 "FL_SSA" 2 "FL_SSB" 3 "FL_SSC" 4 "FL_SSD" 5 "FL_SSE" 6 "OPEN_SSA" 7 "OPEN_SSB" 8 "CLOSED_SSA" 9 "CLOSED_SSB" 10 "FH_SSA" 11 "FH_SSB" 12 "FH_SSC" 13 "FH_SSD" 14 "FH_SSE" 15 "SNA";
VAL_ 1049 DriverDoor2AjarXtionSts 0 "No transition" 1 "Transition" 3 "SNA";
VAL_ 1049 DriverDoorAjarXtionSts 0 "No transition" 1 "Transition" 3 "SNA";
VAL_ 1049 FUEL_VOLT 255 "SNA";
VAL_ 1049 FUEL_VOLT2 255 "SNA";
VAL_ 1049 PsngrDoorAjarXtionSts 0 "No transition" 1 "Transition" 3 "SNA";
VAL_ 497 BrkBstrVac 255 "SNA";
VAL_ 257 ABSActive 0 "Not_active" 1 "Active";
VAL_ 257 BrakeInterventionSts 0 "No_active_brake_intervention" 1 "Active_brake_intervention";
VAL_ 257 BSMShiftInterference 0 "Shift_allowed" 1 "Shift_not_allowed" 3 "SNA";
VAL_ 257 CMMInterventionAck 0 "Idle" 1 "Accepted" 2 "Rejected" 3 "Not_Used";
VAL_ 257 ESCActive 0 "Not_active" 1 "Active";
VAL_ 257 Ft_RrAxleCoupling_TrqRq 255 "SNA";
VAL_ 257 Ft_RrTrqCoupling_ModeRq 0 "No_intervention" 1 "Limit_minimum" 2 "Limit_maximum" 3 "Command";
VAL_ 257 MasterCylinderPressure 1023 "SNA";
VAL_ 257 PrefillActive 0 "Not_Active" 1 "Active";
VAL_ 257 VehicleSpeedVSOSig 8191 "SNA";
VAL_ 257 VehicleSpeedVSOSigFailSts 0 "Fail_not_present" 1 "Fail_present";
VAL_ 263 BrakeFluidLevelSts_BSM 0 "OK" 1 "Low_Level";
VAL_ 263 BrakePedalSwitchNCFailSts 0 "Fail_Not_Present" 1 "Fail_Present";
VAL_ 263 BrakePedalSwitchNCSts 0 "Not_Active" 1 "Active";
VAL_ 263 BrakePedalSwitchNOFailSts 0 "Fail_Not_Present" 1 "Fail_Present";
VAL_ 263 BrakePedalSwitchNOSts 0 "Not_Active" 1 "Active";
VAL_ 263 BrakeTravelFailSts 0 "Fail_Not_Present" 1 "Fail_Present";
VAL_ 263 DiskWearLamp 0 "Not_Active" 1 "Active";
VAL_ 263 EPB_Pad_Wear 0 "No_Pad_Wear_Warning" 1 "Pad_Wear_Warning";
VAL_ 259 ACC_Engine_Torque_Enabled_BSM 0 "Not_Enabled" 1 "Enabled";
VAL_ 259 HillHolderActive 0 "Not_Active" 1 "Active";
VAL_ 259 MuSplit 0 "MuSplitOFF" 1 "MuSplitON" 3 "SNA";
VAL_ 259 OverSteering 63 "SNA";
VAL_ 259 TorqueIncrease 0 "Not_Active" 1 "Active";
VAL_ 259 TorqueReduct 0 "Not_Active" 1 "Active";
VAL_ 259 TorqueRequest 2047 "SNA";
VAL_ 259 TorqueRequest_FAST 2047 "SNA";
VAL_ 259 UnderSteering 63 "SNA";
VAL_ 501 AEB_InterventionType 0 "None" 1 "ACC" 2 "AEB_P_standard" 3 "AEB_P_extended" 4 "EBA" 5 "AEB_L" 7 "SNA";
VAL_ 501 ExternalBrkRequestsDisabled 0 "Enabled" 1 "Diasbled" 2 "Not_Used" 3 "SNA";
VAL_ 501 VehicleStandStillSts 0 "True" 1 "False" 3 "SNA";
VAL_ 498 Brk_Jrk_Resp 0 "Not_Executed" 1 "Executed";
VAL_ 498 Brk_Thermdl 0 "Normal_Temperature" 1 "High_Temperature";
VAL_ 1048 ASRActive 0 "Not_active" 1 "Active";
VAL_ 1048 ASRFailSts 0 "Fail_Not_Present" 1 "Fail_Present";
VAL_ 1048 MSRActive 0 "Not_Active" 1 "Active";
VAL_ 1048 TravelDistance 255 "SNA";
VAL_ 1199 ABSFailSts 0 "Fail_Not_Present" 1 "Fail_Present";
VAL_ 1199 ACCEngaged 0 "Not_Engaged" 1 "Engaged";
VAL_ 1199 BSM_BLC_Active 0 "Not_Active" 1 "Active";
VAL_ 1199 BSMSysSts 0 "Normal mode" 1 "Diagnosis mode" 2 "Alternative mode" 3 "SNA";
VAL_ 1199 CMMIntervention 0 "No_intervention" 1 "Intervention";
VAL_ 1199 DSTFailSts 0 "Fail_Not_Present" 1 "Fail_Present";
VAL_ 1199 EBDFailSts 0 "Fail_Not_Present" 1 "Fail_Present";
VAL_ 1199 ERMActive 0 "Not_Active" 1 "Active";
VAL_ 1199 ESCFailSts 0 "Fail_Not_Present" 1 "Fail_Present";
VAL_ 1199 ESCIntervention 0 "No_intervention" 1 "Intervention_blinking_lamp";
VAL_ 1199 Function2Sts 0 "Not_Active" 1 "Active";
VAL_ 1199 FunctionFailSts 0 "Fail_Not_Present" 1 "Fail_Present";
VAL_ 1199 FunctionIntervention 0 "No_intervention" 1 "Intervention_blinking_lamp";
VAL_ 1199 FunctionSts 0 "Not_Active" 1 "Active";
VAL_ 1199 HillHolderFailSts 0 "Fail_not_present" 1 "Fail_present";
VAL_ 1199 RollsModeAct 0 "Not_active" 1 "Active";
VAL_ 1199 TSCActive 0 "Not_Active" 1 "Active";
VAL_ 1453 DsblFuelShutOff_ACC_BSM 0 "Not_Active" 1 "Active";
VAL_ 284 Stabi_Index 8191 "SNA";
VAL_ 284 YawRateRef 4095 "SNA";
VAL_ 284 YawRateStat 4095 "SNA";
VAL_ 254 InternalError_BSM 0 "No_int_processing_error_detected" 1 "Int_processing_error_detected";
VAL_ 254 LatAcceleration_BSM 4095 "SNA";
VAL_ 254 LatAccelerationFailSts_BSM 0 "Fail_Not_Present" 1 "Fail_Present";
VAL_ 254 LongAcceleration_BSM 4095 "SNA";
VAL_ 254 LongAccelerationFailSts_BSM 0 "Fail_Not_Present" 1 "Fail_Present";
VAL_ 254 Slope 255 "SNA";
VAL_ 254 YawRate_BSM 4095 "SNA";
VAL_ 254 YawRateFailSts_BSM 0 "Fail_Not_Present" 1 "Fail_Present";
VAL_ 1451 TorqueOverlayIntActivation_SPM 0 "NotActive" 1 "Active";
VAL_ 288 CutAdvice 0 "Disable" 1 "Enable" 2 "Not Used" 3 "SNA";
VAL_ 601 ElectricSteeringLamp_FailSts 0 "OFF_Fail_not_present" 1 "OFF_Fail_present" 2 "ON_Fail_not_present" 3 "Not_used";
VAL_ 598 ABSLamp_FailSts 0 "OFF_Fail_not_present" 1 "OFF_Fail_present" 2 "ON_Fail_not_present" 3 "Not_used";
VAL_ 598 AirBagLamp_FailSts 0 "OFF_Fail_not_present" 1 "OFF_Fail_present" 2 "ON_Fail_not_present" 3 "BLINKING_Fail_not_present";
VAL_ 598 DistanceUnit 0 "km" 1 "miles";
VAL_ 598 EBDLamp_FailSts 0 "OFF_Fail_not_present" 1 "OFF_Fail_present" 2 "ON_Fail_not_present" 3 "Not_used";
VAL_ 598 EPBAutoAppReqSts 0 "Not_Request" 1 "AutoApply_Disable" 2 "AutoApply_Enable" 3 "Not_used";
VAL_ 598 EPBLamp_FailSts 0 "OFF_Fail_not_present" 1 "OFF_Fail_present" 2 "ON_Fail_not_present" 3 "Not_used";
VAL_ 598 EPBMaintenanceReqSts 0 "Not_Request" 1 "Maintenance_Disable" 2 "Maintenance_Enable" 3 "Not_used";
VAL_ 598 ESCLamp_FailSts 0 "OFF_Fail_not_present" 1 "OFF_Fail_present" 2 "ON_Fail_not_present" 3 "Not_used";
VAL_ 598 FSFCWPlusActivationMode 0 "Near" 1 "Med" 2 "Far";
VAL_ 598 FSFCWPlusSetting 0 "Off" 1 "Audio" 2 "Brake" 3 "Audio_Brake" 4 "Not_Request";
VAL_ 598 HHDisablingCommandSts 0 "Enabled" 1 "Disabled";
VAL_ 598 PassiveEntry 0 "On" 1 "Off";
VAL_ 598 PowerModeSts_IPC 0 "Standard_Power" 1 "Logistic_Mode_ON" 2 "Logistic_Mode_PR" 3 "Not_Used";
VAL_ 598 PsngrBagRequestSts 0 "Not_Request" 1 "Enable" 2 "Disable" 3 "Not_Used";
VAL_ 598 RemoteDoorUnlock 0 "Driver" 1 "All";
VAL_ 598 SpeedLimitActivationIPC 0 "Not_Active" 1 "Active";
VAL_ 598 VehicleSpeedSetIPC 511 "SNA";
VAL_ 348 ACC_Engine_Torque 2047 "SNA";
VAL_ 348 ACC_Engine_Torque_Enabled 0 "Not_Enabled" 1 "Enabled";
VAL_ 348 BASensThresholdReq 0 "T0" 1 "T1" 2 "T2" 3 "T3";
VAL_ 348 Brake_Jerk_Req 0 "Not_Active" 1 "Active";
VAL_ 348 DsblFuelShutOff_ACC 0 "Not_Active" 1 "Active";
VAL_ 348 HIS_Req 0 "Not_Active" 1 "Active";
VAL_ 348 Intervention 2047 "SNA";
VAL_ 348 InterventionReq 0 "Not_Active" 1 "Active";
VAL_ 348 InterventionType 0 "None" 1 "ACC" 2 "AEB_P_standard" 3 "AEB_P_extended" 4 "EBA" 5 "AEB_L" 7 "SNA";
VAL_ 348 Prefill_Req 0 "No_Prefill_Requested" 1 "Prefill_Requested";
VAL_ 507 TC_FaultStat 0 "Deactivated / DEACT" 1 "Initialization / INIT" 2 "calibration / CAL" 3 "normal operation / NORMAL" 4 "Temporary failed / T_FAIL" 5 "Failed / FAIL" 6 "Failed - clutch open / FAIL_CO" 7 "Failed - position unknown / FAIL_PU" 15 "Signal not available / SNA";
VAL_ 507 TC_TrqCltAct 2047 "SNA";
VAL_ 752 IBS_SOC_ECM 127 "SNA";
VAL_ 252 AlternatorFail 0 "Alternator_Fail" 1 "Alternator_Not_In_Fail";
VAL_ 252 BankDeactivationSts 0 "Full_Engine_Mode" 1 "Transit_Sts_Full_to_Half " 2 "Transit_Sts_Half_to_Full " 3 "Half_Engine_Mode";
VAL_ 252 CC_BrakeIntervention 1023 "SNA";
VAL_ 252 CC_BrakeIntervention_Req 0 "Not Active" 1 "Active";
VAL_ 252 EngineSpeed 16383 "SNA";
VAL_ 252 EngineSpeedFailSts 0 "Fail_not_present" 1 "Fail_present";
VAL_ 252 EngineStopStartSts 0 "Engine_Stop" 1 "Engine_Not_in_Stop" 2 "Engine_Stall" 3 "Engine_Stopping";
VAL_ 252 EngineSts 0 "Engine_Off" 1 "Engine_Cranking" 2 "Engine_On" 3 "SNA";
VAL_ 252 GasPedalPosition 255 "SNA";
VAL_ 252 GasPedalPositionFailSts 0 "Fail_not_present" 1 "Fail_present";
VAL_ 252 ReverseGearSts 0 "Not_Inserted" 1 "Inserted" 2 "Not_Used" 3 "SNA";
VAL_ 252 StopStartSts 0 "OFF" 1 "ON" 2 "Functional_Disable_Request" 3 "Safety_Disable_Request";
VAL_ 1445 AfterRunCoolantPumpFailSts 0 "Fault_Not_Present" 1 "Fault_Present";
VAL_ 1445 CC_SetSpdDspl_KPH 8191 "SNA";
VAL_ 1445 CruiseControlLampSts 0 "Not_inserted" 1 "Inserted";
VAL_ 1445 CruiseControlSts 0 "Not_inserted" 1 "Inserted";
VAL_ 1445 HMIDisplay_CC 0 "ResumeUnavailable_SL" 1 "IncreaeUnavailable_SL" 2 "SetUnavailable_SL" 3 "CC_Unavaulable_HDC" 4 "No_message";
VAL_ 1445 Override 0 "Not_active" 1 "Active";
VAL_ 1445 SpeedLimitSts 0 "Standby" 1 "Activated" 2 "Not_Actuable" 3 "Override" 4 "Overspeed" 5 "Deactivated" 6 "Off" 7 "SNA";
VAL_ 1202 EngineOilLevel 0 "Level1" 1 "Level2" 2 "Level3" 3 "Level4" 4 "Level5" 5 "Level6" 6 "Level7" 7 "Level8" 8 "Level9" 9 "Level10" 10 "Level11" 11 "Level12" 12 "Level13" 13 "Level14" 31 "SNA";
VAL_ 1202 EngineOilMin 0 "False" 1 "True";
VAL_ 1202 EngineOilOverfill 0 "False" 1 "True";
VAL_ 1202 EngineOilPressure 255 "SNA";
VAL_ 1202 EngineOilTemp_WarningLight 0 "Not_Active" 1 "Active";
VAL_ 1202 EngineWaterLevel 0 "Normal_Level" 1 "Low_Level";
VAL_ 1202 PowerModeSts_ECM 0 "Standard_Power" 1 "Logistic_Mode_ON" 2 "Logistic_Mode_PR" 3 "Not_Used";
VAL_ 1051 ACPressure 511 "SNA";
VAL_ 1051 ACPressureFailSts 0 "Fail_Not_Present" 1 "Fail_Present";
VAL_ 1051 Feedback_DTCM 0 "Valid" 1 "Not_Valid";
VAL_ 255 EngineTorqueDriverReq 2047 "SNA";
VAL_ 255 FpsActuated 0 "Not_Actuated" 1 "Actuated";
VAL_ 255 FpsNotActuable 0 "FPS_Actuable" 1 "FPS_Not_Actuable";
VAL_ 255 LV12PwrFreeRq 0 "Level 1 or 2 Power free Mode NOT active" 1 "Level 1 or 2 Power free Mode Active";
VAL_ 255 MaxEngineTorque 2047 "SNA";
VAL_ 255 MinEngineTorque 2047 "SNA";
VAL_ 251 CrankHold 0 "Not_Active" 1 "Active";
VAL_ 251 EngineFrictionTorque 511 "SNA";
VAL_ 251 EngineTorque 2047 "SNA";
VAL_ 251 FeedbackASR_ESCReq 0 "TorqueReq_ASR_ESCValid" 1 "TorqueReq_ASR_ESCNot_Valid";
VAL_ 251 GasPedalAct 0 "Not_active" 1 "Active";
VAL_ 251 GasPedalGradient 255 "SNA";
VAL_ 251 StartRelayBCMCmd 0 "Not_Action" 1 "Action";
VAL_ 496 ActualPedalPos 255 "SNA";
VAL_ 496 Analog_Clutch 255 "SNA";
VAL_ 496 Clutch_Upstop 0 "Partial_switch_not_active " 1 "Partial_switch_active";
VAL_ 496 ClutchInterLk 0 "Full_switch_not_active " 1 "Full_switch_active";
VAL_ 749 EngineWaterTemp 255 "SNA";
VAL_ 749 EngineWaterTempFailSts 0 "Fail_Not_Present" 1 "Fail_Present";
VAL_ 749 FuelConsumption_GAG 65535 "SNA";
VAL_ 749 GearShiftIndication 0 "No_Gearshift_Suggestion_by_ECM" 1 "Downshift_Suggestion_by_ECM" 2 "Upshift_Suggestion_by_ECM" 3 "Strategy_Not_Available_ECM_Fail";
VAL_ 749 RaceShiftLight 0 "No_RaceGearshift_Suggestion" 1 "Urgency_Level_1" 2 "Urgency_Level_2" 3 "Urgency_Level_3";
VAL_ 751 ActualGearGSI 0 "Neutral" 1 "ForwardGear_1" 2 "ForwardGear_2" 3 "ForwardGear_3" 4 "ForwardGear_4" 5 "ForwardGear_5" 6 "ForwardGear_6" 7 "ReverseGear" 8 "ForwardGear_7" 9 "ForwardGear_8" 10 "ForwardGear_9" 15 "SNA";
VAL_ 751 BoostPressureIndication 255 "SNA";
VAL_ 751 DPFRgnMode 0 "Regen_Not_Active" 1 "Regen_Active";
VAL_ 751 SAMInfo 0 "SAMOFF" 1 "Engine_OFF" 2 "Cranking_management" 3 "ColdEngineManagement" 4 "PassiveBoost" 5 "Steady_State" 6 "RegenerativeBraking" 7 "QuickCharge" 8 "Auto_Shut_OFF" 9 "Shut_OFF" 10 "SAM_recovery" 11 "Battery_Regeneration" 12 "Not_Used" 13 "Not_Used" 14 "Not_Used" 15 "SNA";
VAL_ 751 StartRelayBCMFeedbackFault 0 "False" 1 "True";
VAL_ 751 StartRelayECMFeedbackFault 0 "False" 1 "True";
VAL_ 751 StopStartFaultSts 0 "False" 1 "True";
VAL_ 751 SuggestedGearGSI 0 "Neutral" 1 "ForwardGear_1" 2 "ForwardGear_2" 3 "ForwardGear_3" 4 "ForwardGear_4" 5 "ForwardGear_5" 6 "ForwardGear_6" 7 "ReverseGear" 8 "ForwardGear_7" 9 "ForwardGear_8" 10 "ForwardGear_9" 15 "SNA";
VAL_ 550 DrivelineSts 0 "Open" 1 "Closed" 3 "SNA";
VAL_ 550 SpStChmRq 0 "Not_Active" 1 "Active";
VAL_ 550 SpStDispstat 0 "NONE" 1 "STARTING" 2 "START" 3 "ACTIVE" 4 "D_OR_SB" 5 "D_AND_SB" 6 "DR_INHIB" 7 "TX_INHIB" 8 "KEY" 9 "BATT" 10 "SYSFLT" 11 "NR" 12 "READY" 13 "OFF" 14 "HOOD" 15 "PEDAL" 16 "BATT_CHG" 17 "TM" 18 "T4WD_L" 19 "LF" 20 "INCLINE" 21 "AMB_TEMP" 22 "ENG_TEMP" 23 "SB" 24 "DR_AJAR" 25 "CABIN" 26 "MAX_HVAC" 27 "FT_DEFROST" 28 "EBL" 29 "ST_WHEEL" 30 "ENG_TEMP_HI" 31 "ENG_TEMP_LO" 32 "PRK_BRK_INHIB" 33 "PARK_INHIBIT" 34 "HOOD_INHIBIT" 35 "DPF_REGEN" 36 "PSG_DR_INHIB" 37 "ACC_SET" 38 "BATT_HIGH" 39 "BATT_LOW" 63 "SNA";
VAL_ 550 SpStIndRq 0 "Not_Active" 1 "Active";
VAL_ 550 SpStSwStat 0 "OFF" 1 "CONT" 2 "BLINK" 3 "SNA";
VAL_ 550 SpStWarnStat 0 "NONE" 1 "STARTING" 2 "START" 3 "ACTIVE" 4 "D_OR_SB" 5 "D_AND_SB" 6 "DR_INHIB" 7 "TX_INHIB" 8 "KEY" 9 "BATT" 10 "SYSFLT" 11 "PRK_BRK_INHIB" 12 "HOOD_INHIB" 13 "PSG_DR_INHIB" 14 "PARK_INHIB" 15 "SNA";
VAL_ 1854 HighBeamSts 0 "OFF" 1 "ON";
VAL_ 1854 LHParkingLightSts 0 "OFF" 1 "ON";
VAL_ 1854 LHTurnLightFault 0 "False" 1 "True";
VAL_ 1854 LHTurnSignalSts 0 "OFF" 1 "ON";
VAL_ 1854 ParkingLightFault 0 "False" 1 "True";
VAL_ 1854 RHParkingLightSts 0 "OFF" 1 "ON";
VAL_ 1854 RHTurnLightFault 0 "False" 1 "True";
VAL_ 1854 RHTurnSignalSts 0 "OFF" 1 "ON";
VAL_ 1854 StopLightFault 0 "False" 1 "True";
VAL_ 1854 StopLightSts 0 "OFF" 1 "ON";
VAL_ 222 ElectricSteeringFailSts 0 "Fail_Not_Present" 1 "Fail_Present";
VAL_ 222 EngineFanRequestActivation 0 "False" 1 "True";
VAL_ 222 LwsAngle 65535 "SNA";
VAL_ 222 LwsCalibration 0 "Not_calibrated" 1 "Calibrated";
VAL_ 222 LWSFailSts 0 "Fail_not_Present" 1 "Fail_Present_Ignition_Latched" 2 "Fail_Present_Recoverable" 3 "Fail_Present_Battery_Disconnection";
VAL_ 222 LwsSpeed 4095 "SNA";
VAL_ 100 ControlEncodingReq 5 "ControlEncoding_ENQ" 6 "ControlEncoding_ACK" 21 "ControlEncoding_NACK" 132 "ControlEncoding_EOTp" 133 "ControlEncoding_ENQp" 134 "ControlEncoding_ACK1p" 135 "ControlEncoding_ACK2p";
VAL_ 100 f1_1 0 "Val1_f1_1" 81 "Val5_f1_1" 119 "Val2_f1_1" 145 "Val3_f1_1" 159 "Val4_f1_1";
VAL_ 100 f1_2 0 "Val1_f1_2" 5 "Val2_f1_2" 13 "Val4_f1_2" 14 "Val3_f1_2" 15 "Val5_f1_2";
VAL_ 100 rnd_1 0 "Val1_rnd_1" 58 "Val2_rnd_1" 59 "Val3_rnd_1" 60 "Val4_rnd_1" 61 "Val5_rnd_1" 62 "Val6_rnd_1" 63 "Val7_rnd_1" 64 "Val8_rnd_1" 65 "Val9_rnd_1" 66 "ValA_rnd_1" 67 "ValB_rnd_1" 68 "ValC_rnd_1" 69 "ValD_rnd_1" 70 "ValE_rnd_1" 71 "ValF_rnd_1";
VAL_ 100 rnd_2 0 "Val1_rnd_2" 26 "Val3_rnd_2" 43 "Val5_rnd_2" 79 "Val2_rnd_2" 168 "Val4_rnd_2";
VAL_ 100 rnd_3 0 "Val1_rnd_3" 19 "Val3_rnd_3" 21 "Val5_rnd_3" 32 "Val4_rnd_3" 129 "Val2_rnd_3";
VAL_ 100 rnd_4 0 "Val1_rnd_4" 170 "Val5_rnd_4" 203 "Val2_rnd_4" 221 "Val3_rnd_4" 238 "Val4_rnd_4";
VAL_ 104 MKKey_3 36 "FIX__MKKey_3";
VAL_ 104 MKKey_4 214 "FIX__MKKey_4";
VAL_ 104 MKKey_5 1 "FIX__MKKey_5";
VAL_ 104 MKKey_6 77 "FIX__MKKey_6";
VAL_ 104 MKKey1org21 84 "FIX__MKKey_1";
VAL_ 104 MKKey2org22 85 "FIX__MKKey_2";
